VERSION ""

NS_ :

BS_:

BU_: BMS_Controller NF_Controller NF_Controllers

BO_ 2499762532 BATT_Diagnostic_Pack_A: 8 BMS_Controller
 SG_ BATT_01_vBrickOverSev m0 : 2|2@1+ (1,0) [0|3] ""  NF_Controller
 SG_ BATT_01_vBrickOverMod m0 : 0|2@1+ (1,0) [0|3] ""  NF_Controller
 SG_ BATT_01_vBrickOverWar m0 : 14|2@1+ (1,0) [0|3] ""  NF_Controller
 SG_ BATT_01_HostQuiet m0 : 12|2@1+ (1,0) [0|3] ""  NF_Controller
 SG_ BATT_01_vBrickUnderMod m0 : 10|2@1+ (1,0) [0|3] ""  NF_Controller
 SG_ BATT_01_vBrickUnderWar m0 : 8|2@1+ (1,0) [0|3] ""  NF_Controller
 SG_ BATT_01_TempModuleOverSev m0 : 22|2@1+ (1,0) [0|3] ""  NF_Controller
 SG_ BATT_01_TempModuleOverMod m0 : 20|2@1+ (1,0) [0|3] ""  NF_Controller
 SG_ BATT_01_TempModuleOverWar m0 : 18|2@1+ (1,0) [0|3] ""  NF_Controller
 SG_ BATT_01_TempModuleUnderSev m0 : 16|2@1+ (1,0) [0|3] ""  NF_Controller
 SG_ BATT_01_TempModuleUnderMod m0 : 30|2@1+ (1,0) [0|3] ""  NF_Controller
 SG_ BATT_01_TempModuleUnderWar m0 : 28|2@1+ (1,0) [0|3] ""  NF_Controller
 SG_ BATT_01_iOverchargesev m0 : 26|2@1+ (1,0) [0|3] ""  NF_Controller
 SG_ BATT_01_iOverdischargesev m0 : 24|2@1+ (1,0) [0|3] ""  NF_Controller
 SG_ BATT_01_iOverHardware m0 : 38|2@1+ (1,0) [0|3] ""  NF_Controller
 SG_ BATT_01_PosDcContStuckOpen m0 : 36|2@1+ (1,0) [0|3] ""  NF_Controller
 SG_ BATT_01_PosDcContWelded m0 : 34|2@1+ (1,0) [0|3] ""  NF_Controller
 SG_ BATT_01_NegDcContStuckOpen m0 : 32|2@1+ (1,0) [0|3] ""  NF_Controller
 SG_ BATT_01_NegDcContWelded m0 : 46|2@1+ (1,0) [0|3] ""  NF_Controller
 SG_ BATT_01_PrechgTooFast m0 : 44|2@1+ (1,0) [0|3] ""  NF_Controller
 SG_ BATT_01_PrechgContWelded m0 : 42|2@1+ (1,0) [0|3] ""  NF_Controller
 SG_ BATT_01_PrechgTimeout m0 : 40|2@1+ (1,0) [0|3] ""  NF_Controller
 SG_ BATT_01_PrechgContStuckOpen m0 : 54|2@1+ (1,0) [0|3] ""  NF_Controller
 SG_ BATT_01_ModuleImbalance m0 : 52|2@1+ (1,0) [0|3] ""  NF_Controller
 SG_ BATT_01_ModuleMIA m0 : 50|2@1+ (1,0) [0|3] ""  NF_Controller
 SG_ BATT_01_SensePackVoltError m0 : 48|2@1+ (1,0) [0|3] ""  NF_Controller
 SG_ BATT_01_SenseLoadVoltError m0 : 62|2@1+ (1,0) [0|3] ""  NF_Controller
 SG_ BATT_01_SenseShuntError m0 : 60|2@1+ (1,0) [0|3] ""  NF_Controller
 SG_ BATT_01_SenseFcVoltErrorr m0 : 58|2@1+ (1,0) [0|3] ""  NF_Controller
 SG_ BATT_01_Placeholder14 m0 : 56|2@1+ (1,0) [0|3] ""  NF_Controller
 SG_ BATT_02_vBrickOverSev m1 : 2|2@1+ (1,0) [0|3] ""  NF_Controller
 SG_ BATT_02_vBrickOverMod m1 : 0|2@1+ (1,0) [0|3] ""  NF_Controller
 SG_ BATT_02_vBrickOverWar m1 : 14|2@1+ (1,0) [0|3] ""  NF_Controller
 SG_ BATT_02_HostQuiet m1 : 12|2@1+ (1,0) [0|3] ""  NF_Controller
 SG_ BATT_02_vBrickUnderMod m1 : 10|2@1+ (1,0) [0|3] ""  NF_Controller
 SG_ BATT_02_vBrickUnderWar m1 : 8|2@1+ (1,0) [0|3] ""  NF_Controller
 SG_ BATT_02_TempModuleOverSev m1 : 22|2@1+ (1,0) [0|3] ""  NF_Controller
 SG_ BATT_02_TempModuleOverMod m1 : 20|2@1+ (1,0) [0|3] ""  NF_Controller
 SG_ BATT_02_TempModuleOverWar m1 : 18|2@1+ (1,0) [0|3] ""  NF_Controller
 SG_ BATT_02_TempModuleUnderSev m1 : 16|2@1+ (1,0) [0|3] ""  NF_Controller
 SG_ BATT_02_TempModuleUnderMod m1 : 30|2@1+ (1,0) [0|3] ""  NF_Controller
 SG_ BATT_02_TempModuleUnderWar m1 : 28|2@1+ (1,0) [0|3] ""  NF_Controller
 SG_ BATT_02_iOverchargesev m1 : 26|2@1+ (1,0) [0|3] ""  NF_Controller
 SG_ BATT_02_iOverdischargesev m1 : 24|2@1+ (1,0) [0|3] ""  NF_Controller
 SG_ BATT_02_iOverHardware m1 : 38|2@1+ (1,0) [0|3] ""  NF_Controller
 SG_ BATT_02_PosDcContStuckOpen m1 : 36|2@1+ (1,0) [0|3] ""  NF_Controller
 SG_ BATT_02_PosDcContWelded m1 : 34|2@1+ (1,0) [0|3] ""  NF_Controller
 SG_ BATT_02_NegDcContStuckOpen m1 : 32|2@1+ (1,0) [0|3] ""  NF_Controller
 SG_ BATT_02_NegDcContWelded m1 : 46|2@1+ (1,0) [0|3] ""  NF_Controller
 SG_ BATT_02_PrechgTooFast m1 : 44|2@1+ (1,0) [0|3] ""  NF_Controller
 SG_ BATT_02_PrechgContWelded m1 : 42|2@1+ (1,0) [0|3] ""  NF_Controller
 SG_ BATT_02_PrechgTimeout m1 : 40|2@1+ (1,0) [0|3] ""  NF_Controller
 SG_ BATT_02_PrechgContStuckOpen m1 : 54|2@1+ (1,0) [0|3] ""  NF_Controller
 SG_ BATT_02_ModuleImbalance m1 : 52|2@1+ (1,0) [0|3] ""  NF_Controller
 SG_ BATT_02_ModuleMIA m1 : 50|2@1+ (1,0) [0|3] ""  NF_Controller
 SG_ BATT_02_SensePackVoltError m1 : 48|2@1+ (1,0) [0|3] ""  NF_Controller
 SG_ BATT_02_SenseLoadVoltError m1 : 62|2@1+ (1,0) [0|3] ""  NF_Controller
 SG_ BATT_02_SenseShuntError m1 : 60|2@1+ (1,0) [0|3] ""  NF_Controller
 SG_ BATT_02_SenseFcVoltErrorr m1 : 58|2@1+ (1,0) [0|3] ""  NF_Controller
 SG_ BATT_02_Placeholder14 m1 : 56|2@1+ (1,0) [0|3] ""  NF_Controller
 SG_ BATT_03_vBrickOverSev m2 : 2|2@1+ (1,0) [0|3] ""  NF_Controller
 SG_ BATT_03_vBrickOverMod m2 : 0|2@1+ (1,0) [0|3] ""  NF_Controller
 SG_ BATT_03_vBrickOverWar m2 : 14|2@1+ (1,0) [0|3] ""  NF_Controller
 SG_ BATT_03_HostQuiet m2 : 12|2@1+ (1,0) [0|3] ""  NF_Controller
 SG_ BATT_03_vBrickUnderMod m2 : 10|2@1+ (1,0) [0|3] ""  NF_Controller
 SG_ BATT_03_vBrickUnderWar m2 : 8|2@1+ (1,0) [0|3] ""  NF_Controller
 SG_ BATT_03_TempModuleOverSev m2 : 22|2@1+ (1,0) [0|3] ""  NF_Controller
 SG_ BATT_03_TempModuleOverMod m2 : 20|2@1+ (1,0) [0|3] ""  NF_Controller
 SG_ BATT_03_TempModuleOverWar m2 : 18|2@1+ (1,0) [0|3] ""  NF_Controller
 SG_ BATT_03_TempModuleUnderSev m2 : 16|2@1+ (1,0) [0|3] ""  NF_Controller
 SG_ BATT_03_TempModuleUnderMod m2 : 30|2@1+ (1,0) [0|3] ""  NF_Controller
 SG_ BATT_03_TempModuleUnderWar m2 : 28|2@1+ (1,0) [0|3] ""  NF_Controller
 SG_ BATT_03_iOverchargesev m2 : 26|2@1+ (1,0) [0|3] ""  NF_Controller
 SG_ BATT_03_iOverdischargesev m2 : 24|2@1+ (1,0) [0|3] ""  NF_Controller
 SG_ BATT_03_iOverHardware m2 : 38|2@1+ (1,0) [0|3] ""  NF_Controller
 SG_ BATT_03_PosDcContStuckOpen m2 : 36|2@1+ (1,0) [0|3] ""  NF_Controller
 SG_ BATT_03_PosDcContWelded m2 : 34|2@1+ (1,0) [0|3] ""  NF_Controller
 SG_ BATT_03_NegDcContStuckOpen m2 : 32|2@1+ (1,0) [0|3] ""  NF_Controller
 SG_ BATT_03_NegDcContWelded m2 : 46|2@1+ (1,0) [0|3] ""  NF_Controller
 SG_ BATT_03_PrechgTooFast m2 : 44|2@1+ (1,0) [0|3] ""  NF_Controller
 SG_ BATT_03_PrechgContWelded m2 : 42|2@1+ (1,0) [0|3] ""  NF_Controller
 SG_ BATT_03_PrechgTimeout m2 : 40|2@1+ (1,0) [0|3] ""  NF_Controller
 SG_ BATT_03_PrechgContStuckOpen m2 : 54|2@1+ (1,0) [0|3] ""  NF_Controller
 SG_ BATT_03_ModuleImbalance m2 : 52|2@1+ (1,0) [0|3] ""  NF_Controller
 SG_ BATT_03_ModuleMIA m2 : 50|2@1+ (1,0) [0|3] ""  NF_Controller
 SG_ BATT_03_SensePackVoltError m2 : 48|2@1+ (1,0) [0|3] ""  NF_Controller
 SG_ BATT_03_SenseLoadVoltError m2 : 62|2@1+ (1,0) [0|3] ""  NF_Controller
 SG_ BATT_03_SenseShuntError m2 : 60|2@1+ (1,0) [0|3] ""  NF_Controller
 SG_ BATT_03_SenseFcVoltErrorr m2 : 58|2@1+ (1,0) [0|3] ""  NF_Controller
 SG_ BATT_03_Placeholder14 m2 : 56|2@1+ (1,0) [0|3] ""  NF_Controller
 SG_ BATT_04_vBrickOverSev m3 : 2|2@1+ (1,0) [0|3] ""  NF_Controller
 SG_ BATT_04_vBrickOverMod m3 : 0|2@1+ (1,0) [0|3] ""  NF_Controller
 SG_ BATT_04_vBrickOverWar m3 : 14|2@1+ (1,0) [0|3] ""  NF_Controller
 SG_ BATT_04_HostQuiet m3 : 12|2@1+ (1,0) [0|3] ""  NF_Controller
 SG_ BATT_04_vBrickUnderMod m3 : 10|2@1+ (1,0) [0|3] ""  NF_Controller
 SG_ BATT_04_vBrickUnderWar m3 : 8|2@1+ (1,0) [0|3] ""  NF_Controller
 SG_ BATT_04_TempModuleOverSev m3 : 22|2@1+ (1,0) [0|3] ""  NF_Controller
 SG_ BATT_04_TempModuleOverMod m3 : 20|2@1+ (1,0) [0|3] ""  NF_Controller
 SG_ BATT_04_TempModuleOverWar m3 : 18|2@1+ (1,0) [0|3] ""  NF_Controller
 SG_ BATT_04_TempModuleUnderSev m3 : 16|2@1+ (1,0) [0|3] ""  NF_Controller
 SG_ BATT_04_TempModuleUnderMod m3 : 30|2@1+ (1,0) [0|3] ""  NF_Controller
 SG_ BATT_04_TempModuleUnderWar m3 : 28|2@1+ (1,0) [0|3] ""  NF_Controller
 SG_ BATT_04_iOverchargesev m3 : 26|2@1+ (1,0) [0|3] ""  NF_Controller
 SG_ BATT_04_iOverdischargesev m3 : 24|2@1+ (1,0) [0|3] ""  NF_Controller
 SG_ BATT_04_iOverHardware m3 : 38|2@1+ (1,0) [0|3] ""  NF_Controller
 SG_ BATT_04_PosDcContStuckOpen m3 : 36|2@1+ (1,0) [0|3] ""  NF_Controller
 SG_ BATT_04_PosDcContWelded m3 : 34|2@1+ (1,0) [0|3] ""  NF_Controller
 SG_ BATT_04_NegDcContStuckOpen m3 : 32|2@1+ (1,0) [0|3] ""  NF_Controller
 SG_ BATT_04_NegDcContWelded m3 : 46|2@1+ (1,0) [0|3] ""  NF_Controller
 SG_ BATT_04_PrechgTooFast m3 : 44|2@1+ (1,0) [0|3] ""  NF_Controller
 SG_ BATT_04_PrechgContWelded m3 : 42|2@1+ (1,0) [0|3] ""  NF_Controller
 SG_ BATT_04_PrechgTimeout m3 : 40|2@1+ (1,0) [0|3] ""  NF_Controller
 SG_ BATT_04_PrechgContStuckOpen m3 : 54|2@1+ (1,0) [0|3] ""  NF_Controller
 SG_ BATT_04_ModuleImbalance m3 : 52|2@1+ (1,0) [0|3] ""  NF_Controller
 SG_ BATT_04_ModuleMIA m3 : 50|2@1+ (1,0) [0|3] ""  NF_Controller
 SG_ BATT_04_SensePackVoltError m3 : 48|2@1+ (1,0) [0|3] ""  NF_Controller
 SG_ BATT_04_SenseLoadVoltError m3 : 62|2@1+ (1,0) [0|3] ""  NF_Controller
 SG_ BATT_04_SenseShuntError m3 : 60|2@1+ (1,0) [0|3] ""  NF_Controller
 SG_ BATT_04_SenseFcVoltErrorr m3 : 58|2@1+ (1,0) [0|3] ""  NF_Controller
 SG_ BATT_04_Placeholder14 m3 : 56|2@1+ (1,0) [0|3] ""  NF_Controller
 SG_ BATT_05_vBrickOverSev m4 : 2|2@1+ (1,0) [0|3] ""  NF_Controller
 SG_ BATT_05_vBrickOverMod m4 : 0|2@1+ (1,0) [0|3] ""  NF_Controller
 SG_ BATT_05_vBrickOverWar m4 : 14|2@1+ (1,0) [0|3] ""  NF_Controller
 SG_ BATT_05_HostQuiet m4 : 12|2@1+ (1,0) [0|3] ""  NF_Controller
 SG_ BATT_05_vBrickUnderMod m4 : 10|2@1+ (1,0) [0|3] ""  NF_Controller
 SG_ BATT_05_vBrickUnderWar m4 : 8|2@1+ (1,0) [0|3] ""  NF_Controller
 SG_ BATT_05_TempModuleOverSev m4 : 22|2@1+ (1,0) [0|3] ""  NF_Controller
 SG_ BATT_05_TempModuleOverMod m4 : 20|2@1+ (1,0) [0|3] ""  NF_Controller
 SG_ BATT_05_TempModuleOverWar m4 : 18|2@1+ (1,0) [0|3] ""  NF_Controller
 SG_ BATT_05_TempModuleUnderSev m4 : 16|2@1+ (1,0) [0|3] ""  NF_Controller
 SG_ BATT_05_TempModuleUnderMod m4 : 30|2@1+ (1,0) [0|3] ""  NF_Controller
 SG_ BATT_05_TempModuleUnderWar m4 : 28|2@1+ (1,0) [0|3] ""  NF_Controller
 SG_ BATT_05_iOverchargesev m4 : 26|2@1+ (1,0) [0|3] ""  NF_Controller
 SG_ BATT_05_iOverdischargesev m4 : 24|2@1+ (1,0) [0|3] ""  NF_Controller
 SG_ BATT_05_iOverHardware m4 : 38|2@1+ (1,0) [0|3] ""  NF_Controller
 SG_ BATT_05_PosDcContStuckOpen m4 : 36|2@1+ (1,0) [0|3] ""  NF_Controller
 SG_ BATT_05_PosDcContWelded m4 : 34|2@1+ (1,0) [0|3] ""  NF_Controller
 SG_ BATT_05_NegDcContStuckOpen m4 : 32|2@1+ (1,0) [0|3] ""  NF_Controller
 SG_ BATT_05_NegDcContWelded m4 : 46|2@1+ (1,0) [0|3] ""  NF_Controller
 SG_ BATT_05_PrechgTooFast m4 : 44|2@1+ (1,0) [0|3] ""  NF_Controller
 SG_ BATT_05_PrechgContWelded m4 : 42|2@1+ (1,0) [0|3] ""  NF_Controller
 SG_ BATT_05_PrechgTimeout m4 : 40|2@1+ (1,0) [0|3] ""  NF_Controller
 SG_ BATT_05_PrechgContStuckOpen m4 : 54|2@1+ (1,0) [0|3] ""  NF_Controller
 SG_ BATT_05_ModuleImbalance m4 : 52|2@1+ (1,0) [0|3] ""  NF_Controller
 SG_ BATT_05_ModuleMIA m4 : 50|2@1+ (1,0) [0|3] ""  NF_Controller
 SG_ BATT_05_SensePackVoltError m4 : 48|2@1+ (1,0) [0|3] ""  NF_Controller
 SG_ BATT_05_SenseLoadVoltError m4 : 62|2@1+ (1,0) [0|3] ""  NF_Controller
 SG_ BATT_05_SenseShuntError m4 : 60|2@1+ (1,0) [0|3] ""  NF_Controller
 SG_ BATT_05_SenseFcVoltErrorr m4 : 58|2@1+ (1,0) [0|3] ""  NF_Controller
 SG_ BATT_05_Placeholder14 m4 : 56|2@1+ (1,0) [0|3] ""  NF_Controller
 SG_ BATT_06_vBrickOverSev m5 : 2|2@1+ (1,0) [0|3] ""  NF_Controller
 SG_ BATT_06_vBrickOverMod m5 : 0|2@1+ (1,0) [0|3] ""  NF_Controller
 SG_ BATT_06_vBrickOverWar m5 : 14|2@1+ (1,0) [0|3] ""  NF_Controller
 SG_ BATT_06_HostQuiet m5 : 12|2@1+ (1,0) [0|3] ""  NF_Controller
 SG_ BATT_06_vBrickUnderMod m5 : 10|2@1+ (1,0) [0|3] ""  NF_Controller
 SG_ BATT_06_vBrickUnderWar m5 : 8|2@1+ (1,0) [0|3] ""  NF_Controller
 SG_ BATT_06_TempModuleOverSev m5 : 22|2@1+ (1,0) [0|3] ""  NF_Controller
 SG_ BATT_06_TempModuleOverMod m5 : 20|2@1+ (1,0) [0|3] ""  NF_Controller
 SG_ BATT_06_TempModuleOverWar m5 : 18|2@1+ (1,0) [0|3] ""  NF_Controller
 SG_ BATT_06_TempModuleUnderSev m5 : 16|2@1+ (1,0) [0|3] ""  NF_Controller
 SG_ BATT_06_TempModuleUnderMod m5 : 30|2@1+ (1,0) [0|3] ""  NF_Controller
 SG_ BATT_06_TempModuleUnderWar m5 : 28|2@1+ (1,0) [0|3] ""  NF_Controller
 SG_ BATT_06_iOverchargesev m5 : 26|2@1+ (1,0) [0|3] ""  NF_Controller
 SG_ BATT_06_iOverdischargesev m5 : 24|2@1+ (1,0) [0|3] ""  NF_Controller
 SG_ BATT_06_iOverHardware m5 : 38|2@1+ (1,0) [0|3] ""  NF_Controller
 SG_ BATT_06_PosDcContStuckOpen m5 : 36|2@1+ (1,0) [0|3] ""  NF_Controller
 SG_ BATT_06_PosDcContWelded m5 : 34|2@1+ (1,0) [0|3] ""  NF_Controller
 SG_ BATT_06_NegDcContStuckOpen m5 : 32|2@1+ (1,0) [0|3] ""  NF_Controller
 SG_ BATT_06_NegDcContWelded m5 : 46|2@1+ (1,0) [0|3] ""  NF_Controller
 SG_ BATT_06_PrechgTooFast m5 : 44|2@1+ (1,0) [0|3] ""  NF_Controller
 SG_ BATT_06_PrechgContWelded m5 : 42|2@1+ (1,0) [0|3] ""  NF_Controller
 SG_ BATT_06_PrechgTimeout m5 : 40|2@1+ (1,0) [0|3] ""  NF_Controller
 SG_ BATT_06_PrechgContStuckOpen m5 : 54|2@1+ (1,0) [0|3] ""  NF_Controller
 SG_ BATT_06_ModuleImbalance m5 : 52|2@1+ (1,0) [0|3] ""  NF_Controller
 SG_ BATT_06_ModuleMIA m5 : 50|2@1+ (1,0) [0|3] ""  NF_Controller
 SG_ BATT_06_SensePackVoltError m5 : 48|2@1+ (1,0) [0|3] ""  NF_Controller
 SG_ BATT_06_SenseLoadVoltError m5 : 62|2@1+ (1,0) [0|3] ""  NF_Controller
 SG_ BATT_06_SenseShuntError m5 : 60|2@1+ (1,0) [0|3] ""  NF_Controller
 SG_ BATT_06_SenseFcVoltErrorr m5 : 58|2@1+ (1,0) [0|3] ""  NF_Controller
 SG_ BATT_06_Placeholder14 m5 : 56|2@1+ (1,0) [0|3] ""  NF_Controller
 SG_ BATT_07_vBrickOverSev m6 : 2|2@1+ (1,0) [0|3] ""  NF_Controller
 SG_ BATT_07_vBrickOverMod m6 : 0|2@1+ (1,0) [0|3] ""  NF_Controller
 SG_ BATT_07_vBrickOverWar m6 : 14|2@1+ (1,0) [0|3] ""  NF_Controller
 SG_ BATT_07_HostQuiet m6 : 12|2@1+ (1,0) [0|3] ""  NF_Controller
 SG_ BATT_07_vBrickUnderMod m6 : 10|2@1+ (1,0) [0|3] ""  NF_Controller
 SG_ BATT_07_vBrickUnderWar m6 : 8|2@1+ (1,0) [0|3] ""  NF_Controller
 SG_ BATT_07_TempModuleOverSev m6 : 22|2@1+ (1,0) [0|3] ""  NF_Controller
 SG_ BATT_07_TempModuleOverMod m6 : 20|2@1+ (1,0) [0|3] ""  NF_Controller
 SG_ BATT_07_TempModuleOverWar m6 : 18|2@1+ (1,0) [0|3] ""  NF_Controller
 SG_ BATT_07_TempModuleUnderSev m6 : 16|2@1+ (1,0) [0|3] ""  NF_Controller
 SG_ BATT_07_TempModuleUnderMod m6 : 30|2@1+ (1,0) [0|3] ""  NF_Controller
 SG_ BATT_07_TempModuleUnderWar m6 : 28|2@1+ (1,0) [0|3] ""  NF_Controller
 SG_ BATT_07_iOverchargesev m6 : 26|2@1+ (1,0) [0|3] ""  NF_Controller
 SG_ BATT_07_iOverdischargesev m6 : 24|2@1+ (1,0) [0|3] ""  NF_Controller
 SG_ BATT_07_iOverHardware m6 : 38|2@1+ (1,0) [0|3] ""  NF_Controller
 SG_ BATT_07_PosDcContStuckOpen m6 : 36|2@1+ (1,0) [0|3] ""  NF_Controller
 SG_ BATT_07_PosDcContWelded m6 : 34|2@1+ (1,0) [0|3] ""  NF_Controller
 SG_ BATT_07_NegDcContStuckOpen m6 : 32|2@1+ (1,0) [0|3] ""  NF_Controller
 SG_ BATT_07_NegDcContWelded m6 : 46|2@1+ (1,0) [0|3] ""  NF_Controller
 SG_ BATT_07_PrechgTooFast m6 : 44|2@1+ (1,0) [0|3] ""  NF_Controller
 SG_ BATT_07_PrechgContWelded m6 : 42|2@1+ (1,0) [0|3] ""  NF_Controller
 SG_ BATT_07_PrechgTimeout m6 : 40|2@1+ (1,0) [0|3] ""  NF_Controller
 SG_ BATT_07_PrechgContStuckOpen m6 : 54|2@1+ (1,0) [0|3] ""  NF_Controller
 SG_ BATT_07_ModuleImbalance m6 : 52|2@1+ (1,0) [0|3] ""  NF_Controller
 SG_ BATT_07_ModuleMIA m6 : 50|2@1+ (1,0) [0|3] ""  NF_Controller
 SG_ BATT_07_SensePackVoltError m6 : 48|2@1+ (1,0) [0|3] ""  NF_Controller
 SG_ BATT_07_SenseLoadVoltError m6 : 62|2@1+ (1,0) [0|3] ""  NF_Controller
 SG_ BATT_07_SenseShuntError m6 : 60|2@1+ (1,0) [0|3] ""  NF_Controller
 SG_ BATT_07_SenseFcVoltErrorr m6 : 58|2@1+ (1,0) [0|3] ""  NF_Controller
 SG_ BATT_07_Placeholder14 m6 : 56|2@1+ (1,0) [0|3] ""  NF_Controller
 SG_ BATT_08_vBrickOverSev m7 : 2|2@1+ (1,0) [0|3] ""  NF_Controller
 SG_ BATT_08_vBrickOverMod m7 : 0|2@1+ (1,0) [0|3] ""  NF_Controller
 SG_ BATT_08_vBrickOverWar m7 : 14|2@1+ (1,0) [0|3] ""  NF_Controller
 SG_ BATT_08_HostQuiet m7 : 12|2@1+ (1,0) [0|3] ""  NF_Controller
 SG_ BATT_08_vBrickUnderMod m7 : 10|2@1+ (1,0) [0|3] ""  NF_Controller
 SG_ BATT_08_vBrickUnderWar m7 : 8|2@1+ (1,0) [0|3] ""  NF_Controller
 SG_ BATT_08_TempModuleOverSev m7 : 22|2@1+ (1,0) [0|3] ""  NF_Controller
 SG_ BATT_08_TempModuleOverMod m7 : 20|2@1+ (1,0) [0|3] ""  NF_Controller
 SG_ BATT_08_TempModuleOverWar m7 : 18|2@1+ (1,0) [0|3] ""  NF_Controller
 SG_ BATT_08_TempModuleUnderSev m7 : 16|2@1+ (1,0) [0|3] ""  NF_Controller
 SG_ BATT_08_TempModuleUnderMod m7 : 30|2@1+ (1,0) [0|3] ""  NF_Controller
 SG_ BATT_08_TempModuleUnderWar m7 : 28|2@1+ (1,0) [0|3] ""  NF_Controller
 SG_ BATT_08_iOverchargesev m7 : 26|2@1+ (1,0) [0|3] ""  NF_Controller
 SG_ BATT_08_iOverdischargesev m7 : 24|2@1+ (1,0) [0|3] ""  NF_Controller
 SG_ BATT_08_iOverHardware m7 : 38|2@1+ (1,0) [0|3] ""  NF_Controller
 SG_ BATT_08_PosDcContStuckOpen m7 : 36|2@1+ (1,0) [0|3] ""  NF_Controller
 SG_ BATT_08_PosDcContWelded m7 : 34|2@1+ (1,0) [0|3] ""  NF_Controller
 SG_ BATT_08_NegDcContStuckOpen m7 : 32|2@1+ (1,0) [0|3] ""  NF_Controller
 SG_ BATT_08_NegDcContWelded m7 : 46|2@1+ (1,0) [0|3] ""  NF_Controller
 SG_ BATT_08_PrechgTooFast m7 : 44|2@1+ (1,0) [0|3] ""  NF_Controller
 SG_ BATT_08_PrechgContWelded m7 : 42|2@1+ (1,0) [0|3] ""  NF_Controller
 SG_ BATT_08_PrechgTimeout m7 : 40|2@1+ (1,0) [0|3] ""  NF_Controller
 SG_ BATT_08_PrechgContStuckOpen m7 : 54|2@1+ (1,0) [0|3] ""  NF_Controller
 SG_ BATT_08_ModuleImbalance m7 : 52|2@1+ (1,0) [0|3] ""  NF_Controller
 SG_ BATT_08_ModuleMIA m7 : 50|2@1+ (1,0) [0|3] ""  NF_Controller
 SG_ BATT_08_SensePackVoltError m7 : 48|2@1+ (1,0) [0|3] ""  NF_Controller
 SG_ BATT_08_SenseLoadVoltError m7 : 62|2@1+ (1,0) [0|3] ""  NF_Controller
 SG_ BATT_08_SenseShuntError m7 : 60|2@1+ (1,0) [0|3] ""  NF_Controller
 SG_ BATT_08_SenseFcVoltErrorr m7 : 58|2@1+ (1,0) [0|3] ""  NF_Controller
 SG_ BATT_08_Placeholder14 m7 : 56|2@1+ (1,0) [0|3] ""  NF_Controller
 SG_ BATT_09_vBrickOverSev m8 : 2|2@1+ (1,0) [0|3] ""  NF_Controller
 SG_ BATT_09_vBrickOverMod m8 : 0|2@1+ (1,0) [0|3] ""  NF_Controller
 SG_ BATT_09_vBrickOverWar m8 : 14|2@1+ (1,0) [0|3] ""  NF_Controller
 SG_ BATT_09_HostQuiet m8 : 12|2@1+ (1,0) [0|3] ""  NF_Controller
 SG_ BATT_09_vBrickUnderMod m8 : 10|2@1+ (1,0) [0|3] ""  NF_Controller
 SG_ BATT_09_vBrickUnderWar m8 : 8|2@1+ (1,0) [0|3] ""  NF_Controller
 SG_ BATT_09_TempModuleOverSev m8 : 22|2@1+ (1,0) [0|3] ""  NF_Controller
 SG_ BATT_09_TempModuleOverMod m8 : 20|2@1+ (1,0) [0|3] ""  NF_Controller
 SG_ BATT_09_TempModuleOverWar m8 : 18|2@1+ (1,0) [0|3] ""  NF_Controller
 SG_ BATT_09_TempModuleUnderSev m8 : 16|2@1+ (1,0) [0|3] ""  NF_Controller
 SG_ BATT_09_TempModuleUnderMod m8 : 30|2@1+ (1,0) [0|3] ""  NF_Controller
 SG_ BATT_09_TempModuleUnderWar m8 : 28|2@1+ (1,0) [0|3] ""  NF_Controller
 SG_ BATT_09_iOverchargesev m8 : 26|2@1+ (1,0) [0|3] ""  NF_Controller
 SG_ BATT_09_iOverdischargesev m8 : 24|2@1+ (1,0) [0|3] ""  NF_Controller
 SG_ BATT_09_iOverHardware m8 : 38|2@1+ (1,0) [0|3] ""  NF_Controller
 SG_ BATT_09_PosDcContStuckOpen m8 : 36|2@1+ (1,0) [0|3] ""  NF_Controller
 SG_ BATT_09_PosDcContWelded m8 : 34|2@1+ (1,0) [0|3] ""  NF_Controller
 SG_ BATT_09_NegDcContStuckOpen m8 : 32|2@1+ (1,0) [0|3] ""  NF_Controller
 SG_ BATT_09_NegDcContWelded m8 : 46|2@1+ (1,0) [0|3] ""  NF_Controller
 SG_ BATT_09_PrechgTooFast m8 : 44|2@1+ (1,0) [0|3] ""  NF_Controller
 SG_ BATT_09_PrechgContWelded m8 : 42|2@1+ (1,0) [0|3] ""  NF_Controller
 SG_ BATT_09_PrechgTimeout m8 : 40|2@1+ (1,0) [0|3] ""  NF_Controller
 SG_ BATT_09_PrechgContStuckOpen m8 : 54|2@1+ (1,0) [0|3] ""  NF_Controller
 SG_ BATT_09_ModuleImbalance m8 : 52|2@1+ (1,0) [0|3] ""  NF_Controller
 SG_ BATT_09_ModuleMIA m8 : 50|2@1+ (1,0) [0|3] ""  NF_Controller
 SG_ BATT_09_SensePackVoltError m8 : 48|2@1+ (1,0) [0|3] ""  NF_Controller
 SG_ BATT_09_SenseLoadVoltError m8 : 62|2@1+ (1,0) [0|3] ""  NF_Controller
 SG_ BATT_09_SenseShuntError m8 : 60|2@1+ (1,0) [0|3] ""  NF_Controller
 SG_ BATT_09_SenseFcVoltErrorr m8 : 58|2@1+ (1,0) [0|3] ""  NF_Controller
 SG_ BATT_09_Placeholder14 m8 : 56|2@1+ (1,0) [0|3] ""  NF_Controller
 SG_ BATT_10_vBrickOverSev m9 : 2|2@1+ (1,0) [0|3] ""  NF_Controller
 SG_ BATT_10_vBrickOverMod m9 : 0|2@1+ (1,0) [0|3] ""  NF_Controller
 SG_ BATT_10_vBrickOverWar m9 : 14|2@1+ (1,0) [0|3] ""  NF_Controller
 SG_ BATT_10_HostQuiet m9 : 12|2@1+ (1,0) [0|3] ""  NF_Controller
 SG_ BATT_10_vBrickUnderMod m9 : 10|2@1+ (1,0) [0|3] ""  NF_Controller
 SG_ BATT_10_vBrickUnderWar m9 : 8|2@1+ (1,0) [0|3] ""  NF_Controller
 SG_ BATT_10_TempModuleOverSev m9 : 22|2@1+ (1,0) [0|3] ""  NF_Controller
 SG_ BATT_10_TempModuleOverMod m9 : 20|2@1+ (1,0) [0|3] ""  NF_Controller
 SG_ BATT_10_TempModuleOverWar m9 : 18|2@1+ (1,0) [0|3] ""  NF_Controller
 SG_ BATT_10_TempModuleUnderSev m9 : 16|2@1+ (1,0) [0|3] ""  NF_Controller
 SG_ BATT_10_TempModuleUnderMod m9 : 30|2@1+ (1,0) [0|3] ""  NF_Controller
 SG_ BATT_10_TempModuleUnderWar m9 : 28|2@1+ (1,0) [0|3] ""  NF_Controller
 SG_ BATT_10_iOverchargesev m9 : 26|2@1+ (1,0) [0|3] ""  NF_Controller
 SG_ BATT_10_iOverdischargesev m9 : 24|2@1+ (1,0) [0|3] ""  NF_Controller
 SG_ BATT_10_iOverHardware m9 : 38|2@1+ (1,0) [0|3] ""  NF_Controller
 SG_ BATT_10_PosDcContStuckOpen m9 : 36|2@1+ (1,0) [0|3] ""  NF_Controller
 SG_ BATT_10_PosDcContWelded m9 : 34|2@1+ (1,0) [0|3] ""  NF_Controller
 SG_ BATT_10_NegDcContStuckOpen m9 : 32|2@1+ (1,0) [0|3] ""  NF_Controller
 SG_ BATT_10_NegDcContWelded m9 : 46|2@1+ (1,0) [0|3] ""  NF_Controller
 SG_ BATT_10_PrechgTooFast m9 : 44|2@1+ (1,0) [0|3] ""  NF_Controller
 SG_ BATT_10_PrechgContWelded m9 : 42|2@1+ (1,0) [0|3] ""  NF_Controller
 SG_ BATT_10_PrechgTimeout m9 : 40|2@1+ (1,0) [0|3] ""  NF_Controller
 SG_ BATT_10_PrechgContStuckOpen m9 : 54|2@1+ (1,0) [0|3] ""  NF_Controller
 SG_ BATT_10_ModuleImbalance m9 : 52|2@1+ (1,0) [0|3] ""  NF_Controller
 SG_ BATT_10_ModuleMIA m9 : 50|2@1+ (1,0) [0|3] ""  NF_Controller
 SG_ BATT_10_SensePackVoltError m9 : 48|2@1+ (1,0) [0|3] ""  NF_Controller
 SG_ BATT_10_SenseLoadVoltError m9 : 62|2@1+ (1,0) [0|3] ""  NF_Controller
 SG_ BATT_10_SenseShuntError m9 : 60|2@1+ (1,0) [0|3] ""  NF_Controller
 SG_ BATT_10_SenseFcVoltErrorr m9 : 58|2@1+ (1,0) [0|3] ""  NF_Controller
 SG_ BATT_10_Placeholder14 m9 : 56|2@1+ (1,0) [0|3] ""  NF_Controller
 SG_ BATT_11_vBrickOverSev m10 : 2|2@1+ (1,0) [0|3] ""  NF_Controller
 SG_ BATT_11_vBrickOverMod m10 : 0|2@1+ (1,0) [0|3] ""  NF_Controller
 SG_ BATT_11_vBrickOverWar m10 : 14|2@1+ (1,0) [0|3] ""  NF_Controller
 SG_ BATT_11_HostQuiet m10 : 12|2@1+ (1,0) [0|3] ""  NF_Controller
 SG_ BATT_11_vBrickUnderMod m10 : 10|2@1+ (1,0) [0|3] ""  NF_Controller
 SG_ BATT_11_vBrickUnderWar m10 : 8|2@1+ (1,0) [0|3] ""  NF_Controller
 SG_ BATT_11_TempModuleOverSev m10 : 22|2@1+ (1,0) [0|3] ""  NF_Controller
 SG_ BATT_11_TempModuleOverMod m10 : 20|2@1+ (1,0) [0|3] ""  NF_Controller
 SG_ BATT_11_TempModuleOverWar m10 : 18|2@1+ (1,0) [0|3] ""  NF_Controller
 SG_ BATT_11_TempModuleUnderSev m10 : 16|2@1+ (1,0) [0|3] ""  NF_Controller
 SG_ BATT_11_TempModuleUnderMod m10 : 30|2@1+ (1,0) [0|3] ""  NF_Controller
 SG_ BATT_11_TempModuleUnderWar m10 : 28|2@1+ (1,0) [0|3] ""  NF_Controller
 SG_ BATT_11_iOverchargesev m10 : 26|2@1+ (1,0) [0|3] ""  NF_Controller
 SG_ BATT_11_iOverdischargesev m10 : 24|2@1+ (1,0) [0|3] ""  NF_Controller
 SG_ BATT_11_iOverHardware m10 : 38|2@1+ (1,0) [0|3] ""  NF_Controller
 SG_ BATT_11_PosDcContStuckOpen m10 : 36|2@1+ (1,0) [0|3] ""  NF_Controller
 SG_ BATT_11_PosDcContWelded m10 : 34|2@1+ (1,0) [0|3] ""  NF_Controller
 SG_ BATT_11_NegDcContStuckOpen m10 : 32|2@1+ (1,0) [0|3] ""  NF_Controller
 SG_ BATT_11_NegDcContWelded m10 : 46|2@1+ (1,0) [0|3] ""  NF_Controller
 SG_ BATT_11_PrechgTooFast m10 : 44|2@1+ (1,0) [0|3] ""  NF_Controller
 SG_ BATT_11_PrechgContWelded m10 : 42|2@1+ (1,0) [0|3] ""  NF_Controller
 SG_ BATT_11_PrechgTimeout m10 : 40|2@1+ (1,0) [0|3] ""  NF_Controller
 SG_ BATT_11_PrechgContStuckOpen m10 : 54|2@1+ (1,0) [0|3] ""  NF_Controller
 SG_ BATT_11_ModuleImbalance m10 : 52|2@1+ (1,0) [0|3] ""  NF_Controller
 SG_ BATT_11_ModuleMIA m10 : 50|2@1+ (1,0) [0|3] ""  NF_Controller
 SG_ BATT_11_SensePackVoltError m10 : 48|2@1+ (1,0) [0|3] ""  NF_Controller
 SG_ BATT_11_SenseLoadVoltError m10 : 62|2@1+ (1,0) [0|3] ""  NF_Controller
 SG_ BATT_11_SenseShuntError m10 : 60|2@1+ (1,0) [0|3] ""  NF_Controller
 SG_ BATT_11_SenseFcVoltErrorr m10 : 58|2@1+ (1,0) [0|3] ""  NF_Controller
 SG_ BATT_11_Placeholder14 m10 : 56|2@1+ (1,0) [0|3] ""  NF_Controller
 SG_ BATT_12_vBrickOverSev m11 : 2|2@1+ (1,0) [0|3] ""  NF_Controller
 SG_ BATT_12_vBrickOverMod m11 : 0|2@1+ (1,0) [0|3] ""  NF_Controller
 SG_ BATT_12_vBrickOverWar m11 : 14|2@1+ (1,0) [0|3] ""  NF_Controller
 SG_ BATT_12_HostQuiet m11 : 12|2@1+ (1,0) [0|3] ""  NF_Controller
 SG_ BATT_12_vBrickUnderMod m11 : 10|2@1+ (1,0) [0|3] ""  NF_Controller
 SG_ BATT_12_vBrickUnderWar m11 : 8|2@1+ (1,0) [0|3] ""  NF_Controller
 SG_ BATT_12_TempModuleOverSev m11 : 22|2@1+ (1,0) [0|3] ""  NF_Controller
 SG_ BATT_12_TempModuleOverMod m11 : 20|2@1+ (1,0) [0|3] ""  NF_Controller
 SG_ BATT_12_TempModuleOverWar m11 : 18|2@1+ (1,0) [0|3] ""  NF_Controller
 SG_ BATT_12_TempModuleUnderSev m11 : 16|2@1+ (1,0) [0|3] ""  NF_Controller
 SG_ BATT_12_TempModuleUnderMod m11 : 30|2@1+ (1,0) [0|3] ""  NF_Controller
 SG_ BATT_12_TempModuleUnderWar m11 : 28|2@1+ (1,0) [0|3] ""  NF_Controller
 SG_ BATT_12_iOverchargesev m11 : 26|2@1+ (1,0) [0|3] ""  NF_Controller
 SG_ BATT_12_iOverdischargesev m11 : 24|2@1+ (1,0) [0|3] ""  NF_Controller
 SG_ BATT_12_iOverHardware m11 : 38|2@1+ (1,0) [0|3] ""  NF_Controller
 SG_ BATT_12_PosDcContStuckOpen m11 : 36|2@1+ (1,0) [0|3] ""  NF_Controller
 SG_ BATT_12_PosDcContWelded m11 : 34|2@1+ (1,0) [0|3] ""  NF_Controller
 SG_ BATT_12_NegDcContStuckOpen m11 : 32|2@1+ (1,0) [0|3] ""  NF_Controller
 SG_ BATT_12_NegDcContWelded m11 : 46|2@1+ (1,0) [0|3] ""  NF_Controller
 SG_ BATT_12_PrechgTooFast m11 : 44|2@1+ (1,0) [0|3] ""  NF_Controller
 SG_ BATT_12_PrechgContWelded m11 : 42|2@1+ (1,0) [0|3] ""  NF_Controller
 SG_ BATT_12_PrechgTimeout m11 : 40|2@1+ (1,0) [0|3] ""  NF_Controller
 SG_ BATT_12_PrechgContStuckOpen m11 : 54|2@1+ (1,0) [0|3] ""  NF_Controller
 SG_ BATT_12_ModuleImbalance m11 : 52|2@1+ (1,0) [0|3] ""  NF_Controller
 SG_ BATT_12_ModuleMIA m11 : 50|2@1+ (1,0) [0|3] ""  NF_Controller
 SG_ BATT_12_SensePackVoltError m11 : 48|2@1+ (1,0) [0|3] ""  NF_Controller
 SG_ BATT_12_SenseLoadVoltError m11 : 62|2@1+ (1,0) [0|3] ""  NF_Controller
 SG_ BATT_12_SenseShuntError m11 : 60|2@1+ (1,0) [0|3] ""  NF_Controller
 SG_ BATT_12_SenseFcVoltErrorr m11 : 58|2@1+ (1,0) [0|3] ""  NF_Controller
 SG_ BATT_12_Placeholder14 m11 : 56|2@1+ (1,0) [0|3] ""  NF_Controller
 SG_ BATT_13_vBrickOverSev m12 : 2|2@1+ (1,0) [0|3] ""  NF_Controller
 SG_ BATT_13_vBrickOverMod m12 : 0|2@1+ (1,0) [0|3] ""  NF_Controller
 SG_ BATT_13_vBrickOverWar m12 : 14|2@1+ (1,0) [0|3] ""  NF_Controller
 SG_ BATT_13_HostQuiet m12 : 12|2@1+ (1,0) [0|3] ""  NF_Controller
 SG_ BATT_13_vBrickUnderMod m12 : 10|2@1+ (1,0) [0|3] ""  NF_Controller
 SG_ BATT_13_vBrickUnderWar m12 : 8|2@1+ (1,0) [0|3] ""  NF_Controller
 SG_ BATT_13_TempModuleOverSev m12 : 22|2@1+ (1,0) [0|3] ""  NF_Controller
 SG_ BATT_13_TempModuleOverMod m12 : 20|2@1+ (1,0) [0|3] ""  NF_Controller
 SG_ BATT_13_TempModuleOverWar m12 : 18|2@1+ (1,0) [0|3] ""  NF_Controller
 SG_ BATT_13_TempModuleUnderSev m12 : 16|2@1+ (1,0) [0|3] ""  NF_Controller
 SG_ BATT_13_TempModuleUnderMod m12 : 30|2@1+ (1,0) [0|3] ""  NF_Controller
 SG_ BATT_13_TempModuleUnderWar m12 : 28|2@1+ (1,0) [0|3] ""  NF_Controller
 SG_ BATT_13_iOverchargesev m12 : 26|2@1+ (1,0) [0|3] ""  NF_Controller
 SG_ BATT_13_iOverdischargesev m12 : 24|2@1+ (1,0) [0|3] ""  NF_Controller
 SG_ BATT_13_iOverHardware m12 : 38|2@1+ (1,0) [0|3] ""  NF_Controller
 SG_ BATT_13_PosDcContStuckOpen m12 : 36|2@1+ (1,0) [0|3] ""  NF_Controller
 SG_ BATT_13_PosDcContWelded m12 : 34|2@1+ (1,0) [0|3] ""  NF_Controller
 SG_ BATT_13_NegDcContStuckOpen m12 : 32|2@1+ (1,0) [0|3] ""  NF_Controller
 SG_ BATT_13_NegDcContWelded m12 : 46|2@1+ (1,0) [0|3] ""  NF_Controller
 SG_ BATT_13_PrechgTooFast m12 : 44|2@1+ (1,0) [0|3] ""  NF_Controller
 SG_ BATT_13_PrechgContWelded m12 : 42|2@1+ (1,0) [0|3] ""  NF_Controller
 SG_ BATT_13_PrechgTimeout m12 : 40|2@1+ (1,0) [0|3] ""  NF_Controller
 SG_ BATT_13_PrechgContStuckOpen m12 : 54|2@1+ (1,0) [0|3] ""  NF_Controller
 SG_ BATT_13_ModuleImbalance m12 : 52|2@1+ (1,0) [0|3] ""  NF_Controller
 SG_ BATT_13_ModuleMIA m12 : 50|2@1+ (1,0) [0|3] ""  NF_Controller
 SG_ BATT_13_SensePackVoltError m12 : 48|2@1+ (1,0) [0|3] ""  NF_Controller
 SG_ BATT_13_SenseLoadVoltError m12 : 62|2@1+ (1,0) [0|3] ""  NF_Controller
 SG_ BATT_13_SenseShuntError m12 : 60|2@1+ (1,0) [0|3] ""  NF_Controller
 SG_ BATT_13_SenseFcVoltErrorr m12 : 58|2@1+ (1,0) [0|3] ""  NF_Controller
 SG_ BATT_13_Placeholder14 m12 : 56|2@1+ (1,0) [0|3] ""  NF_Controller
 SG_ BATT_14_vBrickOverSev m13 : 2|2@1+ (1,0) [0|3] ""  NF_Controller
 SG_ BATT_14_vBrickOverMod m13 : 0|2@1+ (1,0) [0|3] ""  NF_Controller
 SG_ BATT_14_vBrickOverWar m13 : 14|2@1+ (1,0) [0|3] ""  NF_Controller
 SG_ BATT_14_HostQuiet m13 : 12|2@1+ (1,0) [0|3] ""  NF_Controller
 SG_ BATT_14_vBrickUnderMod m13 : 10|2@1+ (1,0) [0|3] ""  NF_Controller
 SG_ BATT_14_vBrickUnderWar m13 : 8|2@1+ (1,0) [0|3] ""  NF_Controller
 SG_ BATT_14_TempModuleOverSev m13 : 22|2@1+ (1,0) [0|3] ""  NF_Controller
 SG_ BATT_14_TempModuleOverMod m13 : 20|2@1+ (1,0) [0|3] ""  NF_Controller
 SG_ BATT_14_TempModuleOverWar m13 : 18|2@1+ (1,0) [0|3] ""  NF_Controller
 SG_ BATT_14_TempModuleUnderSev m13 : 16|2@1+ (1,0) [0|3] ""  NF_Controller
 SG_ BATT_14_TempModuleUnderMod m13 : 30|2@1+ (1,0) [0|3] ""  NF_Controller
 SG_ BATT_14_TempModuleUnderWar m13 : 28|2@1+ (1,0) [0|3] ""  NF_Controller
 SG_ BATT_14_iOverchargesev m13 : 26|2@1+ (1,0) [0|3] ""  NF_Controller
 SG_ BATT_14_iOverdischargesev m13 : 24|2@1+ (1,0) [0|3] ""  NF_Controller
 SG_ BATT_14_iOverHardware m13 : 38|2@1+ (1,0) [0|3] ""  NF_Controller
 SG_ BATT_14_PosDcContStuckOpen m13 : 36|2@1+ (1,0) [0|3] ""  NF_Controller
 SG_ BATT_14_PosDcContWelded m13 : 34|2@1+ (1,0) [0|3] ""  NF_Controller
 SG_ BATT_14_NegDcContStuckOpen m13 : 32|2@1+ (1,0) [0|3] ""  NF_Controller
 SG_ BATT_14_NegDcContWelded m13 : 46|2@1+ (1,0) [0|3] ""  NF_Controller
 SG_ BATT_14_PrechgTooFast m13 : 44|2@1+ (1,0) [0|3] ""  NF_Controller
 SG_ BATT_14_PrechgContWelded m13 : 42|2@1+ (1,0) [0|3] ""  NF_Controller
 SG_ BATT_14_PrechgTimeout m13 : 40|2@1+ (1,0) [0|3] ""  NF_Controller
 SG_ BATT_14_PrechgContStuckOpen m13 : 54|2@1+ (1,0) [0|3] ""  NF_Controller
 SG_ BATT_14_ModuleImbalance m13 : 52|2@1+ (1,0) [0|3] ""  NF_Controller
 SG_ BATT_14_ModuleMIA m13 : 50|2@1+ (1,0) [0|3] ""  NF_Controller
 SG_ BATT_14_SensePackVoltError m13 : 48|2@1+ (1,0) [0|3] ""  NF_Controller
 SG_ BATT_14_SenseLoadVoltError m13 : 62|2@1+ (1,0) [0|3] ""  NF_Controller
 SG_ BATT_14_SenseShuntError m13 : 60|2@1+ (1,0) [0|3] ""  NF_Controller
 SG_ BATT_14_SenseFcVoltErrorr m13 : 58|2@1+ (1,0) [0|3] ""  NF_Controller
 SG_ BATT_14_Placeholder14 m13 : 56|2@1+ (1,0) [0|3] ""  NF_Controller
 SG_ BATT_15_vBrickOverSev m14 : 2|2@1+ (1,0) [0|3] ""  NF_Controller
 SG_ BATT_15_vBrickOverMod m14 : 0|2@1+ (1,0) [0|3] ""  NF_Controller
 SG_ BATT_15_vBrickOverWar m14 : 14|2@1+ (1,0) [0|3] ""  NF_Controller
 SG_ BATT_15_HostQuiet m14 : 12|2@1+ (1,0) [0|3] ""  NF_Controller
 SG_ BATT_15_vBrickUnderMod m14 : 10|2@1+ (1,0) [0|3] ""  NF_Controller
 SG_ BATT_15_vBrickUnderWar m14 : 8|2@1+ (1,0) [0|3] ""  NF_Controller
 SG_ BATT_15_TempModuleOverSev m14 : 22|2@1+ (1,0) [0|3] ""  NF_Controller
 SG_ BATT_15_TempModuleOverMod m14 : 20|2@1+ (1,0) [0|3] ""  NF_Controller
 SG_ BATT_15_TempModuleOverWar m14 : 18|2@1+ (1,0) [0|3] ""  NF_Controller
 SG_ BATT_15_TempModuleUnderSev m14 : 16|2@1+ (1,0) [0|3] ""  NF_Controller
 SG_ BATT_15_TempModuleUnderMod m14 : 30|2@1+ (1,0) [0|3] ""  NF_Controller
 SG_ BATT_15_TempModuleUnderWar m14 : 28|2@1+ (1,0) [0|3] ""  NF_Controller
 SG_ BATT_15_iOverchargesev m14 : 26|2@1+ (1,0) [0|3] ""  NF_Controller
 SG_ BATT_15_iOverdischargesev m14 : 24|2@1+ (1,0) [0|3] ""  NF_Controller
 SG_ BATT_15_iOverHardware m14 : 38|2@1+ (1,0) [0|3] ""  NF_Controller
 SG_ BATT_15_PosDcContStuckOpen m14 : 36|2@1+ (1,0) [0|3] ""  NF_Controller
 SG_ BATT_15_PosDcContWelded m14 : 34|2@1+ (1,0) [0|3] ""  NF_Controller
 SG_ BATT_15_NegDcContStuckOpen m14 : 32|2@1+ (1,0) [0|3] ""  NF_Controller
 SG_ BATT_15_NegDcContWelded m14 : 46|2@1+ (1,0) [0|3] ""  NF_Controller
 SG_ BATT_15_PrechgTooFast m14 : 44|2@1+ (1,0) [0|3] ""  NF_Controller
 SG_ BATT_15_PrechgContWelded m14 : 42|2@1+ (1,0) [0|3] ""  NF_Controller
 SG_ BATT_15_PrechgTimeout m14 : 40|2@1+ (1,0) [0|3] ""  NF_Controller
 SG_ BATT_15_PrechgContStuckOpen m14 : 54|2@1+ (1,0) [0|3] ""  NF_Controller
 SG_ BATT_15_ModuleImbalance m14 : 52|2@1+ (1,0) [0|3] ""  NF_Controller
 SG_ BATT_15_ModuleMIA m14 : 50|2@1+ (1,0) [0|3] ""  NF_Controller
 SG_ BATT_15_SensePackVoltError m14 : 48|2@1+ (1,0) [0|3] ""  NF_Controller
 SG_ BATT_15_SenseLoadVoltError m14 : 62|2@1+ (1,0) [0|3] ""  NF_Controller
 SG_ BATT_15_SenseShuntError m14 : 60|2@1+ (1,0) [0|3] ""  NF_Controller
 SG_ BATT_15_SenseFcVoltErrorr m14 : 58|2@1+ (1,0) [0|3] ""  NF_Controller
 SG_ BATT_15_Placeholder14 m14 : 56|2@1+ (1,0) [0|3] ""  NF_Controller
 SG_ multiplexor_batt_diag_A M : 4|4@1+ (1,0) [0|15] ""  NF_Controller

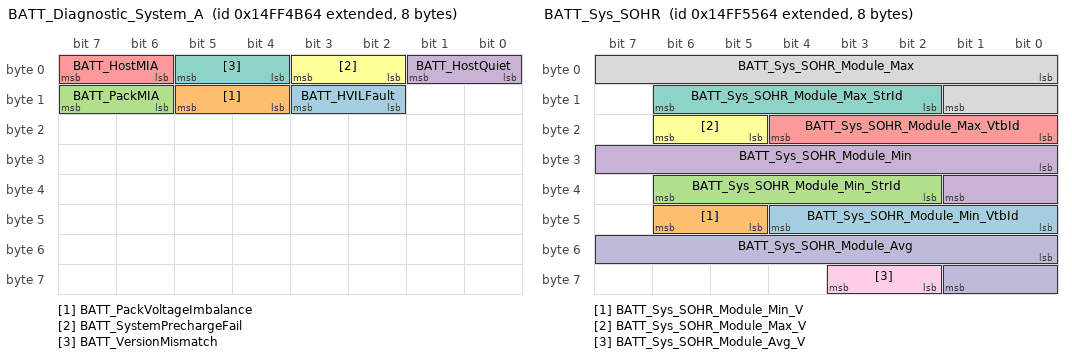
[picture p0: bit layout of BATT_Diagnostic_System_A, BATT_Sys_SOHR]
BO_ 2499758948 BATT_Diagnostic_System_A: 8 BMS_Controller
 SG_ BATT_HVILFault : 10|2@1+ (1,0) [0|3] "" Vector__XXX
 SG_ BATT_PackVoltageImbalance : 12|2@1+ (1,0) [0|3] ""  NF_Controller
 SG_ BATT_PackMIA : 14|2@1+ (1,0) [0|3] ""  NF_Controller
 SG_ BATT_HostQuiet : 0|2@1+ (1,0) [0|3] ""  NF_Controller
 SG_ BATT_HostMIA : 6|2@1+ (1,0) [0|3] ""  NF_Controller
 SG_ BATT_SystemPrechargeFail : 2|2@1+ (1,0) [0|3] ""  NF_Controller
 SG_ BATT_VersionMismatch : 4|2@1+ (1,0) [0|3] ""  NF_Controller

BO_ 2499761508 BATT_Sys_SOHR: 8 BMS_Controller
 SG_ BATT_Sys_SOHR_Module_Min_VtbId : 40|5@1+ (1,0) [0|29] "Index"  NF_Controller
 SG_ BATT_Sys_SOHR_Module_Min_V : 45|2@1+ (1,0) [0|3] ""  NF_Controller
 SG_ BATT_Sys_SOHR_Module_Min_StrId : 34|5@1+ (1,101) [101|124] "Index"  NF_Controller
 SG_ BATT_Sys_SOHR_Module_Min : 24|10@1+ (0.1,0) [0|100] "%"  NF_Controller
 SG_ BATT_Sys_SOHR_Module_Max_VtbId : 16|5@1+ (1,0) [0|29] "Index"  NF_Controller
 SG_ BATT_Sys_SOHR_Module_Max_V : 21|2@1+ (1,0) [0|3] ""  NF_Controller
 SG_ BATT_Sys_SOHR_Module_Max_StrId : 10|5@1+ (1,101) [101|124] "Index"  NF_Controller
 SG_ BATT_Sys_SOHR_Module_Max : 0|10@1+ (0.1,0) [0|100] "%"  NF_Controller
 SG_ BATT_Sys_SOHR_Module_Avg_V : 58|2@1+ (1,0) [0|3] ""  NF_Controller
 SG_ BATT_Sys_SOHR_Module_Avg : 48|10@1+ (0.1,0) [0|100] "%"  NF_Controller

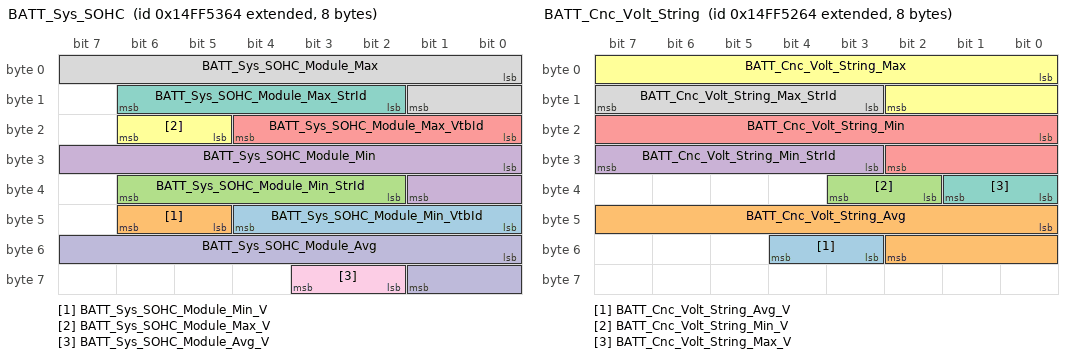
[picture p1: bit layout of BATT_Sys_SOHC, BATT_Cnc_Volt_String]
BO_ 2499760996 BATT_Sys_SOHC: 8 BMS_Controller
 SG_ BATT_Sys_SOHC_Module_Min_VtbId : 40|5@1+ (1,0) [0|29] "Index"  NF_Controller
 SG_ BATT_Sys_SOHC_Module_Min_V : 45|2@1+ (1,0) [0|3] ""  NF_Controller
 SG_ BATT_Sys_SOHC_Module_Min_StrId : 34|5@1+ (1,101) [101|124] "Index"  NF_Controller
 SG_ BATT_Sys_SOHC_Module_Min : 24|10@1+ (0.1,0) [0|100] "%"  NF_Controller
 SG_ BATT_Sys_SOHC_Module_Max_VtbId : 16|5@1+ (1,0) [0|29] "Index"  NF_Controller
 SG_ BATT_Sys_SOHC_Module_Max_V : 21|2@1+ (1,0) [0|3] ""  NF_Controller
 SG_ BATT_Sys_SOHC_Module_Max_StrId : 10|5@1+ (1,101) [101|124] "Index"  NF_Controller
 SG_ BATT_Sys_SOHC_Module_Max : 0|10@1+ (0.1,0) [0|100] "%"  NF_Controller
 SG_ BATT_Sys_SOHC_Module_Avg_V : 58|2@1+ (1,0) [0|3] ""  NF_Controller
 SG_ BATT_Sys_SOHC_Module_Avg : 48|10@1+ (0.1,0) [0|100] "%"  NF_Controller

BO_ 2499760740 BATT_Cnc_Volt_String: 8 BMS_Controller
 SG_ BATT_Cnc_Volt_String_Avg_V : 51|2@1+ (1,0) [0|3] ""  NF_Controller
 SG_ BATT_Cnc_Volt_String_Avg : 40|11@1+ (1,0) [0|1250] "Volts"  NF_Controller
 SG_ BATT_Cnc_Volt_String_Min_V : 34|2@1+ (1,0) [0|3] ""  NF_Controller
 SG_ BATT_Cnc_Volt_String_Min_StrId : 27|5@1+ (1,101) [101|124] "Index"  NF_Controller
 SG_ BATT_Cnc_Volt_String_Min : 16|11@1+ (1,0) [0|1250] "Volts"  NF_Controller
 SG_ BATT_Cnc_Volt_String_Max : 0|11@1+ (1,0) [0|1250] "Volts"  NF_Controller
 SG_ BATT_Cnc_Volt_String_Max_V : 32|2@1+ (1,0) [0|3] ""  NF_Controller
 SG_ BATT_Cnc_Volt_String_Max_StrId : 11|5@1+ (1,101) [101|124] "Index"  NF_Controller

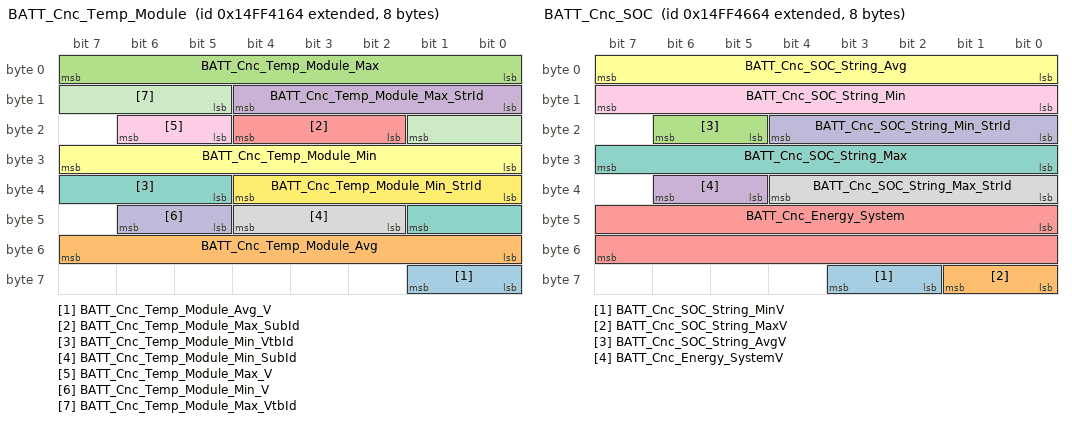
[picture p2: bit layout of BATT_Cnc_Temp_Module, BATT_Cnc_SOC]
BO_ 2499756388 BATT_Cnc_Temp_Module: 8 BMS_Controller
 SG_ BATT_Cnc_Temp_Module_Avg_V : 56|2@1+ (1,0) [0|3] ""  NF_Controller
 SG_ BATT_Cnc_Temp_Module_Avg : 48|8@1+ (1,-40) [-40|200] "Degree C"  NF_Controller
 SG_ BATT_Cnc_Temp_Module_Max : 0|8@1+ (1,-40) [-40|200] "Degree C"  NF_Controller
 SG_ BATT_Cnc_Temp_Module_Max_StrId : 8|5@1+ (1,101) [101|124] "Index"  NF_Controller
 SG_ BATT_Cnc_Temp_Module_Max_SubId : 18|3@1+ (1,0) [1|4] "Index"  NF_Controller
 SG_ BATT_Cnc_Temp_Module_Min : 24|8@1+ (1,-40) [-40|200] "Degree C"  NF_Controller
 SG_ BATT_Cnc_Temp_Module_Min_VtbId : 37|5@1+ (1,0) [0|29] "Index"  NF_Controller
 SG_ BATT_Cnc_Temp_Module_Min_SubId : 42|3@1+ (1,0) [1|4] "Index"  NF_Controller
 SG_ BATT_Cnc_Temp_Module_Max_V : 21|2@1+ (1,0) [0|3] ""  NF_Controller
 SG_ BATT_Cnc_Temp_Module_Min_V : 45|2@1+ (1,0) [0|3] ""  NF_Controller
 SG_ BATT_Cnc_Temp_Module_Max_VtbId : 13|5@1+ (1,0) [0|29] "Index"  NF_Controller
 SG_ BATT_Cnc_Temp_Module_Min_StrId : 32|5@1+ (1,101) [101|124] "Index"  NF_Controller

BO_ 2499757668 BATT_Cnc_SOC: 8 BMS_Controller
 SG_ BATT_Cnc_SOC_String_MinV : 58|2@1+ (1,0) [0|3] ""  NF_Controller
 SG_ BATT_Cnc_SOC_String_MaxV : 56|2@1+ (1,0) [0|3] ""  NF_Controller
 SG_ BATT_Cnc_SOC_String_AvgV : 21|2@1+ (1,0) [0|3] ""  NF_Controller
 SG_ BATT_Cnc_Energy_SystemV : 37|2@1+ (1,0) [0|3] ""  NF_Controller
 SG_ BATT_Cnc_Energy_System : 40|16@1+ (0.01,0) [0|655.35] "KWh"  NF_Controller
 SG_ BATT_Cnc_SOC_String_Avg : 0|8@1+ (0.4,0) [0|100] "%"  NF_Controller
 SG_ BATT_Cnc_SOC_String_Max : 24|8@1+ (0.4,0) [0|100] "%"  NF_Controller
 SG_ BATT_Cnc_SOC_String_Max_StrId : 32|5@1+ (1,101) [101|124] "Index"  NF_Controller
 SG_ BATT_Cnc_SOC_String_Min : 8|8@1+ (0.4,0) [0|100] "%"  NF_Controller
 SG_ BATT_Cnc_SOC_String_Min_StrId : 16|5@1+ (1,101) [101|124] "Index"  NF_Controller

BO_ 2499800676 BATT_User_SOC: 8 BMS_Controller
 SG_ BATT_Cnc_User_SOC_String_Avg : 0|8@1+ (0.4,0) [0|100] "%"  NF_Controller
 SG_ BATT_Sys_User_SOC_String_Avg : 8|8@1+ (0.4,0) [0|100] "%"  NF_Controller

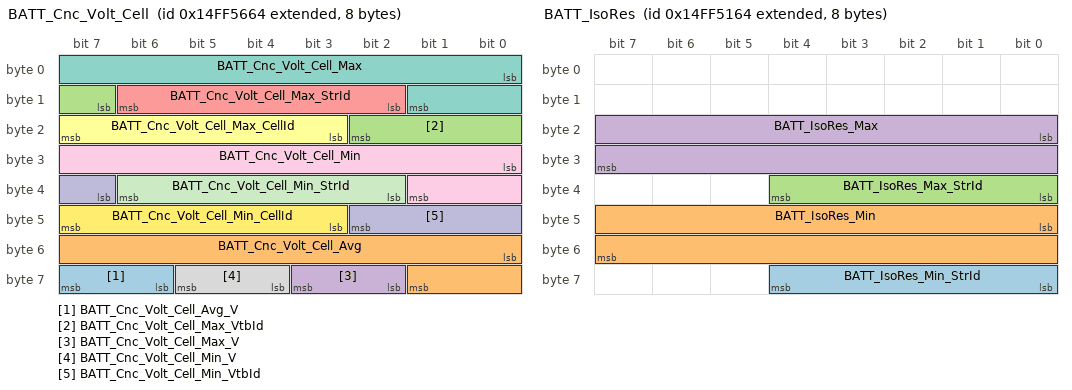
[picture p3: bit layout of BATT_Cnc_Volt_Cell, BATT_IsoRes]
BO_ 2499761764 BATT_Cnc_Volt_Cell: 8 BMS_Controller
 SG_ BATT_Cnc_Volt_Cell_Avg_V : 62|2@1+ (1,0) [0|3] ""  NF_Controller
 SG_ BATT_Cnc_Volt_Cell_Avg : 48|10@1+ (0.005,0) [0|5.115] "Volts"  NF_Controller
 SG_ BATT_Cnc_Volt_Cell_Max_VtbId : 15|4@1+ (1,1) [1|16] "Index"  NF_Controller
 SG_ BATT_Cnc_Volt_Cell_Max_V : 58|2@1+ (1,0) [0|3] ""  NF_Controller
 SG_ BATT_Cnc_Volt_Cell_Max_StrId : 10|5@1+ (1,101) [101|124] "Index"  NF_Controller
 SG_ BATT_Cnc_Volt_Cell_Max_CellId : 19|5@1+ (1,0) [0|31] "Index"  NF_Controller
 SG_ BATT_Cnc_Volt_Cell_Max : 0|10@1+ (0.005,0) [0|5.115] "Volts"  NF_Controller
 SG_ BATT_Cnc_Volt_Cell_Min_V : 60|2@1+ (1,0) [0|3] ""  NF_Controller
 SG_ BATT_Cnc_Volt_Cell_Min : 24|10@1+ (0.005,0) [0|5.115] "Volts"  NF_Controller
 SG_ BATT_Cnc_Volt_Cell_Min_VtbId : 39|4@1+ (1,1) [1|16] "Index"  NF_Controller
 SG_ BATT_Cnc_Volt_Cell_Min_StrId : 34|5@1+ (1,101) [101|124] "Index"  NF_Controller
 SG_ BATT_Cnc_Volt_Cell_Min_CellId : 43|5@1+ (1,0) [0|31] "Index"  NF_Controller

BO_ 2499760484 BATT_IsoRes: 8 BMS_Controller
 SG_ BATT_IsoRes_Min_StrId : 56|5@1+ (1,101) [101|124] "Index"  NF_Controller
 SG_ BATT_IsoRes_Min : 40|16@1+ (10,0) [0|655330] "kOhms"  NF_Controller
 SG_ BATT_IsoRes_Max_StrId : 32|5@1+ (1,101) [101|124] "Index"  NF_Controller
 SG_ BATT_IsoRes_Max : 16|16@1+ (10,0) [0|655330] "kOhms"  NF_Controller

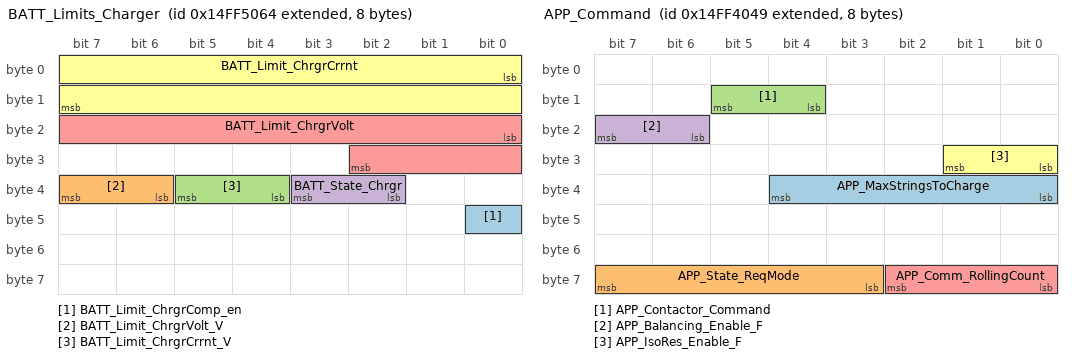
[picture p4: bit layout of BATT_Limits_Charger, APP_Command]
BO_ 2499760228 BATT_Limits_Charger: 8 BMS_Controller
 SG_ BATT_Limit_ChrgrComp_en : 40|1@1+ (1,0) [0|1] ""  NF_Controller
 SG_ BATT_Limit_ChrgrVolt_V : 38|2@1+ (1,0) [0|3] ""  NF_Controller
 SG_ BATT_Limit_ChrgrCrrnt_V : 36|2@1+ (1,0) [0|3] ""  NF_Controller
 SG_ BATT_State_Chrgr : 34|2@1+ (1,0) [0|3] ""  NF_Controller
 SG_ BATT_Limit_ChrgrVolt : 16|11@1+ (1,0) [0|2047] "Volts"  NF_Controller
 SG_ BATT_Limit_ChrgrCrrnt : 0|16@1+ (0.5,0) [0|16000] "Amps"  NF_Controller

BO_ 2499756105 APP_Command: 8 NF_Controller
 SG_ APP_MaxStringsToCharge : 32|5@1+ (1,0) [0|26] "Strings"  BMS_Controller
 SG_ APP_State_ReqMode : 59|5@1+ (1,0) [0|4] ""  BMS_Controller
 SG_ APP_Contactor_Command : 12|2@1+ (1,0) [0|3] ""  BMS_Controller
 SG_ APP_Balancing_Enable_F : 22|2@1+ (1,0) [0|3] ""  BMS_Controller
 SG_ APP_Comm_RollingCount : 56|3@1+ (1,0) [0|7] "Count"  BMS_Controller
 SG_ APP_IsoRes_Enable_F : 24|2@1+ (1,0) [0|3] ""  BMS_Controller

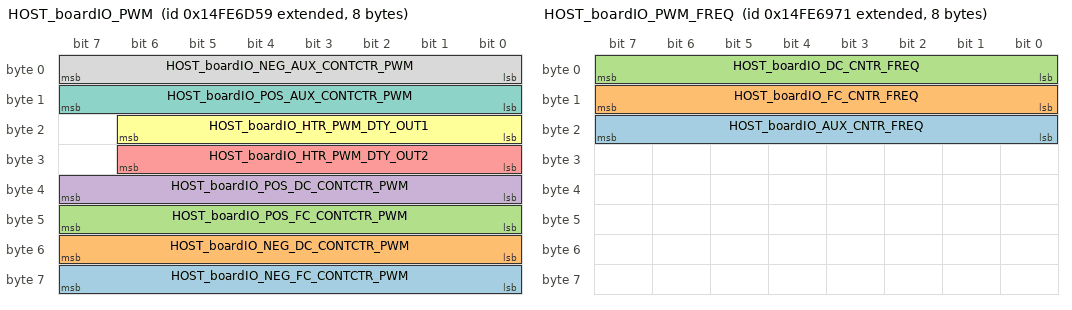
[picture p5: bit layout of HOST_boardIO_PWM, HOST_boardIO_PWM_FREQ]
BO_ 2499702105 HOST_boardIO_PWM: 8 NF_Controller
 SG_ HOST_boardIO_NEG_FC_CONTCTR_PWM : 56|8@1+ (1,0) [0|100] ""  BMS_Controller
 SG_ HOST_boardIO_NEG_DC_CONTCTR_PWM : 48|8@1+ (1,0) [0|100] ""  BMS_Controller
 SG_ HOST_boardIO_POS_FC_CONTCTR_PWM : 40|8@1+ (1,0) [0|100] ""  BMS_Controller
 SG_ HOST_boardIO_POS_DC_CONTCTR_PWM : 32|8@1+ (1,0) [0|100] ""  BMS_Controller
 SG_ HOST_boardIO_HTR_PWM_DTY_OUT2 : 24|7@1+ (1,0) [0|100] ""  BMS_Controller
 SG_ HOST_boardIO_HTR_PWM_DTY_OUT1 : 16|7@1+ (1,0) [0|100] ""  BMS_Controller
 SG_ HOST_boardIO_POS_AUX_CONTCTR_PWM : 8|8@1+ (1,0) [0|100] ""  BMS_Controller
 SG_ HOST_boardIO_NEG_AUX_CONTCTR_PWM : 0|8@1+ (1,0) [0|100] ""  BMS_Controller

BO_ 2499701105 HOST_boardIO_PWM_FREQ: 8 NF_Controller
 SG_ HOST_boardIO_AUX_CNTR_FREQ : 16|8@1+ (1,0) [0|100] ""  BMS_Controller
 SG_ HOST_boardIO_FC_CNTR_FREQ : 8|8@1+ (1,0) [0|100] ""  BMS_Controller
 SG_ HOST_boardIO_DC_CNTR_FREQ : 0|8@1+ (1,0) [0|100] ""  BMS_Controller

BO_ 2499700105 HOST_boardIO: 5 NF_Controller
 SG_ HOST_boardIO_ISOSPI_MSTR_OUT : 35|1@1+ (1,0) [0|1] ""  BMS_Controller
 SG_ HOST_boardIO_CAN_BAT_WAKE : 34|1@1+ (1,0) [0|1] ""  BMS_Controller
 SG_ HOST_boardIO_DC_LINK_BUS_DISCH : 33|1@1+ (1,0) [0|1] ""  BMS_Controller
 SG_ HOST_boardIO_NEG_AUX_CONTACTOR : 32|1@1+ (1,0) [0|1] ""  BMS_Controller
 SG_ HOST_boardIO_CAN_PT_WAKE : 31|1@1+ (1,0) [0|1] ""  BMS_Controller
 SG_ HOST_boardIO_POWER_ON : 30|1@1+ (1,0) [0|1] ""  BMS_Controller
 SG_ HOST_boardIO_nCAN_STB : 29|1@1+ (1,0) [0|1] ""  BMS_Controller
 SG_ HOST_boardIO_CAN_EN : 28|1@1+ (1,0) [0|1] ""  BMS_Controller
 SG_ HOST_boardIO_CS0_1 : 27|1@1+ (1,0) [0|1] ""  BMS_Controller
 SG_ HOST_boardIO_12_V_SHUNT_PWR_EN : 26|1@1+ (1,0) [0|1] ""  BMS_Controller
 SG_ HOST_boardIO_PYRO_CHECK_EN : 25|1@1+ (1,0) [0|1] ""  BMS_Controller
 SG_ HOST_boardIO_REBOOT_AFE : 24|1@1+ (1,0) [0|1] ""  BMS_Controller
 SG_ HOST_boardIO_BAL08 : 23|1@1+ (1,0) [0|0] ""  BMS_Controller
 SG_ HOST_boardIO_BAL07 : 22|1@1+ (1,0) [0|0] ""  BMS_Controller
 SG_ HOST_boardIO_BAL06 : 21|1@1+ (1,0) [0|0] ""  BMS_Controller
 SG_ HOST_boardIO_BAL05 : 20|1@1+ (1,0) [0|0] ""  BMS_Controller
 SG_ HOST_boardIO_BAL04 : 19|1@1+ (1,0) [0|0] ""  BMS_Controller
 SG_ HOST_boardIO_BAL03 : 18|1@1+ (1,0) [0|0] ""  BMS_Controller
 SG_ HOST_boardIO_BAL02 : 17|1@1+ (1,0) [0|0] ""  BMS_Controller
 SG_ HOST_boardIO_BAL01 : 16|1@1+ (1,0) [0|0] ""  BMS_Controller
 SG_ HOST_boardIO_POS_FC_CONTACTOR : 15|1@1+ (1,0) [0|1] ""  BMS_Controller
 SG_ HOST_boardIO_NEG_FC_CONTACTOR : 14|1@1+ (1,0) [0|1] ""  BMS_Controller
 SG_ HOST_boardIO_NEG_DC_CONTACTOR : 13|1@1+ (1,0) [0|1] ""  BMS_Controller
 SG_ HOST_boardIO_POS_DC_CONTACTOR : 12|1@1+ (1,0) [0|1] ""  BMS_Controller
 SG_ HOST_boardIO_PYRO_LSD_CTL : 11|1@1+ (1,0) [0|1] ""  BMS_Controller
 SG_ HOST_boardIO_PYRO_HSD_CTL : 10|1@1+ (1,0) [0|1] ""  BMS_Controller
 SG_ HOST_boardIO_nWP : 9|1@1+ (1,0) [0|1] ""  BMS_Controller
 SG_ HOST_boardIO_LATCH_RESET : 8|1@1+ (1,0) [0|1] ""  BMS_Controller
 SG_ HOST_boardIO_POS_AUX_CONTACTOR : 7|1@1+ (1,0) [0|1] ""  BMS_Controller
 SG_ HOST_boardIO_HW_PROTECT_DISABLED : 6|1@1+ (1,0) [0|1] ""  BMS_Controller
 SG_ HOST_boardIO_nFASTKILL : 5|1@1+ (1,0) [0|1] ""  BMS_Controller
 SG_ HOST_boardIO_DC_PRECHARGE_CTL : 4|1@1+ (1,0) [0|1] ""  BMS_Controller
 SG_ HOST_boardIO_PACK_NEG_ISO_CHECK : 3|1@1+ (1,0) [0|1] ""  BMS_Controller
 SG_ HOST_boardIO_PACK_POS_ISO_CHECK : 2|1@1+ (1,0) [0|1] ""  BMS_Controller
 SG_ HOST_boardIO_DC_CNTR_PWR_EN : 1|1@1+ (1,0) [0|1] ""  BMS_Controller
 SG_ HOST_boardIO_FC_CNTR_PWR_EN : 0|1@1+ (1,0) [0|1] ""  BMS_Controller

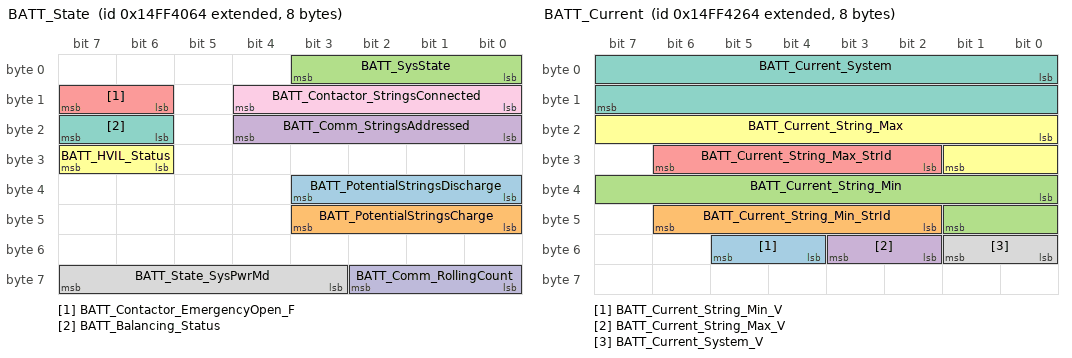
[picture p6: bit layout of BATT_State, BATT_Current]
BO_ 2499756132 BATT_State: 8 BMS_Controller
 SG_ BATT_PotentialStringsDischarge : 32|4@1+ (1,0) [0|15] "" Vector__XXX
 SG_ BATT_PotentialStringsCharge : 40|4@1+ (1,0) [0|15] "" Vector__XXX
 SG_ BATT_SysState : 0|4@1+ (1,0) [0|15] "" Vector__XXX
 SG_ BATT_Comm_StringsAddressed : 16|5@1+ (1,0) [0|24] "Count"  NF_Controller
 SG_ BATT_Contactor_EmergencyOpen_F : 14|2@1+ (1,0) [0|3] ""  NF_Controller
 SG_ BATT_HVIL_Status : 30|2@1+ (1,0) [0|3] ""  NF_Controller
 SG_ BATT_Balancing_Status : 22|2@1+ (1,0) [0|3] ""  NF_Controller
 SG_ BATT_State_SysPwrMd : 59|5@1+ (1,0) [0|5] ""  NF_Controller
 SG_ BATT_Contactor_StringsConnected : 8|5@1+ (1,0) [0|24] "Count"  NF_Controller
 SG_ BATT_Comm_RollingCount : 56|3@1+ (1,0) [0|7] "Count"  NF_Controller

BO_ 2499756644 BATT_Current: 8 BMS_Controller
 SG_ BATT_Current_String_Min_V : 52|2@1+ (1,0) [0|3] ""  NF_Controller
 SG_ BATT_Current_String_Min_StrId : 42|5@1+ (1,101) [101|124] "Index"  NF_Controller
 SG_ BATT_Current_String_Min : 32|10@1+ (1,-500) [-500|500] "Amps"  NF_Controller
 SG_ BATT_Current_String_Max_V : 50|2@1+ (1,0) [0|3] ""  NF_Controller
 SG_ BATT_Current_String_Max_StrId : 26|5@1+ (1,101) [101|124] "Index"  NF_Controller
 SG_ BATT_Current_String_Max : 16|10@1+ (1,-500) [-500|500] "Amps"  NF_Controller
 SG_ BATT_Current_System : 0|16@1+ (0.5,-16000) [-16000|16000] "Amps"  NF_Controller
 SG_ BATT_Current_System_V : 48|2@1+ (1,0) [0|3] ""  NF_Controller

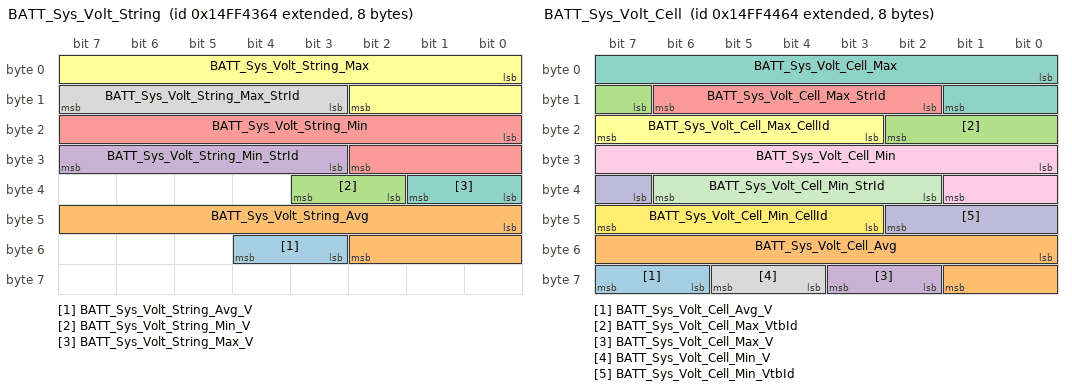
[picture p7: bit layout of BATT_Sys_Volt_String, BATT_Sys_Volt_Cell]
BO_ 2499756900 BATT_Sys_Volt_String: 8 BMS_Controller
 SG_ BATT_Sys_Volt_String_Avg_V : 51|2@1+ (1,0) [0|3] ""  NF_Controller
 SG_ BATT_Sys_Volt_String_Avg : 40|11@1+ (1,0) [0|1250] "Volts"  NF_Controller
 SG_ BATT_Sys_Volt_String_Min_V : 34|2@1+ (1,0) [0|3] ""  NF_Controller
 SG_ BATT_Sys_Volt_String_Min_StrId : 27|5@1+ (1,101) [101|124] "Index"  NF_Controller
 SG_ BATT_Sys_Volt_String_Min : 16|11@1+ (1,0) [0|1250] "Volts"  NF_Controller
 SG_ BATT_Sys_Volt_String_Max : 0|11@1+ (1,0) [0|1250] "Volts"  NF_Controller
 SG_ BATT_Sys_Volt_String_Max_V : 32|2@1+ (1,0) [0|3] ""  NF_Controller
 SG_ BATT_Sys_Volt_String_Max_StrId : 11|5@1+ (1,101) [101|124] "Index"  NF_Controller

BO_ 2499757156 BATT_Sys_Volt_Cell: 8 BMS_Controller
 SG_ BATT_Sys_Volt_Cell_Avg_V : 62|2@1+ (1,0) [0|3] ""  NF_Controller
 SG_ BATT_Sys_Volt_Cell_Avg : 48|10@1+ (0.005,0) [0|5.115] "Volts"  NF_Controller
 SG_ BATT_Sys_Volt_Cell_Max_VtbId : 15|4@1+ (1,0) [0|15] "Index"  NF_Controller
 SG_ BATT_Sys_Volt_Cell_Max_V : 58|2@1+ (1,0) [0|3] ""  NF_Controller
 SG_ BATT_Sys_Volt_Cell_Max_StrId : 10|5@1+ (1,101) [101|124] "Index"  NF_Controller
 SG_ BATT_Sys_Volt_Cell_Max_CellId : 19|5@1+ (1,0) [0|31] "Index"  NF_Controller
 SG_ BATT_Sys_Volt_Cell_Max : 0|10@1+ (0.005,0) [0|5.115] "Volts"  NF_Controller
 SG_ BATT_Sys_Volt_Cell_Min_V : 60|2@1+ (1,0) [0|3] ""  NF_Controller
 SG_ BATT_Sys_Volt_Cell_Min : 24|10@1+ (0.005,0) [0|5.115] "Volts"  NF_Controller
 SG_ BATT_Sys_Volt_Cell_Min_VtbId : 39|4@1+ (1,0) [0|31] "Index"  NF_Controller
 SG_ BATT_Sys_Volt_Cell_Min_StrId : 34|5@1+ (1,101) [101|124] "Index"  NF_Controller
 SG_ BATT_Sys_Volt_Cell_Min_CellId : 43|5@1+ (1,0) [0|31] "Index"  NF_Controller

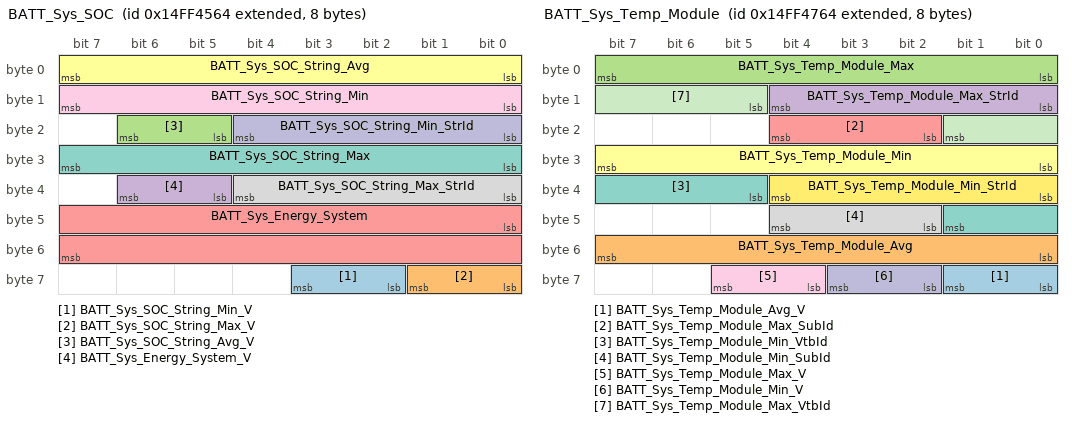
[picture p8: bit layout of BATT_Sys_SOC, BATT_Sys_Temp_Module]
BO_ 2499757412 BATT_Sys_SOC: 8 BMS_Controller
 SG_ BATT_Sys_SOC_String_Min_V : 58|2@1+ (1,0) [0|3] ""  NF_Controller
 SG_ BATT_Sys_SOC_String_Max_V : 56|2@1+ (1,0) [0|3] ""  NF_Controller
 SG_ BATT_Sys_SOC_String_Avg_V : 21|2@1+ (1,0) [0|3] ""  NF_Controller
 SG_ BATT_Sys_Energy_System_V : 37|2@1+ (1,0) [0|3] ""  NF_Controller
 SG_ BATT_Sys_Energy_System : 40|16@1+ (0.01,0) [0|655.35] "KWh"  NF_Controller
 SG_ BATT_Sys_SOC_String_Avg : 0|8@1+ (0.4,0) [0|100] "%"  NF_Controller
 SG_ BATT_Sys_SOC_String_Max : 24|8@1+ (0.4,0) [0|100] "%"  NF_Controller
 SG_ BATT_Sys_SOC_String_Max_StrId : 32|5@1+ (1,101) [101|124] "Index"  NF_Controller
 SG_ BATT_Sys_SOC_String_Min : 8|8@1+ (0.4,0) [0|100] "%"  NF_Controller
 SG_ BATT_Sys_SOC_String_Min_StrId : 16|5@1+ (1,101) [101|124] "Index"  NF_Controller

BO_ 2499757924 BATT_Sys_Temp_Module: 8 BMS_Controller
 SG_ BATT_Sys_Temp_Module_Avg_V : 56|2@1+ (1,0) [0|3] ""  NF_Controller
 SG_ BATT_Sys_Temp_Module_Avg : 48|8@1+ (1,-40) [-40|200] "Degree C"  NF_Controller
 SG_ BATT_Sys_Temp_Module_Max : 0|8@1+ (1,-40) [-40|200] "Degree C"  NF_Controller
 SG_ BATT_Sys_Temp_Module_Max_StrId : 8|5@1+ (1,101) [101|124] "Index"  NF_Controller
 SG_ BATT_Sys_Temp_Module_Max_SubId : 18|3@1+ (1,0) [1|4] "Index"  NF_Controller
 SG_ BATT_Sys_Temp_Module_Min : 24|8@1+ (1,-40) [-40|200] "Degree C"  NF_Controller
 SG_ BATT_Sys_Temp_Module_Min_VtbId : 37|5@1+ (1,0) [0|29] "Index"  NF_Controller
 SG_ BATT_Sys_Temp_Module_Min_SubId : 42|3@1+ (1,0) [1|4] "Index"  NF_Controller
 SG_ BATT_Sys_Temp_Module_Max_V : 60|2@1+ (1,0) [0|3] ""  NF_Controller
 SG_ BATT_Sys_Temp_Module_Min_V : 58|2@1+ (1,0) [0|3] ""  NF_Controller
 SG_ BATT_Sys_Temp_Module_Max_VtbId : 13|5@1+ (1,0) [0|29] "Index"  NF_Controller
 SG_ BATT_Sys_Temp_Module_Min_StrId : 32|5@1+ (1,101) [101|124] "Index"  NF_Controller

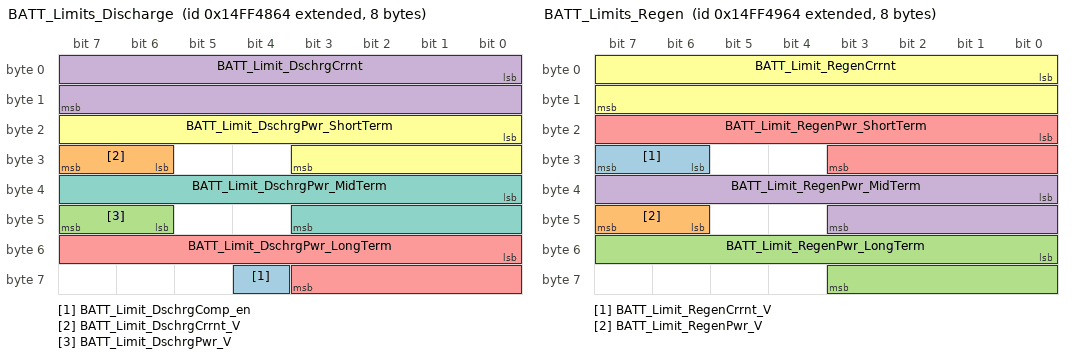
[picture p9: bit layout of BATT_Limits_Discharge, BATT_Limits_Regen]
BO_ 2499758180 BATT_Limits_Discharge: 8 BMS_Controller
 SG_ BATT_Limit_DschrgComp_en : 60|1@1+ (1,0) [0|1] ""  NF_Controller
 SG_ BATT_Limit_DschrgCrrnt_V : 30|2@1+ (1,0) [0|3] ""  NF_Controller
 SG_ BATT_Limit_DschrgPwr_V : 46|2@1+ (1,0) [0|3] ""  NF_Controller
 SG_ BATT_Limit_DschrgCrrnt : 0|16@1+ (0.5,0) [0|16000] "Amps"  NF_Controller
 SG_ BATT_Limit_DschrgPwr_LongTerm : 48|12@1+ (1,0) [0|4095] "KW"  NF_Controller
 SG_ BATT_Limit_DschrgPwr_ShortTerm : 16|12@1+ (1,0) [0|4095] "KW"  NF_Controller
 SG_ BATT_Limit_DschrgPwr_MidTerm : 32|12@1+ (1,0) [0|4095] "KW"  NF_Controller

BO_ 2499758436 BATT_Limits_Regen: 8 BMS_Controller
 SG_ BATT_Limit_RegenCrrnt_V : 30|2@1+ (1,0) [0|3] ""  NF_Controller
 SG_ BATT_Limit_RegenPwr_V : 46|2@1+ (1,0) [0|3] ""  NF_Controller
 SG_ BATT_Limit_RegenPwr_LongTerm : 48|12@1+ (1,0) [0|4095] "KW"  NF_Controller
 SG_ BATT_Limit_RegenPwr_MidTerm : 32|12@1+ (1,0) [0|4095] "KW"  NF_Controller
 SG_ BATT_Limit_RegenPwr_ShortTerm : 16|12@1+ (1,0) [0|4095] "KW"  NF_Controller
 SG_ BATT_Limit_RegenCrrnt : 0|16@1+ (0.5,0) [0|16000] "Amps"  NF_Controller

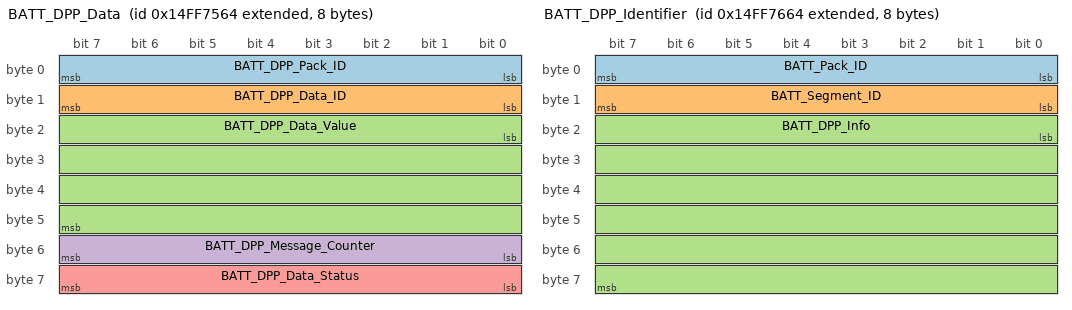
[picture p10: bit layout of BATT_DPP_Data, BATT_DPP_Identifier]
BO_ 2499769700 BATT_DPP_Data: 8 BMS_Controller
 SG_ BATT_DPP_Pack_ID : 0|8@1+ (1,0) [1|8] ""  NF_Controller
 SG_ BATT_DPP_Data_ID : 8|8@1+ (1,0) [1|20] ""  NF_Controller
 SG_ BATT_DPP_Data_Value : 16|32@1+ (1,0) [0|4294967295] "Depends on Data_ID"  NF_Controller
 SG_ BATT_DPP_Message_Counter : 48|8@1+ (1,0) [0|255] ""  NF_Controller
 SG_ BATT_DPP_Data_Status : 56|8@1+ (1,0) [0|1] ""  NF_Controller

BO_ 2499769956 BATT_DPP_Identifier: 8 BMS_Controller
 SG_ BATT_Pack_ID : 0|8@1+ (1,0) [1|8] ""  NF_Controller
 SG_ BATT_Segment_ID : 8|8@1+ (1,0) [0|255] ""  NF_Controller
 SG_ BATT_DPP_Info : 16|48@1+ (1,0) [0|281474976710655] ""  NF_Controller

CM_ BO_ 2499761508 "SOH  signals communicating string resistance information calculated from all strings.";
CM_ BO_ 2499760996 "SOH signals communicating string capacity related information calculated from all strings.";
CM_ BO_ 2499760740 "String Voltage signals communicating string information limted to strings that are connected to High Voltage (contactors closed).";
CM_ BO_ 2499756388 "Temperature signals communicating string information limted to strings that are connected to High Voltage (contactors closed).";
CM_ BO_ 2499757668 "SOC / Energy signals communicating string information limted to strings that are connected to High Voltage (contactors closed).";
CM_ BO_ 2499761764 "Voltage signals communicating string information limted to strings that are connected to High Voltage (contactors closed).";
CM_ BO_ 2499760484 "This message contains the results from the last Isolation Resistance Test.  The system always runs an Isolation Test after contactors open and may run an Isolation Test at start-up.  See integration guide for more information";
CM_ BO_ 2499760228 "Signals related to Charging Limits, are calculated by the Battery Management System.";
CM_ BO_ 2499756105 "This Message is the only message that is required for the XPAND System to operate. See individual signal comments and the Integration Guide.";
CM_ SG_ 2499756105 APP_MaxStringsToCharge "BMS should compare the value to the number of strings in the system, and the BMS will determine if the value passed by APP_Command:APP_MaxStringsToConnect";
CM_ SG_ 2499756105 APP_State_ReqMode "A signal from the Application that requests that the Battery Management System enter Charge/Discharge Mode.
This only works if Contactor_Command is Close & APP_Comm_RollingCount is incrementing.
See Value Descriptions";
CM_ SG_ 2499756105 APP_Contactor_Command "A signal from the Application that requests that the Battery Management System closes contactors.
This only works if App_StateReqMode is Charge/Discharge & APP_Comm_RollingCount is incrementing.
See Value Descriptions";
CM_ SG_ 2499756105 APP_Balancing_Enable_F "Signal from the Application that communicates to the Battery Management System that Cell Balance (if neccessary) is allowed.
See Value Descriptions tab for more information.";
CM_ SG_ 2499756105 APP_Comm_RollingCount "An incrementing signal from the Application that the Battery Management System used to calculate freshness.
The Application should increment (with rollover) this signal every time it's message is transmitted to the Battery Management System.

";
CM_ SG_ 2499756105 APP_IsoRes_Enable_F "CURRENTLY NOT SUPPORTED.  Signal from the Application that communicates to the Battery Management System that Runtime Isolation Detection is allowed.
See Value Descriptions tab for more information.";
CM_ BO_ 2499756132 "These signals communicate the state of the Battery Management System.  Look here for an overal understanding of the state of the BMS.";
CM_ SG_ 2499756132 BATT_Comm_StringsAddressed "This signal communicates the number of strings addressed at initialization";
CM_ SG_ 2499756132 BATT_Contactor_EmergencyOpen_F "This signal communicates if there was a Battery Management Fault that necessitated the contactors opening immediately.  If this happens, there will be a Fault flag set in BATT_Diagnostics
";
CM_ SG_ 2499756132 BATT_HVIL_Status "This signal communicates the high level status of the HVIL.   See the Value Description";
CM_ SG_ 2499756132 BATT_Balancing_Status "This signal communicates if a string in the BMS is currently balancing. See the Value Description";
CM_ SG_ 2499756132 BATT_State_SysPwrMd "This signal communicates the overal state of the System. When in Partial Run or Run, one or more strings are connected to High Voltage.";
CM_ SG_ 2499756132 BATT_Contactor_StringsConnected "This signal communicates the number of strings connected to High Voltage at any given time.";
CM_ SG_ 2499756132 BATT_Comm_RollingCount "An ever incrementing signal that the Application can chose to monitor to ensure the BMS is sending fresh information with each message.";
CM_ BO_ 2499756644 "Signals related to String Current as calculated by the Battery Management System.";
CM_ BO_ 2499756900 "String Voltage signals communicating string information calculated from all strings connected or not connected.";
CM_ BO_ 2499757156 "Cell Voltage signals communicating string information calculated from all strings connected or not connected.";
CM_ BO_ 2499757412 "SOC / Energy signals communicating string information calculated from all strings connected or not connected.";
CM_ BO_ 2499757924 "Temperature signals communicating string information calculated from all strings connected or not connected.";
CM_ BO_ 2499758180 "Signals related to Discharging Limits, are calculated by the Battery Management System.";
CM_ BO_ 2499758436 "Signals related to Regen Limits, are calculated by the Battery Management System.";
CM_ BO_ 2499769700 "EU battery passport; cyclic 1000 ms; CAN ID 0x14FF7564; 500 kbit/s.";
CM_ SG_ 2499769700 BATT_DPP_Pack_ID "One-based battery pack identifier (1 to 8).";
CM_ SG_ 2499769700 BATT_DPP_Data_ID "1=Battery life status;  2=Battery capacity;  3-7=SOC history;  8-10=power capability;  11=charge/discharge count; 12-17=temperature history;  18=deep-discharge event count;  19=overcharge event count;  20=post-event status.";
CM_ SG_ 2499769700 BATT_DPP_Data_Value "Raw value selected by Data_ID. See PASSPORT_DATA_ID_MAPPING for encoding and units.";
CM_ SG_ 2499769700 BATT_DPP_Message_Counter "Incremented for every transmitted frame; rolls over from 255 to 0.";
CM_ SG_ 2499769700 BATT_DPP_Data_Status "0=Valid; 1=Invalid / not available.";
CM_ BO_ 2499769956 "EU battery passport; cyclic 1000 ms; CAN ID 0x14FF7664; 500 kbit/s.";
CM_ SG_ 2499769956 BATT_Pack_ID "One-based battery pack identifier (1 to 8).";
CM_ SG_ 2499769956 BATT_Segment_ID "Cumulative byte count for a 64-byte DPP ID: 6, 12, ..., 60, 64. Ten chunks carry six bytes and the final chunk carries four bytes; restart from the first chunk for the next transfer.";
CM_ SG_ 2499769956 BATT_DPP_Info "Up to six DPP ID bytes in payload bytes 2-7. Identifier length is exactly 64 bytes. The final chunk contains four ID bytes followed by two zero padding bytes. No terminator is transmitted.";
BA_DEF_ BO_  "GenMsgDiag" ENUM  "No","Yes";
BA_DEF_ SG_  "SigType" ENUM  "Default","Range","RangeSigned","ASCII","Discrete","Control","ReferencePGN","DTC","StringDelimiter","StringLength","StringLengthControl","MessageCounter","MessageChecksum";
BA_DEF_ SG_  "GenSigEVName" STRING ;
BA_DEF_ SG_  "GenSigILSupport" ENUM  "No","Yes";
BA_DEF_ SG_  "GenSigSendType" ENUM  "Cyclic","OnWrite","OnWriteWithRepetition","OnChange","OnChangeWithRepetition","IfActive","IfActiveWithRepetition","NoSigSendType";
BA_DEF_ BO_  "GenMsgFastOnStart" INT 0 100000;
BA_DEF_ SG_  "GenSigStartValue" INT 0 10000;
BA_DEF_ BO_  "GenMsgILSupport" ENUM  "No","Yes";
BA_DEF_ BO_  "GenMsgSendType" ENUM  "cyclic","NotUsed","IfActive","NotUsed","NotUsed","NotUsed","NotUsed","NotUsed","noMsgSendType";
BA_DEF_ BO_  "GenMsgRequestable" INT 0 1;
BA_DEF_ BO_  "GenMsgCycleTime" INT 0 3600000;
BA_DEF_ SG_  "SPN" INT 0 524287;
BA_DEF_ BO_  "VFrameFormat" ENUM  "StandardCAN","ExtendedCAN","reserved","J1939PG";
BA_DEF_ SG_  "SystemSignalLongSymbol" STRING ;
BA_DEF_DEF_  "GenMsgDiag" "No";
BA_DEF_DEF_  "SigType" "Default";
BA_DEF_DEF_  "GenSigEVName" "Env@Nodename_@Signame";
BA_DEF_DEF_  "GenSigILSupport" "Yes";
BA_DEF_DEF_  "GenSigSendType" "NoSigSendType";
BA_DEF_DEF_  "GenMsgFastOnStart" 0;
BA_DEF_DEF_  "GenSigStartValue" 0;
BA_DEF_DEF_  "GenMsgILSupport" "Yes";
BA_DEF_DEF_  "GenMsgSendType" "noMsgSendType";
BA_DEF_DEF_  "GenMsgRequestable" 1;
BA_DEF_DEF_  "GenMsgCycleTime" 0;
BA_DEF_DEF_  "SPN" 0;
BA_DEF_DEF_  "VFrameFormat" "J1939PG";
BA_DEF_DEF_  "SystemSignalLongSymbol" "";
BA_ "GenMsgSendType" BO_ 2499762532 0;
BA_ "VFrameFormat" BO_ 2499762532 1;
BA_ "GenMsgSendType" BO_ 2499758948 0;
BA_ "GenMsgCycleTime" BO_ 2499758948 200;
BA_ "VFrameFormat" BO_ 2499758948 1;
BA_ "GenMsgDiag" BO_ 2499761508 1;
BA_ "GenMsgCycleTime" BO_ 2499761508 5000;
BA_ "GenMsgSendType" BO_ 2499761508 0;
BA_ "GenMsgCycleTime" BO_ 2499760996 5000;
BA_ "GenMsgSendType" BO_ 2499760996 0;
BA_ "GenMsgSendType" BO_ 2499760740 0;
BA_ "GenMsgCycleTime" BO_ 2499760740 100;
BA_ "GenMsgSendType" BO_ 2499756388 0;
BA_ "GenMsgCycleTime" BO_ 2499756388 1000;
BA_ "GenMsgSendType" BO_ 2499757668 0;
BA_ "GenMsgCycleTime" BO_ 2499757668 500;
BA_ "GenMsgSendType" BO_ 2499800676 0;
BA_ "GenMsgCycleTime" BO_ 2499761764 100;
BA_ "GenMsgSendType" BO_ 2499761764 0;
BA_ "GenMsgSendType" BO_ 2499760484 0;
BA_ "GenMsgCycleTime" BO_ 2499760484 1000;
BA_ "GenMsgSendType" BO_ 2499760228 0;
BA_ "GenMsgCycleTime" BO_ 2499760228 50;
BA_ "GenMsgSendType" BO_ 2499756105 0;
BA_ "GenMsgCycleTime" BO_ 2499756105 100;
BA_ "GenMsgSendType" BO_ 2499756132 0;
BA_ "GenMsgCycleTime" BO_ 2499756132 100;
BA_ "GenMsgSendType" BO_ 2499756644 0;
BA_ "GenMsgCycleTime" BO_ 2499756644 100;
BA_ "GenMsgSendType" BO_ 2499756900 0;
BA_ "GenMsgCycleTime" BO_ 2499756900 100;
BA_ "GenMsgSendType" BO_ 2499757156 0;
BA_ "GenMsgCycleTime" BO_ 2499757156 100;
BA_ "GenMsgSendType" BO_ 2499757412 0;
BA_ "GenMsgCycleTime" BO_ 2499757412 1000;
BA_ "GenMsgSendType" BO_ 2499757924 0;
BA_ "GenMsgCycleTime" BO_ 2499757924 1000;
BA_ "GenMsgSendType" BO_ 2499758180 0;
BA_ "GenMsgCycleTime" BO_ 2499758180 50;
BA_ "GenMsgSendType" BO_ 2499758436 0;
BA_ "GenMsgCycleTime" BO_ 2499758436 200;
BA_ "VFrameFormat" BO_ 2499769700 1;
BA_ "GenMsgSendType" BO_ 2499769700 0;
BA_ "VFrameFormat" BO_ 2499769956 1;
BA_ "GenMsgSendType" BO_ 2499769956 0;
BA_ "GenSigStartValue" SG_ 2499762532 BATT_01_vBrickOverSev 2;
BA_ "GenSigStartValue" SG_ 2499762532 BATT_01_vBrickOverMod 2;
BA_ "GenSigStartValue" SG_ 2499762532 BATT_01_vBrickOverWar 2;
BA_ "GenSigStartValue" SG_ 2499762532 BATT_01_HostQuiet 2;
BA_ "GenSigStartValue" SG_ 2499762532 BATT_01_vBrickUnderMod 2;
BA_ "GenSigStartValue" SG_ 2499762532 BATT_01_vBrickUnderWar 2;
BA_ "GenSigStartValue" SG_ 2499762532 BATT_01_TempModuleOverSev 2;
BA_ "GenSigStartValue" SG_ 2499762532 BATT_01_TempModuleOverMod 2;
BA_ "GenSigStartValue" SG_ 2499762532 BATT_01_TempModuleOverWar 2;
BA_ "GenSigStartValue" SG_ 2499762532 BATT_01_TempModuleUnderSev 2;
BA_ "GenSigStartValue" SG_ 2499762532 BATT_01_TempModuleUnderMod 2;
BA_ "GenSigStartValue" SG_ 2499762532 BATT_01_TempModuleUnderWar 2;
BA_ "GenSigStartValue" SG_ 2499762532 BATT_01_iOverchargesev 2;
BA_ "GenSigStartValue" SG_ 2499762532 BATT_01_iOverdischargesev 2;
BA_ "GenSigStartValue" SG_ 2499762532 BATT_01_iOverHardware 2;
BA_ "GenSigStartValue" SG_ 2499762532 BATT_01_PosDcContStuckOpen 2;
BA_ "GenSigStartValue" SG_ 2499762532 BATT_01_PosDcContWelded 2;
BA_ "GenSigStartValue" SG_ 2499762532 BATT_01_NegDcContStuckOpen 2;
BA_ "GenSigStartValue" SG_ 2499762532 BATT_01_NegDcContWelded 2;
BA_ "GenSigStartValue" SG_ 2499762532 BATT_01_PrechgTooFast 2;
BA_ "GenSigStartValue" SG_ 2499762532 BATT_01_PrechgContWelded 2;
BA_ "GenSigStartValue" SG_ 2499762532 BATT_01_PrechgTimeout 2;
BA_ "GenSigStartValue" SG_ 2499762532 BATT_01_PrechgContStuckOpen 2;
BA_ "GenSigStartValue" SG_ 2499762532 BATT_01_ModuleImbalance 2;
BA_ "GenSigStartValue" SG_ 2499762532 BATT_01_ModuleMIA 2;
BA_ "GenSigStartValue" SG_ 2499762532 BATT_01_SensePackVoltError 2;
BA_ "GenSigStartValue" SG_ 2499762532 BATT_01_SenseLoadVoltError 2;
BA_ "GenSigStartValue" SG_ 2499762532 BATT_01_SenseShuntError 2;
BA_ "GenSigStartValue" SG_ 2499762532 BATT_01_SenseFcVoltErrorr 2;
BA_ "GenSigStartValue" SG_ 2499762532 BATT_01_Placeholder14 2;
BA_ "GenSigStartValue" SG_ 2499762532 BATT_02_vBrickOverSev 2;
BA_ "GenSigStartValue" SG_ 2499762532 BATT_02_vBrickOverMod 2;
BA_ "GenSigStartValue" SG_ 2499762532 BATT_02_vBrickOverWar 2;
BA_ "GenSigStartValue" SG_ 2499762532 BATT_02_HostQuiet 2;
BA_ "GenSigStartValue" SG_ 2499762532 BATT_02_vBrickUnderMod 2;
BA_ "GenSigStartValue" SG_ 2499762532 BATT_02_vBrickUnderWar 2;
BA_ "GenSigStartValue" SG_ 2499762532 BATT_02_TempModuleOverSev 2;
BA_ "GenSigStartValue" SG_ 2499762532 BATT_02_TempModuleOverMod 2;
BA_ "GenSigStartValue" SG_ 2499762532 BATT_02_TempModuleOverWar 2;
BA_ "GenSigStartValue" SG_ 2499762532 BATT_02_TempModuleUnderSev 2;
BA_ "GenSigStartValue" SG_ 2499762532 BATT_02_TempModuleUnderMod 2;
BA_ "GenSigStartValue" SG_ 2499762532 BATT_02_TempModuleUnderWar 2;
BA_ "GenSigStartValue" SG_ 2499762532 BATT_02_iOverchargesev 2;
BA_ "GenSigStartValue" SG_ 2499762532 BATT_02_iOverdischargesev 2;
BA_ "GenSigStartValue" SG_ 2499762532 BATT_02_iOverHardware 2;
BA_ "GenSigStartValue" SG_ 2499762532 BATT_02_PosDcContStuckOpen 2;
BA_ "GenSigStartValue" SG_ 2499762532 BATT_02_PosDcContWelded 2;
BA_ "GenSigStartValue" SG_ 2499762532 BATT_02_NegDcContStuckOpen 2;
BA_ "GenSigStartValue" SG_ 2499762532 BATT_02_NegDcContWelded 2;
BA_ "GenSigStartValue" SG_ 2499762532 BATT_02_PrechgTooFast 2;
BA_ "GenSigStartValue" SG_ 2499762532 BATT_02_PrechgContWelded 2;
BA_ "GenSigStartValue" SG_ 2499762532 BATT_02_PrechgTimeout 2;
BA_ "GenSigStartValue" SG_ 2499762532 BATT_02_PrechgContStuckOpen 2;
BA_ "GenSigStartValue" SG_ 2499762532 BATT_02_ModuleImbalance 2;
BA_ "GenSigStartValue" SG_ 2499762532 BATT_02_ModuleMIA 2;
BA_ "GenSigStartValue" SG_ 2499762532 BATT_02_SensePackVoltError 2;
BA_ "GenSigStartValue" SG_ 2499762532 BATT_02_SenseLoadVoltError 2;
BA_ "GenSigStartValue" SG_ 2499762532 BATT_02_SenseShuntError 2;
BA_ "GenSigStartValue" SG_ 2499762532 BATT_02_SenseFcVoltErrorr 2;
BA_ "GenSigStartValue" SG_ 2499762532 BATT_02_Placeholder14 2;
BA_ "GenSigStartValue" SG_ 2499762532 BATT_03_vBrickOverSev 2;
BA_ "GenSigStartValue" SG_ 2499762532 BATT_03_vBrickOverMod 2;
BA_ "GenSigStartValue" SG_ 2499762532 BATT_03_vBrickOverWar 2;
BA_ "GenSigStartValue" SG_ 2499762532 BATT_03_HostQuiet 2;
BA_ "GenSigStartValue" SG_ 2499762532 BATT_03_vBrickUnderMod 2;
BA_ "GenSigStartValue" SG_ 2499762532 BATT_03_vBrickUnderWar 2;
BA_ "GenSigStartValue" SG_ 2499762532 BATT_03_TempModuleOverSev 2;
BA_ "GenSigStartValue" SG_ 2499762532 BATT_03_TempModuleOverMod 2;
BA_ "GenSigStartValue" SG_ 2499762532 BATT_03_TempModuleOverWar 2;
BA_ "GenSigStartValue" SG_ 2499762532 BATT_03_TempModuleUnderSev 2;
BA_ "GenSigStartValue" SG_ 2499762532 BATT_03_TempModuleUnderMod 2;
BA_ "GenSigStartValue" SG_ 2499762532 BATT_03_TempModuleUnderWar 2;
BA_ "GenSigStartValue" SG_ 2499762532 BATT_03_iOverchargesev 2;
BA_ "GenSigStartValue" SG_ 2499762532 BATT_03_iOverdischargesev 2;
BA_ "GenSigStartValue" SG_ 2499762532 BATT_03_iOverHardware 2;
BA_ "GenSigStartValue" SG_ 2499762532 BATT_03_PosDcContStuckOpen 2;
BA_ "GenSigStartValue" SG_ 2499762532 BATT_03_PosDcContWelded 2;
BA_ "GenSigStartValue" SG_ 2499762532 BATT_03_NegDcContStuckOpen 2;
BA_ "GenSigStartValue" SG_ 2499762532 BATT_03_NegDcContWelded 2;
BA_ "GenSigStartValue" SG_ 2499762532 BATT_03_PrechgTooFast 2;
BA_ "GenSigStartValue" SG_ 2499762532 BATT_03_PrechgContWelded 2;
BA_ "GenSigStartValue" SG_ 2499762532 BATT_03_PrechgTimeout 2;
BA_ "GenSigStartValue" SG_ 2499762532 BATT_03_PrechgContStuckOpen 2;
BA_ "GenSigStartValue" SG_ 2499762532 BATT_03_ModuleImbalance 2;
BA_ "GenSigStartValue" SG_ 2499762532 BATT_03_ModuleMIA 2;
BA_ "GenSigStartValue" SG_ 2499762532 BATT_03_SensePackVoltError 2;
BA_ "GenSigStartValue" SG_ 2499762532 BATT_03_SenseLoadVoltError 2;
BA_ "GenSigStartValue" SG_ 2499762532 BATT_03_SenseShuntError 2;
BA_ "GenSigStartValue" SG_ 2499762532 BATT_03_SenseFcVoltErrorr 2;
BA_ "GenSigStartValue" SG_ 2499762532 BATT_03_Placeholder14 2;
BA_ "GenSigStartValue" SG_ 2499762532 BATT_04_vBrickOverSev 2;
BA_ "GenSigStartValue" SG_ 2499762532 BATT_04_vBrickOverMod 2;
BA_ "GenSigStartValue" SG_ 2499762532 BATT_04_vBrickOverWar 2;
BA_ "GenSigStartValue" SG_ 2499762532 BATT_04_HostQuiet 2;
BA_ "GenSigStartValue" SG_ 2499762532 BATT_04_vBrickUnderMod 2;
BA_ "GenSigStartValue" SG_ 2499762532 BATT_04_vBrickUnderWar 2;
BA_ "GenSigStartValue" SG_ 2499762532 BATT_04_TempModuleOverSev 2;
BA_ "GenSigStartValue" SG_ 2499762532 BATT_04_TempModuleOverMod 2;
BA_ "GenSigStartValue" SG_ 2499762532 BATT_04_TempModuleOverWar 2;
BA_ "GenSigStartValue" SG_ 2499762532 BATT_04_TempModuleUnderSev 2;
BA_ "GenSigStartValue" SG_ 2499762532 BATT_04_TempModuleUnderMod 2;
BA_ "GenSigStartValue" SG_ 2499762532 BATT_04_TempModuleUnderWar 2;
BA_ "GenSigStartValue" SG_ 2499762532 BATT_04_iOverchargesev 2;
BA_ "GenSigStartValue" SG_ 2499762532 BATT_04_iOverdischargesev 2;
BA_ "GenSigStartValue" SG_ 2499762532 BATT_04_iOverHardware 2;
BA_ "GenSigStartValue" SG_ 2499762532 BATT_04_PosDcContStuckOpen 2;
BA_ "GenSigStartValue" SG_ 2499762532 BATT_04_PosDcContWelded 2;
BA_ "GenSigStartValue" SG_ 2499762532 BATT_04_NegDcContStuckOpen 2;
BA_ "GenSigStartValue" SG_ 2499762532 BATT_04_NegDcContWelded 2;
BA_ "GenSigStartValue" SG_ 2499762532 BATT_04_PrechgTooFast 2;
BA_ "GenSigStartValue" SG_ 2499762532 BATT_04_PrechgContWelded 2;
BA_ "GenSigStartValue" SG_ 2499762532 BATT_04_PrechgTimeout 2;
BA_ "GenSigStartValue" SG_ 2499762532 BATT_04_PrechgContStuckOpen 2;
BA_ "GenSigStartValue" SG_ 2499762532 BATT_04_ModuleImbalance 2;
BA_ "GenSigStartValue" SG_ 2499762532 BATT_04_ModuleMIA 2;
BA_ "GenSigStartValue" SG_ 2499762532 BATT_04_SensePackVoltError 2;
BA_ "GenSigStartValue" SG_ 2499762532 BATT_04_SenseLoadVoltError 2;
BA_ "GenSigStartValue" SG_ 2499762532 BATT_04_SenseShuntError 2;
BA_ "GenSigStartValue" SG_ 2499762532 BATT_04_SenseFcVoltErrorr 2;
BA_ "GenSigStartValue" SG_ 2499762532 BATT_04_Placeholder14 2;
BA_ "GenSigStartValue" SG_ 2499762532 BATT_05_vBrickOverSev 2;
BA_ "GenSigStartValue" SG_ 2499762532 BATT_05_vBrickOverMod 2;
BA_ "GenSigStartValue" SG_ 2499762532 BATT_05_vBrickOverWar 2;
BA_ "GenSigStartValue" SG_ 2499762532 BATT_05_HostQuiet 2;
BA_ "GenSigStartValue" SG_ 2499762532 BATT_05_vBrickUnderMod 2;
BA_ "GenSigStartValue" SG_ 2499762532 BATT_05_vBrickUnderWar 2;
BA_ "GenSigStartValue" SG_ 2499762532 BATT_05_TempModuleOverSev 2;
BA_ "GenSigStartValue" SG_ 2499762532 BATT_05_TempModuleOverMod 2;
BA_ "GenSigStartValue" SG_ 2499762532 BATT_05_TempModuleOverWar 2;
BA_ "GenSigStartValue" SG_ 2499762532 BATT_05_TempModuleUnderSev 2;
BA_ "GenSigStartValue" SG_ 2499762532 BATT_05_TempModuleUnderMod 2;
BA_ "GenSigStartValue" SG_ 2499762532 BATT_05_TempModuleUnderWar 2;
BA_ "GenSigStartValue" SG_ 2499762532 BATT_05_iOverchargesev 2;
BA_ "GenSigStartValue" SG_ 2499762532 BATT_05_iOverdischargesev 2;
BA_ "GenSigStartValue" SG_ 2499762532 BATT_05_iOverHardware 2;
BA_ "GenSigStartValue" SG_ 2499762532 BATT_05_PosDcContStuckOpen 2;
BA_ "GenSigStartValue" SG_ 2499762532 BATT_05_PosDcContWelded 2;
BA_ "GenSigStartValue" SG_ 2499762532 BATT_05_NegDcContStuckOpen 2;
BA_ "GenSigStartValue" SG_ 2499762532 BATT_05_NegDcContWelded 2;
BA_ "GenSigStartValue" SG_ 2499762532 BATT_05_PrechgTooFast 2;
BA_ "GenSigStartValue" SG_ 2499762532 BATT_05_PrechgContWelded 2;
BA_ "GenSigStartValue" SG_ 2499762532 BATT_05_PrechgTimeout 2;
BA_ "GenSigStartValue" SG_ 2499762532 BATT_05_PrechgContStuckOpen 2;
BA_ "GenSigStartValue" SG_ 2499762532 BATT_05_ModuleImbalance 2;
BA_ "GenSigStartValue" SG_ 2499762532 BATT_05_ModuleMIA 2;
BA_ "GenSigStartValue" SG_ 2499762532 BATT_05_SensePackVoltError 2;
BA_ "GenSigStartValue" SG_ 2499762532 BATT_05_SenseLoadVoltError 2;
BA_ "GenSigStartValue" SG_ 2499762532 BATT_05_SenseShuntError 2;
BA_ "GenSigStartValue" SG_ 2499762532 BATT_05_SenseFcVoltErrorr 2;
BA_ "GenSigStartValue" SG_ 2499762532 BATT_05_Placeholder14 2;
BA_ "GenSigStartValue" SG_ 2499762532 BATT_06_vBrickOverSev 2;
BA_ "GenSigStartValue" SG_ 2499762532 BATT_06_vBrickOverMod 2;
BA_ "GenSigStartValue" SG_ 2499762532 BATT_06_vBrickOverWar 2;
BA_ "GenSigStartValue" SG_ 2499762532 BATT_06_HostQuiet 2;
BA_ "GenSigStartValue" SG_ 2499762532 BATT_06_vBrickUnderMod 2;
BA_ "GenSigStartValue" SG_ 2499762532 BATT_06_vBrickUnderWar 2;
BA_ "GenSigStartValue" SG_ 2499762532 BATT_06_TempModuleOverSev 2;
BA_ "GenSigStartValue" SG_ 2499762532 BATT_06_TempModuleOverMod 2;
BA_ "GenSigStartValue" SG_ 2499762532 BATT_06_TempModuleOverWar 2;
BA_ "GenSigStartValue" SG_ 2499762532 BATT_06_TempModuleUnderSev 2;
BA_ "GenSigStartValue" SG_ 2499762532 BATT_06_TempModuleUnderMod 2;
BA_ "GenSigStartValue" SG_ 2499762532 BATT_06_TempModuleUnderWar 2;
BA_ "GenSigStartValue" SG_ 2499762532 BATT_06_iOverchargesev 2;
BA_ "GenSigStartValue" SG_ 2499762532 BATT_06_iOverdischargesev 2;
BA_ "GenSigStartValue" SG_ 2499762532 BATT_06_iOverHardware 2;
BA_ "GenSigStartValue" SG_ 2499762532 BATT_06_PosDcContStuckOpen 2;
BA_ "GenSigStartValue" SG_ 2499762532 BATT_06_PosDcContWelded 2;
BA_ "GenSigStartValue" SG_ 2499762532 BATT_06_NegDcContStuckOpen 2;
BA_ "GenSigStartValue" SG_ 2499762532 BATT_06_NegDcContWelded 2;
BA_ "GenSigStartValue" SG_ 2499762532 BATT_06_PrechgTooFast 2;
BA_ "GenSigStartValue" SG_ 2499762532 BATT_06_PrechgContWelded 2;
BA_ "GenSigStartValue" SG_ 2499762532 BATT_06_PrechgTimeout 2;
BA_ "GenSigStartValue" SG_ 2499762532 BATT_06_PrechgContStuckOpen 2;
BA_ "GenSigStartValue" SG_ 2499762532 BATT_06_ModuleImbalance 2;
BA_ "GenSigStartValue" SG_ 2499762532 BATT_06_ModuleMIA 2;
BA_ "GenSigStartValue" SG_ 2499762532 BATT_06_SensePackVoltError 2;
BA_ "GenSigStartValue" SG_ 2499762532 BATT_06_SenseLoadVoltError 2;
BA_ "GenSigStartValue" SG_ 2499762532 BATT_06_SenseShuntError 2;
BA_ "GenSigStartValue" SG_ 2499762532 BATT_06_SenseFcVoltErrorr 2;
BA_ "GenSigStartValue" SG_ 2499762532 BATT_06_Placeholder14 2;
BA_ "GenSigStartValue" SG_ 2499762532 BATT_07_vBrickOverSev 2;
BA_ "GenSigStartValue" SG_ 2499762532 BATT_07_vBrickOverMod 2;
BA_ "GenSigStartValue" SG_ 2499762532 BATT_07_vBrickOverWar 2;
BA_ "GenSigStartValue" SG_ 2499762532 BATT_07_HostQuiet 2;
BA_ "GenSigStartValue" SG_ 2499762532 BATT_07_vBrickUnderMod 2;
BA_ "GenSigStartValue" SG_ 2499762532 BATT_07_vBrickUnderWar 2;
BA_ "GenSigStartValue" SG_ 2499762532 BATT_07_TempModuleOverSev 2;
BA_ "GenSigStartValue" SG_ 2499762532 BATT_07_TempModuleOverMod 2;
BA_ "GenSigStartValue" SG_ 2499762532 BATT_07_TempModuleOverWar 2;
BA_ "GenSigStartValue" SG_ 2499762532 BATT_07_TempModuleUnderSev 2;
BA_ "GenSigStartValue" SG_ 2499762532 BATT_07_TempModuleUnderMod 2;
BA_ "GenSigStartValue" SG_ 2499762532 BATT_07_TempModuleUnderWar 2;
BA_ "GenSigStartValue" SG_ 2499762532 BATT_07_iOverchargesev 2;
BA_ "GenSigStartValue" SG_ 2499762532 BATT_07_iOverdischargesev 2;
BA_ "GenSigStartValue" SG_ 2499762532 BATT_07_iOverHardware 2;
BA_ "GenSigStartValue" SG_ 2499762532 BATT_07_PosDcContStuckOpen 2;
BA_ "GenSigStartValue" SG_ 2499762532 BATT_07_PosDcContWelded 2;
BA_ "GenSigStartValue" SG_ 2499762532 BATT_07_NegDcContStuckOpen 2;
BA_ "GenSigStartValue" SG_ 2499762532 BATT_07_NegDcContWelded 2;
BA_ "GenSigStartValue" SG_ 2499762532 BATT_07_PrechgTooFast 2;
BA_ "GenSigStartValue" SG_ 2499762532 BATT_07_PrechgContWelded 2;
BA_ "GenSigStartValue" SG_ 2499762532 BATT_07_PrechgTimeout 2;
BA_ "GenSigStartValue" SG_ 2499762532 BATT_07_PrechgContStuckOpen 2;
BA_ "GenSigStartValue" SG_ 2499762532 BATT_07_ModuleImbalance 2;
BA_ "GenSigStartValue" SG_ 2499762532 BATT_07_ModuleMIA 2;
BA_ "GenSigStartValue" SG_ 2499762532 BATT_07_SensePackVoltError 2;
BA_ "GenSigStartValue" SG_ 2499762532 BATT_07_SenseLoadVoltError 2;
BA_ "GenSigStartValue" SG_ 2499762532 BATT_07_SenseShuntError 2;
BA_ "GenSigStartValue" SG_ 2499762532 BATT_07_SenseFcVoltErrorr 2;
BA_ "GenSigStartValue" SG_ 2499762532 BATT_07_Placeholder14 2;
BA_ "GenSigStartValue" SG_ 2499762532 BATT_08_vBrickOverSev 2;
BA_ "GenSigStartValue" SG_ 2499762532 BATT_08_vBrickOverMod 2;
BA_ "GenSigStartValue" SG_ 2499762532 BATT_08_vBrickOverWar 2;
BA_ "GenSigStartValue" SG_ 2499762532 BATT_08_HostQuiet 2;
BA_ "GenSigStartValue" SG_ 2499762532 BATT_08_vBrickUnderMod 2;
BA_ "GenSigStartValue" SG_ 2499762532 BATT_08_vBrickUnderWar 2;
BA_ "GenSigStartValue" SG_ 2499762532 BATT_08_TempModuleOverSev 2;
BA_ "GenSigStartValue" SG_ 2499762532 BATT_08_TempModuleOverMod 2;
BA_ "GenSigStartValue" SG_ 2499762532 BATT_08_TempModuleOverWar 2;
BA_ "GenSigStartValue" SG_ 2499762532 BATT_08_TempModuleUnderSev 2;
BA_ "GenSigStartValue" SG_ 2499762532 BATT_08_TempModuleUnderMod 2;
BA_ "GenSigStartValue" SG_ 2499762532 BATT_08_TempModuleUnderWar 2;
BA_ "GenSigStartValue" SG_ 2499762532 BATT_08_iOverchargesev 2;
BA_ "GenSigStartValue" SG_ 2499762532 BATT_08_iOverdischargesev 2;
BA_ "GenSigStartValue" SG_ 2499762532 BATT_08_iOverHardware 2;
BA_ "GenSigStartValue" SG_ 2499762532 BATT_08_PosDcContStuckOpen 2;
BA_ "GenSigStartValue" SG_ 2499762532 BATT_08_PosDcContWelded 2;
BA_ "GenSigStartValue" SG_ 2499762532 BATT_08_NegDcContStuckOpen 2;
BA_ "GenSigStartValue" SG_ 2499762532 BATT_08_NegDcContWelded 2;
BA_ "GenSigStartValue" SG_ 2499762532 BATT_08_PrechgTooFast 2;
BA_ "GenSigStartValue" SG_ 2499762532 BATT_08_PrechgContWelded 2;
BA_ "GenSigStartValue" SG_ 2499762532 BATT_08_PrechgTimeout 2;
BA_ "GenSigStartValue" SG_ 2499762532 BATT_08_PrechgContStuckOpen 2;
BA_ "GenSigStartValue" SG_ 2499762532 BATT_08_ModuleImbalance 2;
BA_ "GenSigStartValue" SG_ 2499762532 BATT_08_ModuleMIA 2;
BA_ "GenSigStartValue" SG_ 2499762532 BATT_08_SensePackVoltError 2;
BA_ "GenSigStartValue" SG_ 2499762532 BATT_08_SenseLoadVoltError 2;
BA_ "GenSigStartValue" SG_ 2499762532 BATT_08_SenseShuntError 2;
BA_ "GenSigStartValue" SG_ 2499762532 BATT_08_SenseFcVoltErrorr 2;
BA_ "GenSigStartValue" SG_ 2499762532 BATT_08_Placeholder14 2;
BA_ "GenSigStartValue" SG_ 2499762532 BATT_09_vBrickOverSev 2;
BA_ "GenSigStartValue" SG_ 2499762532 BATT_09_vBrickOverMod 2;
BA_ "GenSigStartValue" SG_ 2499762532 BATT_09_vBrickOverWar 2;
BA_ "GenSigStartValue" SG_ 2499762532 BATT_09_HostQuiet 2;
BA_ "GenSigStartValue" SG_ 2499762532 BATT_09_vBrickUnderMod 2;
BA_ "GenSigStartValue" SG_ 2499762532 BATT_09_vBrickUnderWar 2;
BA_ "GenSigStartValue" SG_ 2499762532 BATT_09_TempModuleOverSev 2;
BA_ "GenSigStartValue" SG_ 2499762532 BATT_09_TempModuleOverMod 2;
BA_ "GenSigStartValue" SG_ 2499762532 BATT_09_TempModuleOverWar 2;
BA_ "GenSigStartValue" SG_ 2499762532 BATT_09_TempModuleUnderSev 2;
BA_ "GenSigStartValue" SG_ 2499762532 BATT_09_TempModuleUnderMod 2;
BA_ "GenSigStartValue" SG_ 2499762532 BATT_09_TempModuleUnderWar 2;
BA_ "GenSigStartValue" SG_ 2499762532 BATT_09_iOverchargesev 2;
BA_ "GenSigStartValue" SG_ 2499762532 BATT_09_iOverdischargesev 2;
BA_ "GenSigStartValue" SG_ 2499762532 BATT_09_iOverHardware 2;
BA_ "GenSigStartValue" SG_ 2499762532 BATT_09_PosDcContStuckOpen 2;
BA_ "GenSigStartValue" SG_ 2499762532 BATT_09_PosDcContWelded 2;
BA_ "GenSigStartValue" SG_ 2499762532 BATT_09_NegDcContStuckOpen 2;
BA_ "GenSigStartValue" SG_ 2499762532 BATT_09_NegDcContWelded 2;
BA_ "GenSigStartValue" SG_ 2499762532 BATT_09_PrechgTooFast 2;
BA_ "GenSigStartValue" SG_ 2499762532 BATT_09_PrechgContWelded 2;
BA_ "GenSigStartValue" SG_ 2499762532 BATT_09_PrechgTimeout 2;
BA_ "GenSigStartValue" SG_ 2499762532 BATT_09_PrechgContStuckOpen 2;
BA_ "GenSigStartValue" SG_ 2499762532 BATT_09_ModuleImbalance 2;
BA_ "GenSigStartValue" SG_ 2499762532 BATT_09_ModuleMIA 2;
BA_ "GenSigStartValue" SG_ 2499762532 BATT_09_SensePackVoltError 2;
BA_ "GenSigStartValue" SG_ 2499762532 BATT_09_SenseLoadVoltError 2;
BA_ "GenSigStartValue" SG_ 2499762532 BATT_09_SenseShuntError 2;
BA_ "GenSigStartValue" SG_ 2499762532 BATT_09_SenseFcVoltErrorr 2;
BA_ "GenSigStartValue" SG_ 2499762532 BATT_09_Placeholder14 2;
BA_ "GenSigStartValue" SG_ 2499762532 BATT_10_vBrickOverSev 2;
BA_ "GenSigStartValue" SG_ 2499762532 BATT_10_vBrickOverMod 2;
BA_ "GenSigStartValue" SG_ 2499762532 BATT_10_vBrickOverWar 2;
BA_ "GenSigStartValue" SG_ 2499762532 BATT_10_HostQuiet 2;
BA_ "GenSigStartValue" SG_ 2499762532 BATT_10_vBrickUnderMod 2;
BA_ "GenSigStartValue" SG_ 2499762532 BATT_10_vBrickUnderWar 2;
BA_ "GenSigStartValue" SG_ 2499762532 BATT_10_TempModuleOverSev 2;
BA_ "GenSigStartValue" SG_ 2499762532 BATT_10_TempModuleOverMod 2;
BA_ "GenSigStartValue" SG_ 2499762532 BATT_10_TempModuleOverWar 2;
BA_ "GenSigStartValue" SG_ 2499762532 BATT_10_TempModuleUnderSev 2;
BA_ "GenSigStartValue" SG_ 2499762532 BATT_10_TempModuleUnderMod 2;
BA_ "GenSigStartValue" SG_ 2499762532 BATT_10_TempModuleUnderWar 2;
BA_ "GenSigStartValue" SG_ 2499762532 BATT_10_iOverchargesev 2;
BA_ "GenSigStartValue" SG_ 2499762532 BATT_10_iOverdischargesev 2;
BA_ "GenSigStartValue" SG_ 2499762532 BATT_10_iOverHardware 2;
BA_ "GenSigStartValue" SG_ 2499762532 BATT_10_PosDcContStuckOpen 2;
BA_ "GenSigStartValue" SG_ 2499762532 BATT_10_PosDcContWelded 2;
BA_ "GenSigStartValue" SG_ 2499762532 BATT_10_NegDcContStuckOpen 2;
BA_ "GenSigStartValue" SG_ 2499762532 BATT_10_NegDcContWelded 2;
BA_ "GenSigStartValue" SG_ 2499762532 BATT_10_PrechgTooFast 2;
BA_ "GenSigStartValue" SG_ 2499762532 BATT_10_PrechgContWelded 2;
BA_ "GenSigStartValue" SG_ 2499762532 BATT_10_PrechgTimeout 2;
BA_ "GenSigStartValue" SG_ 2499762532 BATT_10_PrechgContStuckOpen 2;
BA_ "GenSigStartValue" SG_ 2499762532 BATT_10_ModuleImbalance 2;
BA_ "GenSigStartValue" SG_ 2499762532 BATT_10_ModuleMIA 2;
BA_ "GenSigStartValue" SG_ 2499762532 BATT_10_SensePackVoltError 2;
BA_ "GenSigStartValue" SG_ 2499762532 BATT_10_SenseLoadVoltError 2;
BA_ "GenSigStartValue" SG_ 2499762532 BATT_10_SenseShuntError 2;
BA_ "GenSigStartValue" SG_ 2499762532 BATT_10_SenseFcVoltErrorr 2;
BA_ "GenSigStartValue" SG_ 2499762532 BATT_10_Placeholder14 2;
BA_ "GenSigStartValue" SG_ 2499762532 BATT_11_vBrickOverSev 2;
BA_ "GenSigStartValue" SG_ 2499762532 BATT_11_vBrickOverMod 2;
BA_ "GenSigStartValue" SG_ 2499762532 BATT_11_vBrickOverWar 2;
BA_ "GenSigStartValue" SG_ 2499762532 BATT_11_HostQuiet 2;
BA_ "GenSigStartValue" SG_ 2499762532 BATT_11_vBrickUnderMod 2;
BA_ "GenSigStartValue" SG_ 2499762532 BATT_11_vBrickUnderWar 2;
BA_ "GenSigStartValue" SG_ 2499762532 BATT_11_TempModuleOverSev 2;
BA_ "GenSigStartValue" SG_ 2499762532 BATT_11_TempModuleOverMod 2;
BA_ "GenSigStartValue" SG_ 2499762532 BATT_11_TempModuleOverWar 2;
BA_ "GenSigStartValue" SG_ 2499762532 BATT_11_TempModuleUnderSev 2;
BA_ "GenSigStartValue" SG_ 2499762532 BATT_11_TempModuleUnderMod 2;
BA_ "GenSigStartValue" SG_ 2499762532 BATT_11_TempModuleUnderWar 2;
BA_ "GenSigStartValue" SG_ 2499762532 BATT_11_iOverchargesev 2;
BA_ "GenSigStartValue" SG_ 2499762532 BATT_11_iOverdischargesev 2;
BA_ "GenSigStartValue" SG_ 2499762532 BATT_11_iOverHardware 2;
BA_ "GenSigStartValue" SG_ 2499762532 BATT_11_PosDcContStuckOpen 2;
BA_ "GenSigStartValue" SG_ 2499762532 BATT_11_PosDcContWelded 2;
BA_ "GenSigStartValue" SG_ 2499762532 BATT_11_NegDcContStuckOpen 2;
BA_ "GenSigStartValue" SG_ 2499762532 BATT_11_NegDcContWelded 2;
BA_ "GenSigStartValue" SG_ 2499762532 BATT_11_PrechgTooFast 2;
BA_ "GenSigStartValue" SG_ 2499762532 BATT_11_PrechgContWelded 2;
BA_ "GenSigStartValue" SG_ 2499762532 BATT_11_PrechgTimeout 2;
BA_ "GenSigStartValue" SG_ 2499762532 BATT_11_PrechgContStuckOpen 2;
BA_ "GenSigStartValue" SG_ 2499762532 BATT_11_ModuleImbalance 2;
BA_ "GenSigStartValue" SG_ 2499762532 BATT_11_ModuleMIA 2;
BA_ "GenSigStartValue" SG_ 2499762532 BATT_11_SensePackVoltError 2;
BA_ "GenSigStartValue" SG_ 2499762532 BATT_11_SenseLoadVoltError 2;
BA_ "GenSigStartValue" SG_ 2499762532 BATT_11_SenseShuntError 2;
BA_ "GenSigStartValue" SG_ 2499762532 BATT_11_SenseFcVoltErrorr 2;
BA_ "GenSigStartValue" SG_ 2499762532 BATT_11_Placeholder14 2;
BA_ "GenSigStartValue" SG_ 2499762532 BATT_12_vBrickOverSev 2;
BA_ "GenSigStartValue" SG_ 2499762532 BATT_12_vBrickOverMod 2;
BA_ "GenSigStartValue" SG_ 2499762532 BATT_12_vBrickOverWar 2;
BA_ "GenSigStartValue" SG_ 2499762532 BATT_12_HostQuiet 2;
BA_ "GenSigStartValue" SG_ 2499762532 BATT_12_vBrickUnderMod 2;
BA_ "GenSigStartValue" SG_ 2499762532 BATT_12_vBrickUnderWar 2;
BA_ "GenSigStartValue" SG_ 2499762532 BATT_12_TempModuleOverSev 2;
BA_ "GenSigStartValue" SG_ 2499762532 BATT_12_TempModuleOverMod 2;
BA_ "GenSigStartValue" SG_ 2499762532 BATT_12_TempModuleOverWar 2;
BA_ "GenSigStartValue" SG_ 2499762532 BATT_12_TempModuleUnderSev 2;
BA_ "GenSigStartValue" SG_ 2499762532 BATT_12_TempModuleUnderMod 2;
BA_ "GenSigStartValue" SG_ 2499762532 BATT_12_TempModuleUnderWar 2;
BA_ "GenSigStartValue" SG_ 2499762532 BATT_12_iOverchargesev 2;
BA_ "GenSigStartValue" SG_ 2499762532 BATT_12_iOverdischargesev 2;
BA_ "GenSigStartValue" SG_ 2499762532 BATT_12_iOverHardware 2;
BA_ "GenSigStartValue" SG_ 2499762532 BATT_12_PosDcContStuckOpen 2;
BA_ "GenSigStartValue" SG_ 2499762532 BATT_12_PosDcContWelded 2;
BA_ "GenSigStartValue" SG_ 2499762532 BATT_12_NegDcContStuckOpen 2;
BA_ "GenSigStartValue" SG_ 2499762532 BATT_12_NegDcContWelded 2;
BA_ "GenSigStartValue" SG_ 2499762532 BATT_12_PrechgTooFast 2;
BA_ "GenSigStartValue" SG_ 2499762532 BATT_12_PrechgContWelded 2;
BA_ "GenSigStartValue" SG_ 2499762532 BATT_12_PrechgTimeout 2;
BA_ "GenSigStartValue" SG_ 2499762532 BATT_12_PrechgContStuckOpen 2;
BA_ "GenSigStartValue" SG_ 2499762532 BATT_12_ModuleImbalance 2;
BA_ "GenSigStartValue" SG_ 2499762532 BATT_12_ModuleMIA 2;
BA_ "GenSigStartValue" SG_ 2499762532 BATT_12_SensePackVoltError 2;
BA_ "GenSigStartValue" SG_ 2499762532 BATT_12_SenseLoadVoltError 2;
BA_ "GenSigStartValue" SG_ 2499762532 BATT_12_SenseShuntError 2;
BA_ "GenSigStartValue" SG_ 2499762532 BATT_12_SenseFcVoltErrorr 2;
BA_ "GenSigStartValue" SG_ 2499762532 BATT_12_Placeholder14 2;
BA_ "GenSigStartValue" SG_ 2499762532 BATT_13_vBrickOverSev 2;
BA_ "GenSigStartValue" SG_ 2499762532 BATT_13_vBrickOverMod 2;
BA_ "GenSigStartValue" SG_ 2499762532 BATT_13_vBrickOverWar 2;
BA_ "GenSigStartValue" SG_ 2499762532 BATT_13_HostQuiet 2;
BA_ "GenSigStartValue" SG_ 2499762532 BATT_13_vBrickUnderMod 2;
BA_ "GenSigStartValue" SG_ 2499762532 BATT_13_vBrickUnderWar 2;
BA_ "GenSigStartValue" SG_ 2499762532 BATT_13_TempModuleOverSev 2;
BA_ "GenSigStartValue" SG_ 2499762532 BATT_13_TempModuleOverMod 2;
BA_ "GenSigStartValue" SG_ 2499762532 BATT_13_TempModuleOverWar 2;
BA_ "GenSigStartValue" SG_ 2499762532 BATT_13_TempModuleUnderSev 2;
BA_ "GenSigStartValue" SG_ 2499762532 BATT_13_TempModuleUnderMod 2;
BA_ "GenSigStartValue" SG_ 2499762532 BATT_13_TempModuleUnderWar 2;
BA_ "GenSigStartValue" SG_ 2499762532 BATT_13_iOverchargesev 2;
BA_ "GenSigStartValue" SG_ 2499762532 BATT_13_iOverdischargesev 2;
BA_ "GenSigStartValue" SG_ 2499762532 BATT_13_iOverHardware 2;
BA_ "GenSigStartValue" SG_ 2499762532 BATT_13_PosDcContStuckOpen 2;
BA_ "GenSigStartValue" SG_ 2499762532 BATT_13_PosDcContWelded 2;
BA_ "GenSigStartValue" SG_ 2499762532 BATT_13_NegDcContStuckOpen 2;
BA_ "GenSigStartValue" SG_ 2499762532 BATT_13_NegDcContWelded 2;
BA_ "GenSigStartValue" SG_ 2499762532 BATT_13_PrechgTooFast 2;
BA_ "GenSigStartValue" SG_ 2499762532 BATT_13_PrechgContWelded 2;
BA_ "GenSigStartValue" SG_ 2499762532 BATT_13_PrechgTimeout 2;
BA_ "GenSigStartValue" SG_ 2499762532 BATT_13_PrechgContStuckOpen 2;
BA_ "GenSigStartValue" SG_ 2499762532 BATT_13_ModuleImbalance 2;
BA_ "GenSigStartValue" SG_ 2499762532 BATT_13_ModuleMIA 2;
BA_ "GenSigStartValue" SG_ 2499762532 BATT_13_SensePackVoltError 2;
BA_ "GenSigStartValue" SG_ 2499762532 BATT_13_SenseLoadVoltError 2;
BA_ "GenSigStartValue" SG_ 2499762532 BATT_13_SenseShuntError 2;
BA_ "GenSigStartValue" SG_ 2499762532 BATT_13_SenseFcVoltErrorr 2;
BA_ "GenSigStartValue" SG_ 2499762532 BATT_13_Placeholder14 2;
BA_ "GenSigStartValue" SG_ 2499762532 BATT_14_vBrickOverSev 2;
BA_ "GenSigStartValue" SG_ 2499762532 BATT_14_vBrickOverMod 2;
BA_ "GenSigStartValue" SG_ 2499762532 BATT_14_vBrickOverWar 2;
BA_ "GenSigStartValue" SG_ 2499762532 BATT_14_HostQuiet 2;
BA_ "GenSigStartValue" SG_ 2499762532 BATT_14_vBrickUnderMod 2;
BA_ "GenSigStartValue" SG_ 2499762532 BATT_14_vBrickUnderWar 2;
BA_ "GenSigStartValue" SG_ 2499762532 BATT_14_TempModuleOverSev 2;
BA_ "GenSigStartValue" SG_ 2499762532 BATT_14_TempModuleOverMod 2;
BA_ "GenSigStartValue" SG_ 2499762532 BATT_14_TempModuleOverWar 2;
BA_ "GenSigStartValue" SG_ 2499762532 BATT_14_TempModuleUnderSev 2;
BA_ "GenSigStartValue" SG_ 2499762532 BATT_14_TempModuleUnderMod 2;
BA_ "GenSigStartValue" SG_ 2499762532 BATT_14_TempModuleUnderWar 2;
BA_ "GenSigStartValue" SG_ 2499762532 BATT_14_iOverchargesev 2;
BA_ "GenSigStartValue" SG_ 2499762532 BATT_14_iOverdischargesev 2;
BA_ "GenSigStartValue" SG_ 2499762532 BATT_14_iOverHardware 2;
BA_ "GenSigStartValue" SG_ 2499762532 BATT_14_PosDcContStuckOpen 2;
BA_ "GenSigStartValue" SG_ 2499762532 BATT_14_PosDcContWelded 2;
BA_ "GenSigStartValue" SG_ 2499762532 BATT_14_NegDcContStuckOpen 2;
BA_ "GenSigStartValue" SG_ 2499762532 BATT_14_NegDcContWelded 2;
BA_ "GenSigStartValue" SG_ 2499762532 BATT_14_PrechgTooFast 2;
BA_ "GenSigStartValue" SG_ 2499762532 BATT_14_PrechgContWelded 2;
BA_ "GenSigStartValue" SG_ 2499762532 BATT_14_PrechgTimeout 2;
BA_ "GenSigStartValue" SG_ 2499762532 BATT_14_PrechgContStuckOpen 2;
BA_ "GenSigStartValue" SG_ 2499762532 BATT_14_ModuleImbalance 2;
BA_ "GenSigStartValue" SG_ 2499762532 BATT_14_ModuleMIA 2;
BA_ "GenSigStartValue" SG_ 2499762532 BATT_14_SensePackVoltError 2;
BA_ "GenSigStartValue" SG_ 2499762532 BATT_14_SenseLoadVoltError 2;
BA_ "GenSigStartValue" SG_ 2499762532 BATT_14_SenseShuntError 2;
BA_ "GenSigStartValue" SG_ 2499762532 BATT_14_SenseFcVoltErrorr 2;
BA_ "GenSigStartValue" SG_ 2499762532 BATT_14_Placeholder14 2;
BA_ "GenSigStartValue" SG_ 2499762532 BATT_15_vBrickOverSev 2;
BA_ "GenSigStartValue" SG_ 2499762532 BATT_15_vBrickOverMod 2;
BA_ "GenSigStartValue" SG_ 2499762532 BATT_15_vBrickOverWar 2;
BA_ "GenSigStartValue" SG_ 2499762532 BATT_15_HostQuiet 2;
BA_ "GenSigStartValue" SG_ 2499762532 BATT_15_vBrickUnderMod 2;
BA_ "GenSigStartValue" SG_ 2499762532 BATT_15_vBrickUnderWar 2;
BA_ "GenSigStartValue" SG_ 2499762532 BATT_15_TempModuleOverSev 2;
BA_ "GenSigStartValue" SG_ 2499762532 BATT_15_TempModuleOverMod 2;
BA_ "GenSigStartValue" SG_ 2499762532 BATT_15_TempModuleOverWar 2;
BA_ "GenSigStartValue" SG_ 2499762532 BATT_15_TempModuleUnderSev 2;
BA_ "GenSigStartValue" SG_ 2499762532 BATT_15_TempModuleUnderMod 2;
BA_ "GenSigStartValue" SG_ 2499762532 BATT_15_TempModuleUnderWar 2;
BA_ "GenSigStartValue" SG_ 2499762532 BATT_15_iOverchargesev 2;
BA_ "GenSigStartValue" SG_ 2499762532 BATT_15_iOverdischargesev 2;
BA_ "GenSigStartValue" SG_ 2499762532 BATT_15_iOverHardware 2;
BA_ "GenSigStartValue" SG_ 2499762532 BATT_15_PosDcContStuckOpen 2;
BA_ "GenSigStartValue" SG_ 2499762532 BATT_15_PosDcContWelded 2;
BA_ "GenSigStartValue" SG_ 2499762532 BATT_15_NegDcContStuckOpen 2;
BA_ "GenSigStartValue" SG_ 2499762532 BATT_15_NegDcContWelded 2;
BA_ "GenSigStartValue" SG_ 2499762532 BATT_15_PrechgTooFast 2;
BA_ "GenSigStartValue" SG_ 2499762532 BATT_15_PrechgContWelded 2;
BA_ "GenSigStartValue" SG_ 2499762532 BATT_15_PrechgTimeout 2;
BA_ "GenSigStartValue" SG_ 2499762532 BATT_15_PrechgContStuckOpen 2;
BA_ "GenSigStartValue" SG_ 2499762532 BATT_15_ModuleImbalance 2;
BA_ "GenSigStartValue" SG_ 2499762532 BATT_15_ModuleMIA 2;
BA_ "GenSigStartValue" SG_ 2499762532 BATT_15_SensePackVoltError 2;
BA_ "GenSigStartValue" SG_ 2499762532 BATT_15_SenseLoadVoltError 2;
BA_ "GenSigStartValue" SG_ 2499762532 BATT_15_SenseShuntError 2;
BA_ "GenSigStartValue" SG_ 2499762532 BATT_15_SenseFcVoltErrorr 2;
BA_ "GenSigStartValue" SG_ 2499762532 BATT_15_Placeholder14 2;
BA_ "GenSigStartValue" SG_ 2499758948 BATT_HVILFault 2;
BA_ "GenSigStartValue" SG_ 2499758948 BATT_PackVoltageImbalance 2;
BA_ "GenSigStartValue" SG_ 2499758948 BATT_PackMIA 2;
BA_ "GenSigStartValue" SG_ 2499758948 BATT_HostQuiet 2;
BA_ "GenSigStartValue" SG_ 2499758948 BATT_HostMIA 2;
BA_ "GenSigStartValue" SG_ 2499758948 BATT_SystemPrechargeFail 2;
BA_ "GenSigStartValue" SG_ 2499758948 BATT_VersionMismatch 2;
BA_ "SPN" SG_ 2499761508 BATT_Sys_SOHR_Module_Min_VtbId 2551;
BA_ "SPN" SG_ 2499761508 BATT_Sys_SOHR_Module_Min_V 2551;
BA_ "SPN" SG_ 2499761508 BATT_Sys_SOHR_Module_Min_StrId 2551;
BA_ "SPN" SG_ 2499761508 BATT_Sys_SOHR_Module_Min 2551;
BA_ "SPN" SG_ 2499761508 BATT_Sys_SOHR_Module_Max_VtbId 2551;
BA_ "SPN" SG_ 2499761508 BATT_Sys_SOHR_Module_Max_V 2551;
BA_ "SPN" SG_ 2499761508 BATT_Sys_SOHR_Module_Max_StrId 2551;
BA_ "SPN" SG_ 2499761508 BATT_Sys_SOHR_Module_Max 2551;
BA_ "SPN" SG_ 2499761508 BATT_Sys_SOHR_Module_Avg_V 2551;
BA_ "SPN" SG_ 2499761508 BATT_Sys_SOHR_Module_Avg 2551;
BA_ "SPN" SG_ 2499760996 BATT_Sys_SOHC_Module_Min_VtbId 2551;
BA_ "SPN" SG_ 2499760996 BATT_Sys_SOHC_Module_Min_V 2551;
BA_ "SPN" SG_ 2499760996 BATT_Sys_SOHC_Module_Min_StrId 2551;
BA_ "SPN" SG_ 2499760996 BATT_Sys_SOHC_Module_Min 2551;
BA_ "SPN" SG_ 2499760996 BATT_Sys_SOHC_Module_Max_VtbId 2551;
BA_ "SPN" SG_ 2499760996 BATT_Sys_SOHC_Module_Max_V 2551;
BA_ "SPN" SG_ 2499760996 BATT_Sys_SOHC_Module_Max_StrId 2551;
BA_ "SPN" SG_ 2499760996 BATT_Sys_SOHC_Module_Max 2551;
BA_ "SPN" SG_ 2499760996 BATT_Sys_SOHC_Module_Avg_V 2551;
BA_ "SPN" SG_ 2499760996 BATT_Sys_SOHC_Module_Avg 2551;
BA_ "SPN" SG_ 2499760740 BATT_Cnc_Volt_String_Avg_V 2551;
BA_ "SPN" SG_ 2499760740 BATT_Cnc_Volt_String_Avg 2551;
BA_ "SPN" SG_ 2499760740 BATT_Cnc_Volt_String_Min_V 2551;
BA_ "SPN" SG_ 2499760740 BATT_Cnc_Volt_String_Min_StrId 2551;
BA_ "SPN" SG_ 2499760740 BATT_Cnc_Volt_String_Min 2551;
BA_ "SPN" SG_ 2499760740 BATT_Cnc_Volt_String_Max 2551;
BA_ "SPN" SG_ 2499760740 BATT_Cnc_Volt_String_Max_V 2551;
BA_ "SPN" SG_ 2499760740 BATT_Cnc_Volt_String_Max_StrId 2551;
BA_ "SPN" SG_ 2499756388 BATT_Cnc_Temp_Module_Avg_V 2551;
BA_ "SPN" SG_ 2499756388 BATT_Cnc_Temp_Module_Avg 2551;
BA_ "SPN" SG_ 2499756388 BATT_Cnc_Temp_Module_Max 2551;
BA_ "SPN" SG_ 2499756388 BATT_Cnc_Temp_Module_Max_StrId 2551;
BA_ "SPN" SG_ 2499756388 BATT_Cnc_Temp_Module_Max_SubId 2551;
BA_ "GenSigStartValue" SG_ 2499756388 BATT_Cnc_Temp_Module_Max_SubId 1;
BA_ "SPN" SG_ 2499756388 BATT_Cnc_Temp_Module_Min 2551;
BA_ "SPN" SG_ 2499756388 BATT_Cnc_Temp_Module_Min_VtbId 2551;
BA_ "SPN" SG_ 2499756388 BATT_Cnc_Temp_Module_Min_SubId 2551;
BA_ "GenSigStartValue" SG_ 2499756388 BATT_Cnc_Temp_Module_Min_SubId 1;
BA_ "SPN" SG_ 2499756388 BATT_Cnc_Temp_Module_Max_V 2551;
BA_ "SPN" SG_ 2499756388 BATT_Cnc_Temp_Module_Min_V 2551;
BA_ "SPN" SG_ 2499756388 BATT_Cnc_Temp_Module_Max_VtbId 2551;
BA_ "SPN" SG_ 2499756388 BATT_Cnc_Temp_Module_Min_StrId 2551;
BA_ "SPN" SG_ 2499757668 BATT_Cnc_SOC_String_MinV 2551;
BA_ "SPN" SG_ 2499757668 BATT_Cnc_SOC_String_MaxV 2551;
BA_ "SPN" SG_ 2499757668 BATT_Cnc_SOC_String_AvgV 2551;
BA_ "SPN" SG_ 2499757668 BATT_Cnc_Energy_SystemV 2551;
BA_ "SPN" SG_ 2499757668 BATT_Cnc_Energy_System 2551;
BA_ "SPN" SG_ 2499757668 BATT_Cnc_SOC_String_Avg 2551;
BA_ "SPN" SG_ 2499757668 BATT_Cnc_SOC_String_Max 2551;
BA_ "SPN" SG_ 2499757668 BATT_Cnc_SOC_String_Max_StrId 2551;
BA_ "SPN" SG_ 2499757668 BATT_Cnc_SOC_String_Min 2551;
BA_ "SPN" SG_ 2499757668 BATT_Cnc_SOC_String_Min_StrId 2551;
BA_ "SPN" SG_ 2499800676 BATT_Cnc_User_SOC_String_Avg 2551;
BA_ "SPN" SG_ 2499800676 BATT_Sys_User_SOC_String_Avg 2551;
BA_ "SPN" SG_ 2499761764 BATT_Cnc_Volt_Cell_Avg_V 2551;
BA_ "SPN" SG_ 2499761764 BATT_Cnc_Volt_Cell_Avg 2551;
BA_ "SPN" SG_ 2499761764 BATT_Cnc_Volt_Cell_Max_VtbId 2551;
BA_ "SPN" SG_ 2499761764 BATT_Cnc_Volt_Cell_Max_V 2551;
BA_ "SPN" SG_ 2499761764 BATT_Cnc_Volt_Cell_Max_StrId 2551;
BA_ "SPN" SG_ 2499761764 BATT_Cnc_Volt_Cell_Max_CellId 2551;
BA_ "SPN" SG_ 2499761764 BATT_Cnc_Volt_Cell_Max 2551;
BA_ "SPN" SG_ 2499761764 BATT_Cnc_Volt_Cell_Min_V 2551;
BA_ "SPN" SG_ 2499761764 BATT_Cnc_Volt_Cell_Min 2551;
BA_ "SPN" SG_ 2499761764 BATT_Cnc_Volt_Cell_Min_VtbId 2551;
BA_ "SPN" SG_ 2499761764 BATT_Cnc_Volt_Cell_Min_StrId 2551;
BA_ "SPN" SG_ 2499761764 BATT_Cnc_Volt_Cell_Min_CellId 2551;
BA_ "SPN" SG_ 2499760484 BATT_IsoRes_Min_StrId 2551;
BA_ "SPN" SG_ 2499760484 BATT_IsoRes_Min 2551;
BA_ "SPN" SG_ 2499760484 BATT_IsoRes_Max_StrId 2551;
BA_ "SPN" SG_ 2499760484 BATT_IsoRes_Max 2551;
BA_ "SPN" SG_ 2499760228 BATT_State_Chrgr 2551;
BA_ "SPN" SG_ 2499760228 BATT_Limit_ChrgrVolt 2551;
BA_ "SPN" SG_ 2499760228 BATT_Limit_ChrgrCrrnt 2551;
BA_ "SPN" SG_ 2499756105 APP_MaxStringsToCharge 2551;
BA_ "SPN" SG_ 2499756105 APP_State_ReqMode 2551;
BA_ "SPN" SG_ 2499756105 APP_Contactor_Command 2551;
BA_ "SPN" SG_ 2499756105 APP_Balancing_Enable_F 2551;
BA_ "SPN" SG_ 2499756105 APP_Comm_RollingCount 2551;
BA_ "SPN" SG_ 2499756105 APP_IsoRes_Enable_F 2551;
BA_ "SPN" SG_ 2499756132 BATT_Comm_StringsAddressed 2551;
BA_ "SPN" SG_ 2499756132 BATT_Contactor_EmergencyOpen_F 2551;
BA_ "SPN" SG_ 2499756132 BATT_Balancing_Status 2551;
BA_ "SPN" SG_ 2499756132 BATT_State_SysPwrMd 2551;
BA_ "SPN" SG_ 2499756132 BATT_Contactor_StringsConnected 2551;
BA_ "SPN" SG_ 2499756132 BATT_Comm_RollingCount 2551;
BA_ "SPN" SG_ 2499756644 BATT_Current_String_Min_V 2551;
BA_ "SPN" SG_ 2499756644 BATT_Current_String_Min_StrId 2551;
BA_ "SPN" SG_ 2499756644 BATT_Current_String_Min 2551;
BA_ "SPN" SG_ 2499756644 BATT_Current_String_Max_V 2551;
BA_ "SPN" SG_ 2499756644 BATT_Current_String_Max_StrId 2551;
BA_ "SPN" SG_ 2499756644 BATT_Current_String_Max 2551;
BA_ "SPN" SG_ 2499756644 BATT_Current_System 2551;
BA_ "SPN" SG_ 2499756644 BATT_Current_System_V 2551;
BA_ "SPN" SG_ 2499756900 BATT_Sys_Volt_String_Avg 2551;
BA_ "SPN" SG_ 2499756900 BATT_Sys_Volt_String_Min_StrId 2551;
BA_ "SPN" SG_ 2499756900 BATT_Sys_Volt_String_Min 2551;
BA_ "SPN" SG_ 2499756900 BATT_Sys_Volt_String_Max 2551;
BA_ "SPN" SG_ 2499756900 BATT_Sys_Volt_String_Max_StrId 2551;
BA_ "SPN" SG_ 2499757156 BATT_Sys_Volt_Cell_Avg 2551;
BA_ "SPN" SG_ 2499757156 BATT_Sys_Volt_Cell_Max_VtbId 2551;
BA_ "SPN" SG_ 2499757156 BATT_Sys_Volt_Cell_Max_V 2551;
BA_ "SPN" SG_ 2499757156 BATT_Sys_Volt_Cell_Max_StrId 2551;
BA_ "SPN" SG_ 2499757156 BATT_Sys_Volt_Cell_Max_CellId 2551;
BA_ "SPN" SG_ 2499757156 BATT_Sys_Volt_Cell_Max 2551;
BA_ "SPN" SG_ 2499757156 BATT_Sys_Volt_Cell_Min_V 2551;
BA_ "SPN" SG_ 2499757156 BATT_Sys_Volt_Cell_Min 2551;
BA_ "SPN" SG_ 2499757156 BATT_Sys_Volt_Cell_Min_VtbId 2551;
BA_ "SPN" SG_ 2499757156 BATT_Sys_Volt_Cell_Min_StrId 2551;
BA_ "SPN" SG_ 2499757156 BATT_Sys_Volt_Cell_Min_CellId 2551;
BA_ "SPN" SG_ 2499757412 BATT_Sys_SOC_String_Min_V 2551;
BA_ "SPN" SG_ 2499757412 BATT_Sys_SOC_String_Max_V 2551;
BA_ "SPN" SG_ 2499757412 BATT_Sys_SOC_String_Avg_V 2551;
BA_ "SPN" SG_ 2499757412 BATT_Sys_Energy_System_V 2551;
BA_ "SPN" SG_ 2499757412 BATT_Sys_Energy_System 2551;
BA_ "SPN" SG_ 2499757412 BATT_Sys_SOC_String_Avg 2551;
BA_ "SPN" SG_ 2499757412 BATT_Sys_SOC_String_Max 2551;
BA_ "SPN" SG_ 2499757412 BATT_Sys_SOC_String_Max_StrId 2551;
BA_ "SPN" SG_ 2499757412 BATT_Sys_SOC_String_Min 2551;
BA_ "SPN" SG_ 2499757412 BATT_Sys_SOC_String_Min_StrId 2551;
BA_ "SPN" SG_ 2499757924 BATT_Sys_Temp_Module_Avg 2551;
BA_ "SPN" SG_ 2499757924 BATT_Sys_Temp_Module_Max 2551;
BA_ "SPN" SG_ 2499757924 BATT_Sys_Temp_Module_Max_StrId 2551;
BA_ "SPN" SG_ 2499757924 BATT_Sys_Temp_Module_Max_SubId 2551;
BA_ "GenSigStartValue" SG_ 2499757924 BATT_Sys_Temp_Module_Max_SubId 1;
BA_ "SPN" SG_ 2499757924 BATT_Sys_Temp_Module_Min 2551;
BA_ "SPN" SG_ 2499757924 BATT_Sys_Temp_Module_Min_VtbId 2551;
BA_ "SPN" SG_ 2499757924 BATT_Sys_Temp_Module_Min_SubId 2551;
BA_ "GenSigStartValue" SG_ 2499757924 BATT_Sys_Temp_Module_Min_SubId 1;
BA_ "SPN" SG_ 2499757924 BATT_Sys_Temp_Module_Max_VtbId 2551;
BA_ "SPN" SG_ 2499757924 BATT_Sys_Temp_Module_Min_StrId 2551;
BA_ "SPN" SG_ 2499758180 BATT_Limit_DschrgCrrnt 2551;
BA_ "SPN" SG_ 2499758180 BATT_Limit_DschrgPwr_LongTerm 2551;
BA_ "SPN" SG_ 2499758180 BATT_Limit_DschrgPwr_ShortTerm 2551;
BA_ "SPN" SG_ 2499758180 BATT_Limit_DschrgPwr_MidTerm 2551;
BA_ "SPN" SG_ 2499758436 BATT_Limit_RegenPwr_LongTerm 2551;
BA_ "SPN" SG_ 2499758436 BATT_Limit_RegenPwr_MidTerm 2551;
BA_ "SPN" SG_ 2499758436 BATT_Limit_RegenPwr_ShortTerm 2551;
BA_ "SPN" SG_ 2499758436 BATT_Limit_RegenCrrnt 2551;
BA_ "GenSigStartValue" SG_ 2499769700 BATT_DPP_Pack_ID 1;
BA_ "GenSigStartValue" SG_ 2499769700 BATT_DPP_Data_ID 1;
BA_ "GenSigStartValue" SG_ 2499769956 BATT_Pack_ID 1;
BA_ "SigType" SG_ 2499769956 BATT_DPP_Info 3;
VAL_ 2499762532 BATT_01_vBrickOverSev 3 "Error" 2 "SNA" 1 "Active" 0 "Inactive" ;
VAL_ 2499762532 BATT_01_vBrickOverMod 3 "Error" 2 "SNA" 1 "Active" 0 "Inactive" ;
VAL_ 2499762532 BATT_01_vBrickOverWar 3 "Error" 2 "SNA" 1 "Active" 0 "Inactive" ;
VAL_ 2499762532 BATT_01_HostQuiet 3 "Error" 2 "SNA" 1 "Active" 0 "Inactive" ;
VAL_ 2499762532 BATT_01_vBrickUnderMod 3 "Error" 2 "SNA" 1 "Active" 0 "Inactive" ;
VAL_ 2499762532 BATT_01_vBrickUnderWar 3 "Error" 2 "SNA" 1 "Active" 0 "Inactive" ;
VAL_ 2499762532 BATT_01_TempModuleOverSev 3 "Error" 2 "SNA" 1 "Active" 0 "Inactive" ;
VAL_ 2499762532 BATT_01_TempModuleOverMod 3 "Error" 2 "SNA" 1 "Active" 0 "Inactive" ;
VAL_ 2499762532 BATT_01_TempModuleOverWar 3 "Error" 2 "SNA" 1 "Active" 0 "Inactive" ;
VAL_ 2499762532 BATT_01_TempModuleUnderSev 3 "Error" 2 "SNA" 1 "Active" 0 "Inactive" ;
VAL_ 2499762532 BATT_01_TempModuleUnderMod 3 "Error" 2 "SNA" 1 "Active" 0 "Inactive" ;
VAL_ 2499762532 BATT_01_TempModuleUnderWar 3 "Error" 2 "SNA" 1 "Active" 0 "Inactive" ;
VAL_ 2499762532 BATT_01_iOverchargesev 3 "Error" 2 "SNA" 1 "Active" 0 "Inactive" ;
VAL_ 2499762532 BATT_01_iOverdischargesev 3 "Error" 2 "SNA" 1 "Active" 0 "Inactive" ;
VAL_ 2499762532 BATT_01_iOverHardware 3 "Error" 2 "SNA" 1 "Active" 0 "Inactive" ;
VAL_ 2499762532 BATT_01_PosDcContStuckOpen 3 "Error" 2 "SNA" 1 "Active" 0 "Inactive" ;
VAL_ 2499762532 BATT_01_PosDcContWelded 3 "Error" 2 "SNA" 1 "Active" 0 "Inactive" ;
VAL_ 2499762532 BATT_01_NegDcContStuckOpen 3 "Error" 2 "SNA" 1 "Active" 0 "Inactive" ;
VAL_ 2499762532 BATT_01_NegDcContWelded 3 "Error" 2 "SNA" 1 "Active" 0 "Inactive" ;
VAL_ 2499762532 BATT_01_PrechgTooFast 3 "Error" 2 "SNA" 1 "Active" 0 "Inactive" ;
VAL_ 2499762532 BATT_01_PrechgContWelded 3 "Error" 2 "SNA" 1 "Active" 0 "Inactive" ;
VAL_ 2499762532 BATT_01_PrechgTimeout 3 "Error" 2 "SNA" 1 "Active" 0 "Inactive" ;
VAL_ 2499762532 BATT_01_PrechgContStuckOpen 3 "Error" 2 "SNA" 1 "Active" 0 "Inactive" ;
VAL_ 2499762532 BATT_01_ModuleImbalance 3 "Error" 2 "SNA" 1 "Active" 0 "Inactive" ;
VAL_ 2499762532 BATT_01_ModuleMIA 3 "Error" 2 "SNA" 1 "Active" 0 "Inactive" ;
VAL_ 2499762532 BATT_01_SensePackVoltError 3 "Error" 2 "SNA" 1 "Active" 0 "Inactive" ;
VAL_ 2499762532 BATT_01_SenseLoadVoltError 3 "Error" 2 "SNA" 1 "Active" 0 "Inactive" ;
VAL_ 2499762532 BATT_01_SenseShuntError 3 "Error" 2 "SNA" 1 "Active" 0 "Inactive" ;
VAL_ 2499762532 BATT_01_SenseFcVoltErrorr 3 "Error" 2 "SNA" 1 "Active" 0 "Inactive" ;
VAL_ 2499762532 BATT_01_Placeholder14 3 "Error" 2 "SNA" 1 "Active" 0 "Inactive" ;
VAL_ 2499762532 BATT_02_vBrickOverSev 3 "Error" 2 "SNA" 1 "Active" 0 "Inactive" ;
VAL_ 2499762532 BATT_02_vBrickOverMod 3 "Error" 2 "SNA" 1 "Active" 0 "Inactive" ;
VAL_ 2499762532 BATT_02_vBrickOverWar 3 "Error" 2 "SNA" 1 "Active" 0 "Inactive" ;
VAL_ 2499762532 BATT_02_HostQuiet 3 "Error" 2 "SNA" 1 "Active" 0 "Inactive" ;
VAL_ 2499762532 BATT_02_vBrickUnderMod 3 "Error" 2 "SNA" 1 "Active" 0 "Inactive" ;
VAL_ 2499762532 BATT_02_vBrickUnderWar 3 "Error" 2 "SNA" 1 "Active" 0 "Inactive" ;
VAL_ 2499762532 BATT_02_TempModuleOverSev 3 "Error" 2 "SNA" 1 "Active" 0 "Inactive" ;
VAL_ 2499762532 BATT_02_TempModuleOverMod 3 "Error" 2 "SNA" 1 "Active" 0 "Inactive" ;
VAL_ 2499762532 BATT_02_TempModuleOverWar 3 "Error" 2 "SNA" 1 "Active" 0 "Inactive" ;
VAL_ 2499762532 BATT_02_TempModuleUnderSev 3 "Error" 2 "SNA" 1 "Active" 0 "Inactive" ;
VAL_ 2499762532 BATT_02_TempModuleUnderMod 3 "Error" 2 "SNA" 1 "Active" 0 "Inactive" ;
VAL_ 2499762532 BATT_02_TempModuleUnderWar 3 "Error" 2 "SNA" 1 "Active" 0 "Inactive" ;
VAL_ 2499762532 BATT_02_iOverchargesev 3 "Error" 2 "SNA" 1 "Active" 0 "Inactive" ;
VAL_ 2499762532 BATT_02_iOverdischargesev 3 "Error" 2 "SNA" 1 "Active" 0 "Inactive" ;
VAL_ 2499762532 BATT_02_iOverHardware 3 "Error" 2 "SNA" 1 "Active" 0 "Inactive" ;
VAL_ 2499762532 BATT_02_PosDcContStuckOpen 3 "Error" 2 "SNA" 1 "Active" 0 "Inactive" ;
VAL_ 2499762532 BATT_02_PosDcContWelded 3 "Error" 2 "SNA" 1 "Active" 0 "Inactive" ;
VAL_ 2499762532 BATT_02_NegDcContStuckOpen 3 "Error" 2 "SNA" 1 "Active" 0 "Inactive" ;
VAL_ 2499762532 BATT_02_NegDcContWelded 3 "Error" 2 "SNA" 1 "Active" 0 "Inactive" ;
VAL_ 2499762532 BATT_02_PrechgTooFast 3 "Error" 2 "SNA" 1 "Active" 0 "Inactive" ;
VAL_ 2499762532 BATT_02_PrechgContWelded 3 "Error" 2 "SNA" 1 "Active" 0 "Inactive" ;
VAL_ 2499762532 BATT_02_PrechgTimeout 3 "Error" 2 "SNA" 1 "Active" 0 "Inactive" ;
VAL_ 2499762532 BATT_02_PrechgContStuckOpen 3 "Error" 2 "SNA" 1 "Active" 0 "Inactive" ;
VAL_ 2499762532 BATT_02_ModuleImbalance 3 "Error" 2 "SNA" 1 "Active" 0 "Inactive" ;
VAL_ 2499762532 BATT_02_ModuleMIA 3 "Error" 2 "SNA" 1 "Active" 0 "Inactive" ;
VAL_ 2499762532 BATT_02_SensePackVoltError 3 "Error" 2 "SNA" 1 "Active" 0 "Inactive" ;
VAL_ 2499762532 BATT_02_SenseLoadVoltError 3 "Error" 2 "SNA" 1 "Active" 0 "Inactive" ;
VAL_ 2499762532 BATT_02_SenseShuntError 3 "Error" 2 "SNA" 1 "Active" 0 "Inactive" ;
VAL_ 2499762532 BATT_02_SenseFcVoltErrorr 3 "Error" 2 "SNA" 1 "Active" 0 "Inactive" ;
VAL_ 2499762532 BATT_02_Placeholder14 3 "Error" 2 "SNA" 1 "Active" 0 "Inactive" ;
VAL_ 2499762532 BATT_03_vBrickOverSev 3 "Error" 2 "SNA" 1 "Active" 0 "Inactive" ;
VAL_ 2499762532 BATT_03_vBrickOverMod 3 "Error" 2 "SNA" 1 "Active" 0 "Inactive" ;
VAL_ 2499762532 BATT_03_vBrickOverWar 3 "Error" 2 "SNA" 1 "Active" 0 "Inactive" ;
VAL_ 2499762532 BATT_03_HostQuiet 3 "Error" 2 "SNA" 1 "Active" 0 "Inactive" ;
VAL_ 2499762532 BATT_03_vBrickUnderMod 3 "Error" 2 "SNA" 1 "Active" 0 "Inactive" ;
VAL_ 2499762532 BATT_03_vBrickUnderWar 3 "Error" 2 "SNA" 1 "Active" 0 "Inactive" ;
VAL_ 2499762532 BATT_03_TempModuleOverSev 3 "Error" 2 "SNA" 1 "Active" 0 "Inactive" ;
VAL_ 2499762532 BATT_03_TempModuleOverMod 3 "Error" 2 "SNA" 1 "Active" 0 "Inactive" ;
VAL_ 2499762532 BATT_03_TempModuleOverWar 3 "Error" 2 "SNA" 1 "Active" 0 "Inactive" ;
VAL_ 2499762532 BATT_03_TempModuleUnderSev 3 "Error" 2 "SNA" 1 "Active" 0 "Inactive" ;
VAL_ 2499762532 BATT_03_TempModuleUnderMod 3 "Error" 2 "SNA" 1 "Active" 0 "Inactive" ;
VAL_ 2499762532 BATT_03_TempModuleUnderWar 3 "Error" 2 "SNA" 1 "Active" 0 "Inactive" ;
VAL_ 2499762532 BATT_03_iOverchargesev 3 "Error" 2 "SNA" 1 "Active" 0 "Inactive" ;
VAL_ 2499762532 BATT_03_iOverdischargesev 3 "Error" 2 "SNA" 1 "Active" 0 "Inactive" ;
VAL_ 2499762532 BATT_03_iOverHardware 3 "Error" 2 "SNA" 1 "Active" 0 "Inactive" ;
VAL_ 2499762532 BATT_03_PosDcContStuckOpen 3 "Error" 2 "SNA" 1 "Active" 0 "Inactive" ;
VAL_ 2499762532 BATT_03_PosDcContWelded 3 "Error" 2 "SNA" 1 "Active" 0 "Inactive" ;
VAL_ 2499762532 BATT_03_NegDcContStuckOpen 3 "Error" 2 "SNA" 1 "Active" 0 "Inactive" ;
VAL_ 2499762532 BATT_03_NegDcContWelded 3 "Error" 2 "SNA" 1 "Active" 0 "Inactive" ;
VAL_ 2499762532 BATT_03_PrechgTooFast 3 "Error" 2 "SNA" 1 "Active" 0 "Inactive" ;
VAL_ 2499762532 BATT_03_PrechgContWelded 3 "Error" 2 "SNA" 1 "Active" 0 "Inactive" ;
VAL_ 2499762532 BATT_03_PrechgTimeout 3 "Error" 2 "SNA" 1 "Active" 0 "Inactive" ;
VAL_ 2499762532 BATT_03_PrechgContStuckOpen 3 "Error" 2 "SNA" 1 "Active" 0 "Inactive" ;
VAL_ 2499762532 BATT_03_ModuleImbalance 3 "Error" 2 "SNA" 1 "Active" 0 "Inactive" ;
VAL_ 2499762532 BATT_03_ModuleMIA 3 "Error" 2 "SNA" 1 "Active" 0 "Inactive" ;
VAL_ 2499762532 BATT_03_SensePackVoltError 3 "Error" 2 "SNA" 1 "Active" 0 "Inactive" ;
VAL_ 2499762532 BATT_03_SenseLoadVoltError 3 "Error" 2 "SNA" 1 "Active" 0 "Inactive" ;
VAL_ 2499762532 BATT_03_SenseShuntError 3 "Error" 2 "SNA" 1 "Active" 0 "Inactive" ;
VAL_ 2499762532 BATT_03_SenseFcVoltErrorr 3 "Error" 2 "SNA" 1 "Active" 0 "Inactive" ;
VAL_ 2499762532 BATT_03_Placeholder14 3 "Error" 2 "SNA" 1 "Active" 0 "Inactive" ;
VAL_ 2499762532 BATT_04_vBrickOverSev 3 "Error" 2 "SNA" 1 "Active" 0 "Inactive" ;
VAL_ 2499762532 BATT_04_vBrickOverMod 3 "Error" 2 "SNA" 1 "Active" 0 "Inactive" ;
VAL_ 2499762532 BATT_04_vBrickOverWar 3 "Error" 2 "SNA" 1 "Active" 0 "Inactive" ;
VAL_ 2499762532 BATT_04_HostQuiet 3 "Error" 2 "SNA" 1 "Active" 0 "Inactive" ;
VAL_ 2499762532 BATT_04_vBrickUnderMod 3 "Error" 2 "SNA" 1 "Active" 0 "Inactive" ;
VAL_ 2499762532 BATT_04_vBrickUnderWar 3 "Error" 2 "SNA" 1 "Active" 0 "Inactive" ;
VAL_ 2499762532 BATT_04_TempModuleOverSev 3 "Error" 2 "SNA" 1 "Active" 0 "Inactive" ;
VAL_ 2499762532 BATT_04_TempModuleOverMod 3 "Error" 2 "SNA" 1 "Active" 0 "Inactive" ;
VAL_ 2499762532 BATT_04_TempModuleOverWar 3 "Error" 2 "SNA" 1 "Active" 0 "Inactive" ;
VAL_ 2499762532 BATT_04_TempModuleUnderSev 3 "Error" 2 "SNA" 1 "Active" 0 "Inactive" ;
VAL_ 2499762532 BATT_04_TempModuleUnderMod 3 "Error" 2 "SNA" 1 "Active" 0 "Inactive" ;
VAL_ 2499762532 BATT_04_TempModuleUnderWar 3 "Error" 2 "SNA" 1 "Active" 0 "Inactive" ;
VAL_ 2499762532 BATT_04_iOverchargesev 3 "Error" 2 "SNA" 1 "Active" 0 "Inactive" ;
VAL_ 2499762532 BATT_04_iOverdischargesev 3 "Error" 2 "SNA" 1 "Active" 0 "Inactive" ;
VAL_ 2499762532 BATT_04_iOverHardware 3 "Error" 2 "SNA" 1 "Active" 0 "Inactive" ;
VAL_ 2499762532 BATT_04_PosDcContStuckOpen 3 "Error" 2 "SNA" 1 "Active" 0 "Inactive" ;
VAL_ 2499762532 BATT_04_PosDcContWelded 3 "Error" 2 "SNA" 1 "Active" 0 "Inactive" ;
VAL_ 2499762532 BATT_04_NegDcContStuckOpen 3 "Error" 2 "SNA" 1 "Active" 0 "Inactive" ;
VAL_ 2499762532 BATT_04_NegDcContWelded 3 "Error" 2 "SNA" 1 "Active" 0 "Inactive" ;
VAL_ 2499762532 BATT_04_PrechgTooFast 3 "Error" 2 "SNA" 1 "Active" 0 "Inactive" ;
VAL_ 2499762532 BATT_04_PrechgContWelded 3 "Error" 2 "SNA" 1 "Active" 0 "Inactive" ;
VAL_ 2499762532 BATT_04_PrechgTimeout 3 "Error" 2 "SNA" 1 "Active" 0 "Inactive" ;
VAL_ 2499762532 BATT_04_PrechgContStuckOpen 3 "Error" 2 "SNA" 1 "Active" 0 "Inactive" ;
VAL_ 2499762532 BATT_04_ModuleImbalance 3 "Error" 2 "SNA" 1 "Active" 0 "Inactive" ;
VAL_ 2499762532 BATT_04_ModuleMIA 3 "Error" 2 "SNA" 1 "Active" 0 "Inactive" ;
VAL_ 2499762532 BATT_04_SensePackVoltError 3 "Error" 2 "SNA" 1 "Active" 0 "Inactive" ;
VAL_ 2499762532 BATT_04_SenseLoadVoltError 3 "Error" 2 "SNA" 1 "Active" 0 "Inactive" ;
VAL_ 2499762532 BATT_04_SenseShuntError 3 "Error" 2 "SNA" 1 "Active" 0 "Inactive" ;
VAL_ 2499762532 BATT_04_SenseFcVoltErrorr 3 "Error" 2 "SNA" 1 "Active" 0 "Inactive" ;
VAL_ 2499762532 BATT_04_Placeholder14 3 "Error" 2 "SNA" 1 "Active" 0 "Inactive" ;
VAL_ 2499762532 BATT_05_vBrickOverSev 3 "Error" 2 "SNA" 1 "Active" 0 "Inactive" ;
VAL_ 2499762532 BATT_05_vBrickOverMod 3 "Error" 2 "SNA" 1 "Active" 0 "Inactive" ;
VAL_ 2499762532 BATT_05_vBrickOverWar 3 "Error" 2 "SNA" 1 "Active" 0 "Inactive" ;
VAL_ 2499762532 BATT_05_HostQuiet 3 "Error" 2 "SNA" 1 "Active" 0 "Inactive" ;
VAL_ 2499762532 BATT_05_vBrickUnderMod 3 "Error" 2 "SNA" 1 "Active" 0 "Inactive" ;
VAL_ 2499762532 BATT_05_vBrickUnderWar 3 "Error" 2 "SNA" 1 "Active" 0 "Inactive" ;
VAL_ 2499762532 BATT_05_TempModuleOverSev 3 "Error" 2 "SNA" 1 "Active" 0 "Inactive" ;
VAL_ 2499762532 BATT_05_TempModuleOverMod 3 "Error" 2 "SNA" 1 "Active" 0 "Inactive" ;
VAL_ 2499762532 BATT_05_TempModuleOverWar 3 "Error" 2 "SNA" 1 "Active" 0 "Inactive" ;
VAL_ 2499762532 BATT_05_TempModuleUnderSev 3 "Error" 2 "SNA" 1 "Active" 0 "Inactive" ;
VAL_ 2499762532 BATT_05_TempModuleUnderMod 3 "Error" 2 "SNA" 1 "Active" 0 "Inactive" ;
VAL_ 2499762532 BATT_05_TempModuleUnderWar 3 "Error" 2 "SNA" 1 "Active" 0 "Inactive" ;
VAL_ 2499762532 BATT_05_iOverchargesev 3 "Error" 2 "SNA" 1 "Active" 0 "Inactive" ;
VAL_ 2499762532 BATT_05_iOverdischargesev 3 "Error" 2 "SNA" 1 "Active" 0 "Inactive" ;
VAL_ 2499762532 BATT_05_iOverHardware 3 "Error" 2 "SNA" 1 "Active" 0 "Inactive" ;
VAL_ 2499762532 BATT_05_PosDcContStuckOpen 3 "Error" 2 "SNA" 1 "Active" 0 "Inactive" ;
VAL_ 2499762532 BATT_05_PosDcContWelded 3 "Error" 2 "SNA" 1 "Active" 0 "Inactive" ;
VAL_ 2499762532 BATT_05_NegDcContStuckOpen 3 "Error" 2 "SNA" 1 "Active" 0 "Inactive" ;
VAL_ 2499762532 BATT_05_NegDcContWelded 3 "Error" 2 "SNA" 1 "Active" 0 "Inactive" ;
VAL_ 2499762532 BATT_05_PrechgTooFast 3 "Error" 2 "SNA" 1 "Active" 0 "Inactive" ;
VAL_ 2499762532 BATT_05_PrechgContWelded 3 "Error" 2 "SNA" 1 "Active" 0 "Inactive" ;
VAL_ 2499762532 BATT_05_PrechgTimeout 3 "Error" 2 "SNA" 1 "Active" 0 "Inactive" ;
VAL_ 2499762532 BATT_05_PrechgContStuckOpen 3 "Error" 2 "SNA" 1 "Active" 0 "Inactive" ;
VAL_ 2499762532 BATT_05_ModuleImbalance 3 "Error" 2 "SNA" 1 "Active" 0 "Inactive" ;
VAL_ 2499762532 BATT_05_ModuleMIA 3 "Error" 2 "SNA" 1 "Active" 0 "Inactive" ;
VAL_ 2499762532 BATT_05_SensePackVoltError 3 "Error" 2 "SNA" 1 "Active" 0 "Inactive" ;
VAL_ 2499762532 BATT_05_SenseLoadVoltError 3 "Error" 2 "SNA" 1 "Active" 0 "Inactive" ;
VAL_ 2499762532 BATT_05_SenseShuntError 3 "Error" 2 "SNA" 1 "Active" 0 "Inactive" ;
VAL_ 2499762532 BATT_05_SenseFcVoltErrorr 3 "Error" 2 "SNA" 1 "Active" 0 "Inactive" ;
VAL_ 2499762532 BATT_05_Placeholder14 3 "Error" 2 "SNA" 1 "Active" 0 "Inactive" ;
VAL_ 2499762532 BATT_06_vBrickOverSev 3 "Error" 2 "SNA" 1 "Active" 0 "Inactive" ;
VAL_ 2499762532 BATT_06_vBrickOverMod 3 "Error" 2 "SNA" 1 "Active" 0 "Inactive" ;
VAL_ 2499762532 BATT_06_vBrickOverWar 3 "Error" 2 "SNA" 1 "Active" 0 "Inactive" ;
VAL_ 2499762532 BATT_06_HostQuiet 3 "Error" 2 "SNA" 1 "Active" 0 "Inactive" ;
VAL_ 2499762532 BATT_06_vBrickUnderMod 3 "Error" 2 "SNA" 1 "Active" 0 "Inactive" ;
VAL_ 2499762532 BATT_06_vBrickUnderWar 3 "Error" 2 "SNA" 1 "Active" 0 "Inactive" ;
VAL_ 2499762532 BATT_06_TempModuleOverSev 3 "Error" 2 "SNA" 1 "Active" 0 "Inactive" ;
VAL_ 2499762532 BATT_06_TempModuleOverMod 3 "Error" 2 "SNA" 1 "Active" 0 "Inactive" ;
VAL_ 2499762532 BATT_06_TempModuleOverWar 3 "Error" 2 "SNA" 1 "Active" 0 "Inactive" ;
VAL_ 2499762532 BATT_06_TempModuleUnderSev 3 "Error" 2 "SNA" 1 "Active" 0 "Inactive" ;
VAL_ 2499762532 BATT_06_TempModuleUnderMod 3 "Error" 2 "SNA" 1 "Active" 0 "Inactive" ;
VAL_ 2499762532 BATT_06_TempModuleUnderWar 3 "Error" 2 "SNA" 1 "Active" 0 "Inactive" ;
VAL_ 2499762532 BATT_06_iOverchargesev 3 "Error" 2 "SNA" 1 "Active" 0 "Inactive" ;
VAL_ 2499762532 BATT_06_iOverdischargesev 3 "Error" 2 "SNA" 1 "Active" 0 "Inactive" ;
VAL_ 2499762532 BATT_06_iOverHardware 3 "Error" 2 "SNA" 1 "Active" 0 "Inactive" ;
VAL_ 2499762532 BATT_06_PosDcContStuckOpen 3 "Error" 2 "SNA" 1 "Active" 0 "Inactive" ;
VAL_ 2499762532 BATT_06_PosDcContWelded 3 "Error" 2 "SNA" 1 "Active" 0 "Inactive" ;
VAL_ 2499762532 BATT_06_NegDcContStuckOpen 3 "Error" 2 "SNA" 1 "Active" 0 "Inactive" ;
VAL_ 2499762532 BATT_06_NegDcContWelded 3 "Error" 2 "SNA" 1 "Active" 0 "Inactive" ;
VAL_ 2499762532 BATT_06_PrechgTooFast 3 "Error" 2 "SNA" 1 "Active" 0 "Inactive" ;
VAL_ 2499762532 BATT_06_PrechgContWelded 3 "Error" 2 "SNA" 1 "Active" 0 "Inactive" ;
VAL_ 2499762532 BATT_06_PrechgTimeout 3 "Error" 2 "SNA" 1 "Active" 0 "Inactive" ;
VAL_ 2499762532 BATT_06_PrechgContStuckOpen 3 "Error" 2 "SNA" 1 "Active" 0 "Inactive" ;
VAL_ 2499762532 BATT_06_ModuleImbalance 3 "Error" 2 "SNA" 1 "Active" 0 "Inactive" ;
VAL_ 2499762532 BATT_06_ModuleMIA 3 "Error" 2 "SNA" 1 "Active" 0 "Inactive" ;
VAL_ 2499762532 BATT_06_SensePackVoltError 3 "Error" 2 "SNA" 1 "Active" 0 "Inactive" ;
VAL_ 2499762532 BATT_06_SenseLoadVoltError 3 "Error" 2 "SNA" 1 "Active" 0 "Inactive" ;
VAL_ 2499762532 BATT_06_SenseShuntError 3 "Error" 2 "SNA" 1 "Active" 0 "Inactive" ;
VAL_ 2499762532 BATT_06_SenseFcVoltErrorr 3 "Error" 2 "SNA" 1 "Active" 0 "Inactive" ;
VAL_ 2499762532 BATT_06_Placeholder14 3 "Error" 2 "SNA" 1 "Active" 0 "Inactive" ;
VAL_ 2499762532 BATT_07_vBrickOverSev 3 "Error" 2 "SNA" 1 "Active" 0 "Inactive" ;
VAL_ 2499762532 BATT_07_vBrickOverMod 3 "Error" 2 "SNA" 1 "Active" 0 "Inactive" ;
VAL_ 2499762532 BATT_07_vBrickOverWar 3 "Error" 2 "SNA" 1 "Active" 0 "Inactive" ;
VAL_ 2499762532 BATT_07_HostQuiet 3 "Error" 2 "SNA" 1 "Active" 0 "Inactive" ;
VAL_ 2499762532 BATT_07_vBrickUnderMod 3 "Error" 2 "SNA" 1 "Active" 0 "Inactive" ;
VAL_ 2499762532 BATT_07_vBrickUnderWar 3 "Error" 2 "SNA" 1 "Active" 0 "Inactive" ;
VAL_ 2499762532 BATT_07_TempModuleOverSev 3 "Error" 2 "SNA" 1 "Active" 0 "Inactive" ;
VAL_ 2499762532 BATT_07_TempModuleOverMod 3 "Error" 2 "SNA" 1 "Active" 0 "Inactive" ;
VAL_ 2499762532 BATT_07_TempModuleOverWar 3 "Error" 2 "SNA" 1 "Active" 0 "Inactive" ;
VAL_ 2499762532 BATT_07_TempModuleUnderSev 3 "Error" 2 "SNA" 1 "Active" 0 "Inactive" ;
VAL_ 2499762532 BATT_07_TempModuleUnderMod 3 "Error" 2 "SNA" 1 "Active" 0 "Inactive" ;
VAL_ 2499762532 BATT_07_TempModuleUnderWar 3 "Error" 2 "SNA" 1 "Active" 0 "Inactive" ;
VAL_ 2499762532 BATT_07_iOverchargesev 3 "Error" 2 "SNA" 1 "Active" 0 "Inactive" ;
VAL_ 2499762532 BATT_07_iOverdischargesev 3 "Error" 2 "SNA" 1 "Active" 0 "Inactive" ;
VAL_ 2499762532 BATT_07_iOverHardware 3 "Error" 2 "SNA" 1 "Active" 0 "Inactive" ;
VAL_ 2499762532 BATT_07_PosDcContStuckOpen 3 "Error" 2 "SNA" 1 "Active" 0 "Inactive" ;
VAL_ 2499762532 BATT_07_PosDcContWelded 3 "Error" 2 "SNA" 1 "Active" 0 "Inactive" ;
VAL_ 2499762532 BATT_07_NegDcContStuckOpen 3 "Error" 2 "SNA" 1 "Active" 0 "Inactive" ;
VAL_ 2499762532 BATT_07_NegDcContWelded 3 "Error" 2 "SNA" 1 "Active" 0 "Inactive" ;
VAL_ 2499762532 BATT_07_PrechgTooFast 3 "Error" 2 "SNA" 1 "Active" 0 "Inactive" ;
VAL_ 2499762532 BATT_07_PrechgContWelded 3 "Error" 2 "SNA" 1 "Active" 0 "Inactive" ;
VAL_ 2499762532 BATT_07_PrechgTimeout 3 "Error" 2 "SNA" 1 "Active" 0 "Inactive" ;
VAL_ 2499762532 BATT_07_PrechgContStuckOpen 3 "Error" 2 "SNA" 1 "Active" 0 "Inactive" ;
VAL_ 2499762532 BATT_07_ModuleImbalance 3 "Error" 2 "SNA" 1 "Active" 0 "Inactive" ;
VAL_ 2499762532 BATT_07_ModuleMIA 3 "Error" 2 "SNA" 1 "Active" 0 "Inactive" ;
VAL_ 2499762532 BATT_07_SensePackVoltError 3 "Error" 2 "SNA" 1 "Active" 0 "Inactive" ;
VAL_ 2499762532 BATT_07_SenseLoadVoltError 3 "Error" 2 "SNA" 1 "Active" 0 "Inactive" ;
VAL_ 2499762532 BATT_07_SenseShuntError 3 "Error" 2 "SNA" 1 "Active" 0 "Inactive" ;
VAL_ 2499762532 BATT_07_SenseFcVoltErrorr 3 "Error" 2 "SNA" 1 "Active" 0 "Inactive" ;
VAL_ 2499762532 BATT_07_Placeholder14 3 "Error" 2 "SNA" 1 "Active" 0 "Inactive" ;
VAL_ 2499762532 BATT_08_vBrickOverSev 3 "Error" 2 "SNA" 1 "Active" 0 "Inactive" ;
VAL_ 2499762532 BATT_08_vBrickOverMod 3 "Error" 2 "SNA" 1 "Active" 0 "Inactive" ;
VAL_ 2499762532 BATT_08_vBrickOverWar 3 "Error" 2 "SNA" 1 "Active" 0 "Inactive" ;
VAL_ 2499762532 BATT_08_HostQuiet 3 "Error" 2 "SNA" 1 "Active" 0 "Inactive" ;
VAL_ 2499762532 BATT_08_vBrickUnderMod 3 "Error" 2 "SNA" 1 "Active" 0 "Inactive" ;
VAL_ 2499762532 BATT_08_vBrickUnderWar 3 "Error" 2 "SNA" 1 "Active" 0 "Inactive" ;
VAL_ 2499762532 BATT_08_TempModuleOverSev 3 "Error" 2 "SNA" 1 "Active" 0 "Inactive" ;
VAL_ 2499762532 BATT_08_TempModuleOverMod 3 "Error" 2 "SNA" 1 "Active" 0 "Inactive" ;
VAL_ 2499762532 BATT_08_TempModuleOverWar 3 "Error" 2 "SNA" 1 "Active" 0 "Inactive" ;
VAL_ 2499762532 BATT_08_TempModuleUnderSev 3 "Error" 2 "SNA" 1 "Active" 0 "Inactive" ;
VAL_ 2499762532 BATT_08_TempModuleUnderMod 3 "Error" 2 "SNA" 1 "Active" 0 "Inactive" ;
VAL_ 2499762532 BATT_08_TempModuleUnderWar 3 "Error" 2 "SNA" 1 "Active" 0 "Inactive" ;
VAL_ 2499762532 BATT_08_iOverchargesev 3 "Error" 2 "SNA" 1 "Active" 0 "Inactive" ;
VAL_ 2499762532 BATT_08_iOverdischargesev 3 "Error" 2 "SNA" 1 "Active" 0 "Inactive" ;
VAL_ 2499762532 BATT_08_iOverHardware 3 "Error" 2 "SNA" 1 "Active" 0 "Inactive" ;
VAL_ 2499762532 BATT_08_PosDcContStuckOpen 3 "Error" 2 "SNA" 1 "Active" 0 "Inactive" ;
VAL_ 2499762532 BATT_08_PosDcContWelded 3 "Error" 2 "SNA" 1 "Active" 0 "Inactive" ;
VAL_ 2499762532 BATT_08_NegDcContStuckOpen 3 "Error" 2 "SNA" 1 "Active" 0 "Inactive" ;
VAL_ 2499762532 BATT_08_NegDcContWelded 3 "Error" 2 "SNA" 1 "Active" 0 "Inactive" ;
VAL_ 2499762532 BATT_08_PrechgTooFast 3 "Error" 2 "SNA" 1 "Active" 0 "Inactive" ;
VAL_ 2499762532 BATT_08_PrechgContWelded 3 "Error" 2 "SNA" 1 "Active" 0 "Inactive" ;
VAL_ 2499762532 BATT_08_PrechgTimeout 3 "Error" 2 "SNA" 1 "Active" 0 "Inactive" ;
VAL_ 2499762532 BATT_08_PrechgContStuckOpen 3 "Error" 2 "SNA" 1 "Active" 0 "Inactive" ;
VAL_ 2499762532 BATT_08_ModuleImbalance 3 "Error" 2 "SNA" 1 "Active" 0 "Inactive" ;
VAL_ 2499762532 BATT_08_ModuleMIA 3 "Error" 2 "SNA" 1 "Active" 0 "Inactive" ;
VAL_ 2499762532 BATT_08_SensePackVoltError 3 "Error" 2 "SNA" 1 "Active" 0 "Inactive" ;
VAL_ 2499762532 BATT_08_SenseLoadVoltError 3 "Error" 2 "SNA" 1 "Active" 0 "Inactive" ;
VAL_ 2499762532 BATT_08_SenseShuntError 3 "Error" 2 "SNA" 1 "Active" 0 "Inactive" ;
VAL_ 2499762532 BATT_08_SenseFcVoltErrorr 3 "Error" 2 "SNA" 1 "Active" 0 "Inactive" ;
VAL_ 2499762532 BATT_08_Placeholder14 3 "Error" 2 "SNA" 1 "Active" 0 "Inactive" ;
VAL_ 2499762532 BATT_09_vBrickOverSev 3 "Error" 2 "SNA" 1 "Active" 0 "Inactive" ;
VAL_ 2499762532 BATT_09_vBrickOverMod 3 "Error" 2 "SNA" 1 "Active" 0 "Inactive" ;
VAL_ 2499762532 BATT_09_vBrickOverWar 3 "Error" 2 "SNA" 1 "Active" 0 "Inactive" ;
VAL_ 2499762532 BATT_09_HostQuiet 3 "Error" 2 "SNA" 1 "Active" 0 "Inactive" ;
VAL_ 2499762532 BATT_09_vBrickUnderMod 3 "Error" 2 "SNA" 1 "Active" 0 "Inactive" ;
VAL_ 2499762532 BATT_09_vBrickUnderWar 3 "Error" 2 "SNA" 1 "Active" 0 "Inactive" ;
VAL_ 2499762532 BATT_09_TempModuleOverSev 3 "Error" 2 "SNA" 1 "Active" 0 "Inactive" ;
VAL_ 2499762532 BATT_09_TempModuleOverMod 3 "Error" 2 "SNA" 1 "Active" 0 "Inactive" ;
VAL_ 2499762532 BATT_09_TempModuleOverWar 3 "Error" 2 "SNA" 1 "Active" 0 "Inactive" ;
VAL_ 2499762532 BATT_09_TempModuleUnderSev 3 "Error" 2 "SNA" 1 "Active" 0 "Inactive" ;
VAL_ 2499762532 BATT_09_TempModuleUnderMod 3 "Error" 2 "SNA" 1 "Active" 0 "Inactive" ;
VAL_ 2499762532 BATT_09_TempModuleUnderWar 3 "Error" 2 "SNA" 1 "Active" 0 "Inactive" ;
VAL_ 2499762532 BATT_09_iOverchargesev 3 "Error" 2 "SNA" 1 "Active" 0 "Inactive" ;
VAL_ 2499762532 BATT_09_iOverdischargesev 3 "Error" 2 "SNA" 1 "Active" 0 "Inactive" ;
VAL_ 2499762532 BATT_09_iOverHardware 3 "Error" 2 "SNA" 1 "Active" 0 "Inactive" ;
VAL_ 2499762532 BATT_09_PosDcContStuckOpen 3 "Error" 2 "SNA" 1 "Active" 0 "Inactive" ;
VAL_ 2499762532 BATT_09_PosDcContWelded 3 "Error" 2 "SNA" 1 "Active" 0 "Inactive" ;
VAL_ 2499762532 BATT_09_NegDcContStuckOpen 3 "Error" 2 "SNA" 1 "Active" 0 "Inactive" ;
VAL_ 2499762532 BATT_09_NegDcContWelded 3 "Error" 2 "SNA" 1 "Active" 0 "Inactive" ;
VAL_ 2499762532 BATT_09_PrechgTooFast 3 "Error" 2 "SNA" 1 "Active" 0 "Inactive" ;
VAL_ 2499762532 BATT_09_PrechgContWelded 3 "Error" 2 "SNA" 1 "Active" 0 "Inactive" ;
VAL_ 2499762532 BATT_09_PrechgTimeout 3 "Error" 2 "SNA" 1 "Active" 0 "Inactive" ;
VAL_ 2499762532 BATT_09_PrechgContStuckOpen 3 "Error" 2 "SNA" 1 "Active" 0 "Inactive" ;
VAL_ 2499762532 BATT_09_ModuleImbalance 3 "Error" 2 "SNA" 1 "Active" 0 "Inactive" ;
VAL_ 2499762532 BATT_09_ModuleMIA 3 "Error" 2 "SNA" 1 "Active" 0 "Inactive" ;
VAL_ 2499762532 BATT_09_SensePackVoltError 3 "Error" 2 "SNA" 1 "Active" 0 "Inactive" ;
VAL_ 2499762532 BATT_09_SenseLoadVoltError 3 "Error" 2 "SNA" 1 "Active" 0 "Inactive" ;
VAL_ 2499762532 BATT_09_SenseShuntError 3 "Error" 2 "SNA" 1 "Active" 0 "Inactive" ;
VAL_ 2499762532 BATT_09_SenseFcVoltErrorr 3 "Error" 2 "SNA" 1 "Active" 0 "Inactive" ;
VAL_ 2499762532 BATT_09_Placeholder14 3 "Error" 2 "SNA" 1 "Active" 0 "Inactive" ;
VAL_ 2499762532 BATT_10_vBrickOverSev 3 "Error" 2 "SNA" 1 "Active" 0 "Inactive" ;
VAL_ 2499762532 BATT_10_vBrickOverMod 3 "Error" 2 "SNA" 1 "Active" 0 "Inactive" ;
VAL_ 2499762532 BATT_10_vBrickOverWar 3 "Error" 2 "SNA" 1 "Active" 0 "Inactive" ;
VAL_ 2499762532 BATT_10_HostQuiet 3 "Error" 2 "SNA" 1 "Active" 0 "Inactive" ;
VAL_ 2499762532 BATT_10_vBrickUnderMod 3 "Error" 2 "SNA" 1 "Active" 0 "Inactive" ;
VAL_ 2499762532 BATT_10_vBrickUnderWar 3 "Error" 2 "SNA" 1 "Active" 0 "Inactive" ;
VAL_ 2499762532 BATT_10_TempModuleOverSev 3 "Error" 2 "SNA" 1 "Active" 0 "Inactive" ;
VAL_ 2499762532 BATT_10_TempModuleOverMod 3 "Error" 2 "SNA" 1 "Active" 0 "Inactive" ;
VAL_ 2499762532 BATT_10_TempModuleOverWar 3 "Error" 2 "SNA" 1 "Active" 0 "Inactive" ;
VAL_ 2499762532 BATT_10_TempModuleUnderSev 3 "Error" 2 "SNA" 1 "Active" 0 "Inactive" ;
VAL_ 2499762532 BATT_10_TempModuleUnderMod 3 "Error" 2 "SNA" 1 "Active" 0 "Inactive" ;
VAL_ 2499762532 BATT_10_TempModuleUnderWar 3 "Error" 2 "SNA" 1 "Active" 0 "Inactive" ;
VAL_ 2499762532 BATT_10_iOverchargesev 3 "Error" 2 "SNA" 1 "Active" 0 "Inactive" ;
VAL_ 2499762532 BATT_10_iOverdischargesev 3 "Error" 2 "SNA" 1 "Active" 0 "Inactive" ;
VAL_ 2499762532 BATT_10_iOverHardware 3 "Error" 2 "SNA" 1 "Active" 0 "Inactive" ;
VAL_ 2499762532 BATT_10_PosDcContStuckOpen 3 "Error" 2 "SNA" 1 "Active" 0 "Inactive" ;
VAL_ 2499762532 BATT_10_PosDcContWelded 3 "Error" 2 "SNA" 1 "Active" 0 "Inactive" ;
VAL_ 2499762532 BATT_10_NegDcContStuckOpen 3 "Error" 2 "SNA" 1 "Active" 0 "Inactive" ;
VAL_ 2499762532 BATT_10_NegDcContWelded 3 "Error" 2 "SNA" 1 "Active" 0 "Inactive" ;
VAL_ 2499762532 BATT_10_PrechgTooFast 3 "Error" 2 "SNA" 1 "Active" 0 "Inactive" ;
VAL_ 2499762532 BATT_10_PrechgContWelded 3 "Error" 2 "SNA" 1 "Active" 0 "Inactive" ;
VAL_ 2499762532 BATT_10_PrechgTimeout 3 "Error" 2 "SNA" 1 "Active" 0 "Inactive" ;
VAL_ 2499762532 BATT_10_PrechgContStuckOpen 3 "Error" 2 "SNA" 1 "Active" 0 "Inactive" ;
VAL_ 2499762532 BATT_10_ModuleImbalance 3 "Error" 2 "SNA" 1 "Active" 0 "Inactive" ;
VAL_ 2499762532 BATT_10_ModuleMIA 3 "Error" 2 "SNA" 1 "Active" 0 "Inactive" ;
VAL_ 2499762532 BATT_10_SensePackVoltError 3 "Error" 2 "SNA" 1 "Active" 0 "Inactive" ;
VAL_ 2499762532 BATT_10_SenseLoadVoltError 3 "Error" 2 "SNA" 1 "Active" 0 "Inactive" ;
VAL_ 2499762532 BATT_10_SenseShuntError 3 "Error" 2 "SNA" 1 "Active" 0 "Inactive" ;
VAL_ 2499762532 BATT_10_SenseFcVoltErrorr 3 "Error" 2 "SNA" 1 "Active" 0 "Inactive" ;
VAL_ 2499762532 BATT_10_Placeholder14 3 "Error" 2 "SNA" 1 "Active" 0 "Inactive" ;
VAL_ 2499762532 BATT_11_vBrickOverSev 3 "Error" 2 "SNA" 1 "Active" 0 "Inactive" ;
VAL_ 2499762532 BATT_11_vBrickOverMod 3 "Error" 2 "SNA" 1 "Active" 0 "Inactive" ;
VAL_ 2499762532 BATT_11_vBrickOverWar 3 "Error" 2 "SNA" 1 "Active" 0 "Inactive" ;
VAL_ 2499762532 BATT_11_HostQuiet 3 "Error" 2 "SNA" 1 "Active" 0 "Inactive" ;
VAL_ 2499762532 BATT_11_vBrickUnderMod 3 "Error" 2 "SNA" 1 "Active" 0 "Inactive" ;
VAL_ 2499762532 BATT_11_vBrickUnderWar 3 "Error" 2 "SNA" 1 "Active" 0 "Inactive" ;
VAL_ 2499762532 BATT_11_TempModuleOverSev 3 "Error" 2 "SNA" 1 "Active" 0 "Inactive" ;
VAL_ 2499762532 BATT_11_TempModuleOverMod 3 "Error" 2 "SNA" 1 "Active" 0 "Inactive" ;
VAL_ 2499762532 BATT_11_TempModuleOverWar 3 "Error" 2 "SNA" 1 "Active" 0 "Inactive" ;
VAL_ 2499762532 BATT_11_TempModuleUnderSev 3 "Error" 2 "SNA" 1 "Active" 0 "Inactive" ;
VAL_ 2499762532 BATT_11_TempModuleUnderMod 3 "Error" 2 "SNA" 1 "Active" 0 "Inactive" ;
VAL_ 2499762532 BATT_11_TempModuleUnderWar 3 "Error" 2 "SNA" 1 "Active" 0 "Inactive" ;
VAL_ 2499762532 BATT_11_iOverchargesev 3 "Error" 2 "SNA" 1 "Active" 0 "Inactive" ;
VAL_ 2499762532 BATT_11_iOverdischargesev 3 "Error" 2 "SNA" 1 "Active" 0 "Inactive" ;
VAL_ 2499762532 BATT_11_iOverHardware 3 "Error" 2 "SNA" 1 "Active" 0 "Inactive" ;
VAL_ 2499762532 BATT_11_PosDcContStuckOpen 3 "Error" 2 "SNA" 1 "Active" 0 "Inactive" ;
VAL_ 2499762532 BATT_11_PosDcContWelded 3 "Error" 2 "SNA" 1 "Active" 0 "Inactive" ;
VAL_ 2499762532 BATT_11_NegDcContStuckOpen 3 "Error" 2 "SNA" 1 "Active" 0 "Inactive" ;
VAL_ 2499762532 BATT_11_NegDcContWelded 3 "Error" 2 "SNA" 1 "Active" 0 "Inactive" ;
VAL_ 2499762532 BATT_11_PrechgTooFast 3 "Error" 2 "SNA" 1 "Active" 0 "Inactive" ;
VAL_ 2499762532 BATT_11_PrechgContWelded 3 "Error" 2 "SNA" 1 "Active" 0 "Inactive" ;
VAL_ 2499762532 BATT_11_PrechgTimeout 3 "Error" 2 "SNA" 1 "Active" 0 "Inactive" ;
VAL_ 2499762532 BATT_11_PrechgContStuckOpen 3 "Error" 2 "SNA" 1 "Active" 0 "Inactive" ;
VAL_ 2499762532 BATT_11_ModuleImbalance 3 "Error" 2 "SNA" 1 "Active" 0 "Inactive" ;
VAL_ 2499762532 BATT_11_ModuleMIA 3 "Error" 2 "SNA" 1 "Active" 0 "Inactive" ;
VAL_ 2499762532 BATT_11_SensePackVoltError 3 "Error" 2 "SNA" 1 "Active" 0 "Inactive" ;
VAL_ 2499762532 BATT_11_SenseLoadVoltError 3 "Error" 2 "SNA" 1 "Active" 0 "Inactive" ;
VAL_ 2499762532 BATT_11_SenseShuntError 3 "Error" 2 "SNA" 1 "Active" 0 "Inactive" ;
VAL_ 2499762532 BATT_11_SenseFcVoltErrorr 3 "Error" 2 "SNA" 1 "Active" 0 "Inactive" ;
VAL_ 2499762532 BATT_11_Placeholder14 3 "Error" 2 "SNA" 1 "Active" 0 "Inactive" ;
VAL_ 2499762532 BATT_12_vBrickOverSev 3 "Error" 2 "SNA" 1 "Active" 0 "Inactive" ;
VAL_ 2499762532 BATT_12_vBrickOverMod 3 "Error" 2 "SNA" 1 "Active" 0 "Inactive" ;
VAL_ 2499762532 BATT_12_vBrickOverWar 3 "Error" 2 "SNA" 1 "Active" 0 "Inactive" ;
VAL_ 2499762532 BATT_12_HostQuiet 3 "Error" 2 "SNA" 1 "Active" 0 "Inactive" ;
VAL_ 2499762532 BATT_12_vBrickUnderMod 3 "Error" 2 "SNA" 1 "Active" 0 "Inactive" ;
VAL_ 2499762532 BATT_12_vBrickUnderWar 3 "Error" 2 "SNA" 1 "Active" 0 "Inactive" ;
VAL_ 2499762532 BATT_12_TempModuleOverSev 3 "Error" 2 "SNA" 1 "Active" 0 "Inactive" ;
VAL_ 2499762532 BATT_12_TempModuleOverMod 3 "Error" 2 "SNA" 1 "Active" 0 "Inactive" ;
VAL_ 2499762532 BATT_12_TempModuleOverWar 3 "Error" 2 "SNA" 1 "Active" 0 "Inactive" ;
VAL_ 2499762532 BATT_12_TempModuleUnderSev 3 "Error" 2 "SNA" 1 "Active" 0 "Inactive" ;
VAL_ 2499762532 BATT_12_TempModuleUnderMod 3 "Error" 2 "SNA" 1 "Active" 0 "Inactive" ;
VAL_ 2499762532 BATT_12_TempModuleUnderWar 3 "Error" 2 "SNA" 1 "Active" 0 "Inactive" ;
VAL_ 2499762532 BATT_12_iOverchargesev 3 "Error" 2 "SNA" 1 "Active" 0 "Inactive" ;
VAL_ 2499762532 BATT_12_iOverdischargesev 3 "Error" 2 "SNA" 1 "Active" 0 "Inactive" ;
VAL_ 2499762532 BATT_12_iOverHardware 3 "Error" 2 "SNA" 1 "Active" 0 "Inactive" ;
VAL_ 2499762532 BATT_12_PosDcContStuckOpen 3 "Error" 2 "SNA" 1 "Active" 0 "Inactive" ;
VAL_ 2499762532 BATT_12_PosDcContWelded 3 "Error" 2 "SNA" 1 "Active" 0 "Inactive" ;
VAL_ 2499762532 BATT_12_NegDcContStuckOpen 3 "Error" 2 "SNA" 1 "Active" 0 "Inactive" ;
VAL_ 2499762532 BATT_12_NegDcContWelded 3 "Error" 2 "SNA" 1 "Active" 0 "Inactive" ;
VAL_ 2499762532 BATT_12_PrechgTooFast 3 "Error" 2 "SNA" 1 "Active" 0 "Inactive" ;
VAL_ 2499762532 BATT_12_PrechgContWelded 3 "Error" 2 "SNA" 1 "Active" 0 "Inactive" ;
VAL_ 2499762532 BATT_12_PrechgTimeout 3 "Error" 2 "SNA" 1 "Active" 0 "Inactive" ;
VAL_ 2499762532 BATT_12_PrechgContStuckOpen 3 "Error" 2 "SNA" 1 "Active" 0 "Inactive" ;
VAL_ 2499762532 BATT_12_ModuleImbalance 3 "Error" 2 "SNA" 1 "Active" 0 "Inactive" ;
VAL_ 2499762532 BATT_12_ModuleMIA 3 "Error" 2 "SNA" 1 "Active" 0 "Inactive" ;
VAL_ 2499762532 BATT_12_SensePackVoltError 3 "Error" 2 "SNA" 1 "Active" 0 "Inactive" ;
VAL_ 2499762532 BATT_12_SenseLoadVoltError 3 "Error" 2 "SNA" 1 "Active" 0 "Inactive" ;
VAL_ 2499762532 BATT_12_SenseShuntError 3 "Error" 2 "SNA" 1 "Active" 0 "Inactive" ;
VAL_ 2499762532 BATT_12_SenseFcVoltErrorr 3 "Error" 2 "SNA" 1 "Active" 0 "Inactive" ;
VAL_ 2499762532 BATT_12_Placeholder14 3 "Error" 2 "SNA" 1 "Active" 0 "Inactive" ;
VAL_ 2499762532 BATT_13_vBrickOverSev 3 "Error" 2 "SNA" 1 "Active" 0 "Inactive" ;
VAL_ 2499762532 BATT_13_vBrickOverMod 3 "Error" 2 "SNA" 1 "Active" 0 "Inactive" ;
VAL_ 2499762532 BATT_13_vBrickOverWar 3 "Error" 2 "SNA" 1 "Active" 0 "Inactive" ;
VAL_ 2499762532 BATT_13_HostQuiet 3 "Error" 2 "SNA" 1 "Active" 0 "Inactive" ;
VAL_ 2499762532 BATT_13_vBrickUnderMod 3 "Error" 2 "SNA" 1 "Active" 0 "Inactive" ;
VAL_ 2499762532 BATT_13_vBrickUnderWar 3 "Error" 2 "SNA" 1 "Active" 0 "Inactive" ;
VAL_ 2499762532 BATT_13_TempModuleOverSev 3 "Error" 2 "SNA" 1 "Active" 0 "Inactive" ;
VAL_ 2499762532 BATT_13_TempModuleOverMod 3 "Error" 2 "SNA" 1 "Active" 0 "Inactive" ;
VAL_ 2499762532 BATT_13_TempModuleOverWar 3 "Error" 2 "SNA" 1 "Active" 0 "Inactive" ;
VAL_ 2499762532 BATT_13_TempModuleUnderSev 3 "Error" 2 "SNA" 1 "Active" 0 "Inactive" ;
VAL_ 2499762532 BATT_13_TempModuleUnderMod 3 "Error" 2 "SNA" 1 "Active" 0 "Inactive" ;
VAL_ 2499762532 BATT_13_TempModuleUnderWar 3 "Error" 2 "SNA" 1 "Active" 0 "Inactive" ;
VAL_ 2499762532 BATT_13_iOverchargesev 3 "Error" 2 "SNA" 1 "Active" 0 "Inactive" ;
VAL_ 2499762532 BATT_13_iOverdischargesev 3 "Error" 2 "SNA" 1 "Active" 0 "Inactive" ;
VAL_ 2499762532 BATT_13_iOverHardware 3 "Error" 2 "SNA" 1 "Active" 0 "Inactive" ;
VAL_ 2499762532 BATT_13_PosDcContStuckOpen 3 "Error" 2 "SNA" 1 "Active" 0 "Inactive" ;
VAL_ 2499762532 BATT_13_PosDcContWelded 3 "Error" 2 "SNA" 1 "Active" 0 "Inactive" ;
VAL_ 2499762532 BATT_13_NegDcContStuckOpen 3 "Error" 2 "SNA" 1 "Active" 0 "Inactive" ;
VAL_ 2499762532 BATT_13_NegDcContWelded 3 "Error" 2 "SNA" 1 "Active" 0 "Inactive" ;
VAL_ 2499762532 BATT_13_PrechgTooFast 3 "Error" 2 "SNA" 1 "Active" 0 "Inactive" ;
VAL_ 2499762532 BATT_13_PrechgContWelded 3 "Error" 2 "SNA" 1 "Active" 0 "Inactive" ;
VAL_ 2499762532 BATT_13_PrechgTimeout 3 "Error" 2 "SNA" 1 "Active" 0 "Inactive" ;
VAL_ 2499762532 BATT_13_PrechgContStuckOpen 3 "Error" 2 "SNA" 1 "Active" 0 "Inactive" ;
VAL_ 2499762532 BATT_13_ModuleImbalance 3 "Error" 2 "SNA" 1 "Active" 0 "Inactive" ;
VAL_ 2499762532 BATT_13_ModuleMIA 3 "Error" 2 "SNA" 1 "Active" 0 "Inactive" ;
VAL_ 2499762532 BATT_13_SensePackVoltError 3 "Error" 2 "SNA" 1 "Active" 0 "Inactive" ;
VAL_ 2499762532 BATT_13_SenseLoadVoltError 3 "Error" 2 "SNA" 1 "Active" 0 "Inactive" ;
VAL_ 2499762532 BATT_13_SenseShuntError 3 "Error" 2 "SNA" 1 "Active" 0 "Inactive" ;
VAL_ 2499762532 BATT_13_SenseFcVoltErrorr 3 "Error" 2 "SNA" 1 "Active" 0 "Inactive" ;
VAL_ 2499762532 BATT_13_Placeholder14 3 "Error" 2 "SNA" 1 "Active" 0 "Inactive" ;
VAL_ 2499762532 BATT_14_vBrickOverSev 3 "Error" 2 "SNA" 1 "Active" 0 "Inactive" ;
VAL_ 2499762532 BATT_14_vBrickOverMod 3 "Error" 2 "SNA" 1 "Active" 0 "Inactive" ;
VAL_ 2499762532 BATT_14_vBrickOverWar 3 "Error" 2 "SNA" 1 "Active" 0 "Inactive" ;
VAL_ 2499762532 BATT_14_HostQuiet 3 "Error" 2 "SNA" 1 "Active" 0 "Inactive" ;
VAL_ 2499762532 BATT_14_vBrickUnderMod 3 "Error" 2 "SNA" 1 "Active" 0 "Inactive" ;
VAL_ 2499762532 BATT_14_vBrickUnderWar 3 "Error" 2 "SNA" 1 "Active" 0 "Inactive" ;
VAL_ 2499762532 BATT_14_TempModuleOverSev 3 "Error" 2 "SNA" 1 "Active" 0 "Inactive" ;
VAL_ 2499762532 BATT_14_TempModuleOverMod 3 "Error" 2 "SNA" 1 "Active" 0 "Inactive" ;
VAL_ 2499762532 BATT_14_TempModuleOverWar 3 "Error" 2 "SNA" 1 "Active" 0 "Inactive" ;
VAL_ 2499762532 BATT_14_TempModuleUnderSev 3 "Error" 2 "SNA" 1 "Active" 0 "Inactive" ;
VAL_ 2499762532 BATT_14_TempModuleUnderMod 3 "Error" 2 "SNA" 1 "Active" 0 "Inactive" ;
VAL_ 2499762532 BATT_14_TempModuleUnderWar 3 "Error" 2 "SNA" 1 "Active" 0 "Inactive" ;
VAL_ 2499762532 BATT_14_iOverchargesev 3 "Error" 2 "SNA" 1 "Active" 0 "Inactive" ;
VAL_ 2499762532 BATT_14_iOverdischargesev 3 "Error" 2 "SNA" 1 "Active" 0 "Inactive" ;
VAL_ 2499762532 BATT_14_iOverHardware 3 "Error" 2 "SNA" 1 "Active" 0 "Inactive" ;
VAL_ 2499762532 BATT_14_PosDcContStuckOpen 3 "Error" 2 "SNA" 1 "Active" 0 "Inactive" ;
VAL_ 2499762532 BATT_14_PosDcContWelded 3 "Error" 2 "SNA" 1 "Active" 0 "Inactive" ;
VAL_ 2499762532 BATT_14_NegDcContStuckOpen 3 "Error" 2 "SNA" 1 "Active" 0 "Inactive" ;
VAL_ 2499762532 BATT_14_NegDcContWelded 3 "Error" 2 "SNA" 1 "Active" 0 "Inactive" ;
VAL_ 2499762532 BATT_14_PrechgTooFast 3 "Error" 2 "SNA" 1 "Active" 0 "Inactive" ;
VAL_ 2499762532 BATT_14_PrechgContWelded 3 "Error" 2 "SNA" 1 "Active" 0 "Inactive" ;
VAL_ 2499762532 BATT_14_PrechgTimeout 3 "Error" 2 "SNA" 1 "Active" 0 "Inactive" ;
VAL_ 2499762532 BATT_14_PrechgContStuckOpen 3 "Error" 2 "SNA" 1 "Active" 0 "Inactive" ;
VAL_ 2499762532 BATT_14_ModuleImbalance 3 "Error" 2 "SNA" 1 "Active" 0 "Inactive" ;
VAL_ 2499762532 BATT_14_ModuleMIA 3 "Error" 2 "SNA" 1 "Active" 0 "Inactive" ;
VAL_ 2499762532 BATT_14_SensePackVoltError 3 "Error" 2 "SNA" 1 "Active" 0 "Inactive" ;
VAL_ 2499762532 BATT_14_SenseLoadVoltError 3 "Error" 2 "SNA" 1 "Active" 0 "Inactive" ;
VAL_ 2499762532 BATT_14_SenseShuntError 3 "Error" 2 "SNA" 1 "Active" 0 "Inactive" ;
VAL_ 2499762532 BATT_14_SenseFcVoltErrorr 3 "Error" 2 "SNA" 1 "Active" 0 "Inactive" ;
VAL_ 2499762532 BATT_14_Placeholder14 3 "Error" 2 "SNA" 1 "Active" 0 "Inactive" ;
VAL_ 2499762532 BATT_15_vBrickOverSev 3 "Error" 2 "SNA" 1 "Active" 0 "Inactive" ;
VAL_ 2499762532 BATT_15_vBrickOverMod 3 "Error" 2 "SNA" 1 "Active" 0 "Inactive" ;
VAL_ 2499762532 BATT_15_vBrickOverWar 3 "Error" 2 "SNA" 1 "Active" 0 "Inactive" ;
VAL_ 2499762532 BATT_15_HostQuiet 3 "Error" 2 "SNA" 1 "Active" 0 "Inactive" ;
VAL_ 2499762532 BATT_15_vBrickUnderMod 3 "Error" 2 "SNA" 1 "Active" 0 "Inactive" ;
VAL_ 2499762532 BATT_15_vBrickUnderWar 3 "Error" 2 "SNA" 1 "Active" 0 "Inactive" ;
VAL_ 2499762532 BATT_15_TempModuleOverSev 3 "Error" 2 "SNA" 1 "Active" 0 "Inactive" ;
VAL_ 2499762532 BATT_15_TempModuleOverMod 3 "Error" 2 "SNA" 1 "Active" 0 "Inactive" ;
VAL_ 2499762532 BATT_15_TempModuleOverWar 3 "Error" 2 "SNA" 1 "Active" 0 "Inactive" ;
VAL_ 2499762532 BATT_15_TempModuleUnderSev 3 "Error" 2 "SNA" 1 "Active" 0 "Inactive" ;
VAL_ 2499762532 BATT_15_TempModuleUnderMod 3 "Error" 2 "SNA" 1 "Active" 0 "Inactive" ;
VAL_ 2499762532 BATT_15_TempModuleUnderWar 3 "Error" 2 "SNA" 1 "Active" 0 "Inactive" ;
VAL_ 2499762532 BATT_15_iOverchargesev 3 "Error" 2 "SNA" 1 "Active" 0 "Inactive" ;
VAL_ 2499762532 BATT_15_iOverdischargesev 3 "Error" 2 "SNA" 1 "Active" 0 "Inactive" ;
VAL_ 2499762532 BATT_15_iOverHardware 3 "Error" 2 "SNA" 1 "Active" 0 "Inactive" ;
VAL_ 2499762532 BATT_15_PosDcContStuckOpen 3 "Error" 2 "SNA" 1 "Active" 0 "Inactive" ;
VAL_ 2499762532 BATT_15_PosDcContWelded 3 "Error" 2 "SNA" 1 "Active" 0 "Inactive" ;
VAL_ 2499762532 BATT_15_NegDcContStuckOpen 3 "Error" 2 "SNA" 1 "Active" 0 "Inactive" ;
VAL_ 2499762532 BATT_15_NegDcContWelded 3 "Error" 2 "SNA" 1 "Active" 0 "Inactive" ;
VAL_ 2499762532 BATT_15_PrechgTooFast 3 "Error" 2 "SNA" 1 "Active" 0 "Inactive" ;
VAL_ 2499762532 BATT_15_PrechgContWelded 3 "Error" 2 "SNA" 1 "Active" 0 "Inactive" ;
VAL_ 2499762532 BATT_15_PrechgTimeout 3 "Error" 2 "SNA" 1 "Active" 0 "Inactive" ;
VAL_ 2499762532 BATT_15_PrechgContStuckOpen 3 "Error" 2 "SNA" 1 "Active" 0 "Inactive" ;
VAL_ 2499762532 BATT_15_ModuleImbalance 3 "Error" 2 "SNA" 1 "Active" 0 "Inactive" ;
VAL_ 2499762532 BATT_15_ModuleMIA 3 "Error" 2 "SNA" 1 "Active" 0 "Inactive" ;
VAL_ 2499762532 BATT_15_SensePackVoltError 3 "Error" 2 "SNA" 1 "Active" 0 "Inactive" ;
VAL_ 2499762532 BATT_15_SenseLoadVoltError 3 "Error" 2 "SNA" 1 "Active" 0 "Inactive" ;
VAL_ 2499762532 BATT_15_SenseShuntError 3 "Error" 2 "SNA" 1 "Active" 0 "Inactive" ;
VAL_ 2499762532 BATT_15_SenseFcVoltErrorr 3 "Error" 2 "SNA" 1 "Active" 0 "Inactive" ;
VAL_ 2499762532 BATT_15_Placeholder14 3 "Error" 2 "SNA" 1 "Active" 0 "Inactive" ;
VAL_ 2499758948 BATT_HVILFault 3 "Error" 2 "SNA" 1 "Active" 0 "Inactive" ;
VAL_ 2499758948 BATT_PackVoltageImbalance 3 "Error" 2 "SNA" 1 "Active" 0 "Inactive" ;
VAL_ 2499758948 BATT_PackMIA 3 "Error" 2 "SNA" 1 "Active" 0 "Inactive" ;
VAL_ 2499758948 BATT_HostQuiet 3 "Error" 2 "SNA" 1 "Active" 0 "Inactive" ;
VAL_ 2499758948 BATT_HostMIA 3 "Error" 2 "SNA" 1 "Active" 0 "Inactive" ;
VAL_ 2499758948 BATT_SystemPrechargeFail 3 "Error" 2 "SNA" 1 "Active" 0 "Inactive" ;
VAL_ 2499758948 BATT_VersionMismatch 3 "Error" 2 "SNA" 1 "Active" 0 "Inactive" ;
VAL_ 2499761508 BATT_Sys_SOHR_Module_Min_V 3 "Error" 2 "SNA" 1 "Invalid" 0 "Valid" ;
VAL_ 2499761508 BATT_Sys_SOHR_Module_Max_V 3 "Error" 2 "SNA" 1 "Invalid" 0 "Valid" ;
VAL_ 2499761508 BATT_Sys_SOHR_Module_Avg_V 3 "Error" 2 "SNA" 1 "Invalid" 0 "Valid" ;
VAL_ 2499760996 BATT_Sys_SOHC_Module_Min_V 3 "Error" 2 "SNA" 1 "Invalid" 0 "Valid" ;
VAL_ 2499760996 BATT_Sys_SOHC_Module_Max_V 3 "Error" 2 "SNA" 1 "Invalid" 0 "Valid" ;
VAL_ 2499760996 BATT_Sys_SOHC_Module_Avg_V 3 "Error" 2 "SNA" 1 "Invalid" 0 "Valid" ;
VAL_ 2499760740 BATT_Cnc_Volt_String_Avg_V 3 "Error" 2 "SNA" 1 "Invalid" 0 "Valid" ;
VAL_ 2499760740 BATT_Cnc_Volt_String_Min_V 3 "Error" 2 "SNA" 1 "Invalid" 0 "Valid" ;
VAL_ 2499760740 BATT_Cnc_Volt_String_Max_V 3 "Error" 2 "SNA" 1 "Invalid" 0 "Valid" ;
VAL_ 2499756388 BATT_Cnc_Temp_Module_Avg_V 3 "Error" 2 "SNA" 1 "Invalid" 0 "Valid" ;
VAL_ 2499756388 BATT_Cnc_Temp_Module_Max_V 3 "Error" 2 "SNA" 1 "Invalid" 0 "Valid" ;
VAL_ 2499756388 BATT_Cnc_Temp_Module_Min_V 3 "Error" 2 "SNA" 1 "Invalid" 0 "Valid" ;
VAL_ 2499757668 BATT_Cnc_SOC_String_MinV 3 "Error" 2 "SNA" 1 "Invalid" 0 "Valid" ;
VAL_ 2499757668 BATT_Cnc_SOC_String_MaxV 3 "Error" 2 "SNA" 1 "Invalid" 0 "Valid" ;
VAL_ 2499757668 BATT_Cnc_SOC_String_AvgV 3 "Error" 2 "SNA" 1 "Invalid" 0 "Valid" ;
VAL_ 2499757668 BATT_Cnc_Energy_SystemV 3 "Error" 2 "SNA" 1 "Invalid" 0 "Valid" ;
VAL_ 2499761764 BATT_Cnc_Volt_Cell_Avg_V 3 "Error" 2 "SNA" 1 "Invalid" 0 "Valid" ;
VAL_ 2499761764 BATT_Cnc_Volt_Cell_Max_V 3 "Error" 2 "SNA" 1 "Invalid" 0 "Valid" ;
VAL_ 2499761764 BATT_Cnc_Volt_Cell_Min_V 3 "Error" 2 "SNA" 1 "Invalid" 0 "Valid" ;
VAL_ 2499760228 BATT_Limit_ChrgrVolt_V 3 "Error" 2 "SNA" 1 "Invalid" 0 "Valid" ;
VAL_ 2499760228 BATT_Limit_ChrgrCrrnt_V 3 "Error" 2 "SNA" 1 "Invalid" 0 "Valid" ;
VAL_ 2499760228 BATT_State_Chrgr 3 "Error" 2 "SNA" 1 "Is Charging" 0 "Not Charging" ;
VAL_ 2499756105 APP_State_ReqMode 4 "FastCharge" 3 "Discharge" 2 "Charge" 1 "Idle" 0 "Off" ;
VAL_ 2499756105 APP_Contactor_Command 3 "Error" 2 "SNA" 1 "Close" 0 "Open" ;
VAL_ 2499756105 APP_Balancing_Enable_F 0 "Balancing not allowed" 1 "Balancing allowed" 2 "SNA" 3 "Error" ;
VAL_ 2499756105 APP_IsoRes_Enable_F 3 "Error" 2 "SNA" 1 "Measurement enabled" 0 "Measurement disabled" ;
VAL_ 2499756132 BATT_SysState 15 "FastCharge" 14 "FastChargeReady" 13 "Cooldown" 12 "Disconnect" 11 "Charge" 10 "Drive" 9 "ExternalIsolationTestCharge" 8 "ExternalIsolationTestDrive" 7 "ConnectChargeStagger" 6 "ConnectChargeBusJoin" 5 "ConnectChargePrecharge" 4 "ConnectDriveStagger" 3 "ConnectDriveBusJoin" 2 "ConnectDrivePrecharge" 1 "StandByReady" 0 "StandByNotReady" ;
VAL_ 2499756132 BATT_Contactor_EmergencyOpen_F 3 "SNA" 2 "Status Not Available" 1 "Emergency Open Active" 0 "Emergency Open Not Active" ;
VAL_ 2499756132 BATT_HVIL_Status 3 "Error" 2 "SNA" 1 "Invalid" 0 "Valid" ;
VAL_ 2499756132 BATT_Balancing_Status 0 "Balancing not active" 1 "Balancing active" 2 "SNA" 3 "Error" ;
VAL_ 2499756132 BATT_State_SysPwrMd 5 "Sleep" 4 "Fault" 3 "Run" 2 "Partial Run" 1 "Idle" 0 "Initialize" ;
VAL_ 2499756644 BATT_Current_String_Min_V 3 "Error" 2 "SNA" 1 "Invalid" 0 "Valid" ;
VAL_ 2499756644 BATT_Current_String_Max_V 3 "Error" 2 "SNA" 1 "Invalid" 0 "Valid" ;
VAL_ 2499756644 BATT_Current_System_V 3 "Error" 2 "SNA" 1 "Invalid" 0 "Valid" ;
VAL_ 2499756900 BATT_Sys_Volt_String_Avg_V 3 "Error" 2 "SNA" 1 "Invalid" 0 "Valid" ;
VAL_ 2499756900 BATT_Sys_Volt_String_Min_V 3 "Error" 2 "SNA" 1 "Invalid" 0 "Valid" ;
VAL_ 2499756900 BATT_Sys_Volt_String_Max_V 3 "Error" 2 "SNA" 1 "Invalid" 0 "Valid" ;
VAL_ 2499757156 BATT_Sys_Volt_Cell_Avg_V 3 "Error" 2 "SNA" 1 "Invalid" 0 "Valid" ;
VAL_ 2499757156 BATT_Sys_Volt_Cell_Max_V 3 "Error" 2 "SNA" 1 "Invalid" 0 "Valid" ;
VAL_ 2499757156 BATT_Sys_Volt_Cell_Min_V 3 "Error" 2 "SNA" 1 "Invalid" 0 "Valid" ;
VAL_ 2499757412 BATT_Sys_SOC_String_Min_V 3 "Error" 2 "SNA" 1 "Invalid" 0 "Valid" ;
VAL_ 2499757412 BATT_Sys_SOC_String_Max_V 3 "Error" 2 "SNA" 1 "Invalid" 0 "Valid" ;
VAL_ 2499757412 BATT_Sys_SOC_String_Avg_V 3 "Error" 2 "SNA" 1 "Invalid" 0 "Valid" ;
VAL_ 2499757412 BATT_Sys_Energy_System_V 3 "Error" 2 "SNA" 1 "Invalid" 0 "Valid" ;
VAL_ 2499757924 BATT_Sys_Temp_Module_Avg_V 3 "Error" 2 "SNA" 1 "Invalid" 0 "Valid" ;
VAL_ 2499757924 BATT_Sys_Temp_Module_Max_V 3 "Error" 2 "SNA" 1 "Invalid" 0 "Valid" ;
VAL_ 2499757924 BATT_Sys_Temp_Module_Min_V 3 "Error" 2 "SNA" 1 "Invalid" 0 "Valid" ;
VAL_ 2499758180 BATT_Limit_DschrgCrrnt_V 3 "Error" 2 "SNA" 1 "Invalid" 0 "Valid" ;
VAL_ 2499758180 BATT_Limit_DschrgPwr_V 3 "Error" 2 "SNA" 1 "Invalid" 0 "Valid" ;
VAL_ 2499758436 BATT_Limit_RegenCrrnt_V 3 "Error" 2 "SNA" 1 "Invalid" 0 "Valid" ;
VAL_ 2499758436 BATT_Limit_RegenPwr_V 3 "Error" 2 "SNA" 1 "Invalid" 0 "Valid" ;
VAL_ 2499769700 BATT_DPP_Data_ID 1 "Batt_Life_Status" 2 "Batt_Capacity" 3 "SocHisto_0To20" 4 "SocHisto_20To40" 5 "SocHisto_40To60" 6 "SocHisto_60To80" 7 "SocHisto_80To100" 8 "20SOC_PowerCap" 9 "50SOC_PowerCap" 10 "80SOC_PowerCap" 11 "Chg_Dchg_Counter" 12 "TEMP_LT_M20" 13 "TEMP_M20_0" 14 "TEMP_0_20" 15 "TEMP_20_40" 16 "TEMP_40_60" 17 "TEMP_GT_60" 18 "Deep_Dchg_Evt_Cnt" 19 "Overchg_Evt_Cnt" 20 "Post_Evt_Status" ;
VAL_ 2499769700 BATT_DPP_Data_Status 0 "Valid" 1 "Invalid / not available" ;
